[part 2 of 2: packages /Cluster to /PDU]
AUTOSAR XML (schema 00048)
package /Cluster  (continued)
  can cluster KAMA_FP_EPT_0303: baudrate=500000, protocol-name=CAN  # KAMA_FP_EPT_0409
    can physical channel CHNL: comm-connectors=CN_KAMA_FP_EPT_0303
      frame AllFunctionRequest_oKAMA_FP_EPT_0303: id 0x7FF, to VCU, frame-length=8, can-addressing-mode=STANDARD
        n pdu AllFunctionRequest_Tp_oKAMA_FP_EPT_0303: length=8
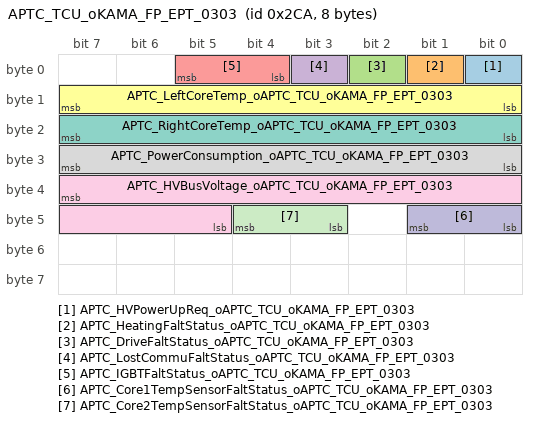
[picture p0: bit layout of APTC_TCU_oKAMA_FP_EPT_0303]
      frame APTC_TCU_oKAMA_FP_EPT_0303: id 0x2CA, to VCU, frame-length=8, can-addressing-mode=STANDARD
        pdu APTC_TCU_oKAMA_FP_EPT_0303: length=8, minimum-delay=0, transmission-mode-false-timing=cyclic-timing={time-offset=0, time-period=0.1}, transmission-mode-true-timing=cyclic-timing={time-offset=0, time-period=0.1}, unused-bit-pattern=0
          signal APTC_HVPowerUpReq_oAPTC_TCU_oKAMA_FP_EPT_0303: start 0, 1 bit, big-endian, i-signal-type=PRIMITIVE, init-value=0, base-type=boolean, compu-method=CM_APTC_HVPowerUpReq, data-constr=DC_APTC_HVPowerUpReq, transfer-property=PENDING, to VCU  # APTC high voltage power supply off line request APTC ¸ßÑ¹ÏÂÏßÇëÇó
          signal APTC_HeatingFaltStatus_oAPTC_TCU_oKAMA_FP_EPT_0303: start 1, 1 bit, big-endian, i-signal-type=PRIMITIVE, init-value=0, base-type=boolean, compu-method=CM_APTC_HeatingFaltStatus, data-constr=DC_APTC_HeatingFaltStatus, transfer-property=PENDING, to VCU  # ptc heater core status
          signal APTC_DriveFaltStatus_oAPTC_TCU_oKAMA_FP_EPT_0303: start 2, 1 bit, big-endian, i-signal-type=PRIMITIVE, init-value=0, base-type=boolean, compu-method=CM_APTC_DriveFaltStatus, data-constr=DC_APTC_DriveFaltStatus, transfer-property=PENDING, to VCU  # ptc driver status
          signal APTC_LostCommuFaltStatus_oAPTC_TCU_oKAMA_FP_EPT_0303: start 3, 1 bit, big-endian, i-signal-type=PRIMITIVE, init-value=0, base-type=boolean, compu-method=CM_APTC_LostCommuFaltStatus, data-constr=DC_APTC_LostCommuFaltStatus, transfer-property=PENDING, to VCU  # TCU signal lost
          signal APTC_IGBTFaltStatus_oAPTC_TCU_oKAMA_FP_EPT_0303: start 5, 2 bit, big-endian, i-signal-type=PRIMITIVE, init-value=0, base-type=uint8, compu-method=CM_APTC_IGBTFaltStatus, data-constr=DC_APTC_IGBTFaltStatus, transfer-property=PENDING, to VCU  # IGBT failure
          signal APTC_LeftCoreTemp_oAPTC_TCU_oKAMA_FP_EPT_0303: start 15, 8 bit, big-endian, i-signal-type=PRIMITIVE, init-value=40, base-type=uint8, compu-method=CM_APTC_LeftCoreTemp, data-constr=DC_APTC_LeftCoreTemp, unit=U_deg, transfer-property=PENDING, to VCU  # Left core sensor temperature ×ó²àÐ¾ÌåÎÂ¶È´«¸ÐÆ÷ÎÂ¶È
          signal APTC_RightCoreTemp_oAPTC_TCU_oKAMA_FP_EPT_0303: start 23, 8 bit, big-endian, i-signal-type=PRIMITIVE, init-value=40, base-type=uint8, compu-method=CM_APTC_RightCoreTemp, data-constr=DC_APTC_RightCoreTemp, unit=U_deg, transfer-property=PENDING, to VCU  # Right core sensor temperature ÓÒ²àÐ¾ÌåÎÂ¶È´«¸ÐÆ÷ÎÂ¶È
          signal APTC_PowerConsumption_oAPTC_TCU_oKAMA_FP_EPT_0303: start 31, 8 bit, big-endian, i-signal-type=PRIMITIVE, init-value=0, base-type=uint8, compu-method=CM_APTC_PowerConsumption, data-constr=DC_APTC_PowerConsumption, unit=U_KW, transfer-property=PENDING, to VCU  # APTC OutPut Power APTC Êä³ö¹¦ÂÊ
          signal APTC_HVBusVoltage_oAPTC_TCU_oKAMA_FP_EPT_0303: start 39, 11 bit, big-endian, i-signal-type=PRIMITIVE, init-value=0, base-type=uint16, compu-method=CM_APTC_HVBusVoltage, data-constr=DC_APTC_HVBusVoltage, unit=U_V, transfer-property=PENDING, to VCU  # HV voltage ¸ßÑ¹µçÑ¹Öµ
          signal APTC_Core1TempSensorFaltStatus_oAPTC_TCU_oKAMA_FP_EPT_0303: start 41, 2 bit, big-endian, i-signal-type=PRIMITIVE, init-value=0, base-type=uint8, compu-method=CM_APTC_Core1TempSensorFaltStatus, data-constr=DC_APTC_Core1TempSensorFaltStatus, transfer-property=PENDING, to VCU  # Left core sensor temperature error
          signal APTC_Core2TempSensorFaltStatus_oAPTC_TCU_oKAMA_FP_EPT_0303: start 44, 2 bit, big-endian, i-signal-type=PRIMITIVE, init-value=0, base-type=uint8, compu-method=CM_APTC_Core2TempSensorFaltStatus, data-constr=DC_APTC_Core2TempSensorFaltStatus, transfer-property=PENDING, to VCU  # Right core sensor temperature error
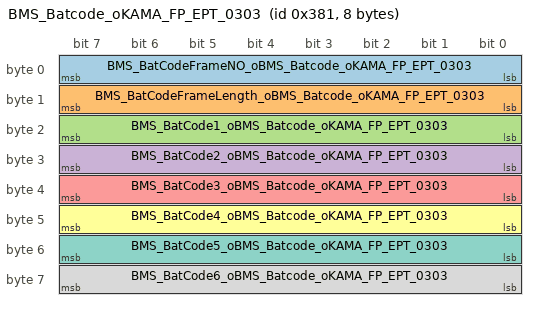
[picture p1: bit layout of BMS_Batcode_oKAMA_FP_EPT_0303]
      frame BMS_Batcode_oKAMA_FP_EPT_0303: id 0x381, to VCU, frame-length=8, can-addressing-mode=STANDARD
        pdu BMS_Batcode_oKAMA_FP_EPT_0303: length=8, minimum-delay=0, transmission-mode-false-timing=cyclic-timing={time-offset=0, time-period=1}, transmission-mode-true-timing=cyclic-timing={time-offset=0, time-period=1}, unused-bit-pattern=0
          signal BMS_BatCodeFrameNO_oBMS_Batcode_oKAMA_FP_EPT_0303: start 7, 8 bit, big-endian, i-signal-type=PRIMITIVE, init-value=0, base-type=uint8, compu-method=CM_BMS_BatCodeFrameNO, data-constr=DC_BMS_BatCodeFrameNO, transfer-property=PENDING, to VCU  # BatteryCodeNumber
          signal BMS_BatCodeFrameLength_oBMS_Batcode_oKAMA_FP_EPT_0303: start 15, 8 bit, big-endian, i-signal-type=PRIMITIVE, init-value=0, base-type=uint8, compu-method=CM_BMS_BatCodeFrameLength, data-constr=DC_BMS_BatCodeFrameLength, transfer-property=PENDING, to VCU  # Length of battery code
          signal BMS_BatCode1_oBMS_Batcode_oKAMA_FP_EPT_0303: start 23, 8 bit, big-endian, i-signal-type=PRIMITIVE, init-value=0, base-type=uint8, compu-method=CM_BMS_BatCode1, data-constr=DC_BMS_BatCode1, transfer-property=PENDING, to VCU
          signal BMS_BatCode2_oBMS_Batcode_oKAMA_FP_EPT_0303: start 31, 8 bit, big-endian, i-signal-type=PRIMITIVE, init-value=0, base-type=uint8, compu-method=CM_BMS_BatCode2, data-constr=DC_BMS_BatCode2, transfer-property=PENDING, to VCU
          signal BMS_BatCode3_oBMS_Batcode_oKAMA_FP_EPT_0303: start 39, 8 bit, big-endian, i-signal-type=PRIMITIVE, init-value=0, base-type=uint8, compu-method=CM_BMS_BatCode3, data-constr=DC_BMS_BatCode3, transfer-property=PENDING, to VCU
          signal BMS_BatCode4_oBMS_Batcode_oKAMA_FP_EPT_0303: start 47, 8 bit, big-endian, i-signal-type=PRIMITIVE, init-value=0, base-type=uint8, compu-method=CM_BMS_BatCode4, data-constr=DC_BMS_BatCode4, transfer-property=PENDING, to VCU
          signal BMS_BatCode5_oBMS_Batcode_oKAMA_FP_EPT_0303: start 55, 8 bit, big-endian, i-signal-type=PRIMITIVE, init-value=0, base-type=uint8, compu-method=CM_BMS_BatCode5, data-constr=DC_BMS_BatCode5, transfer-property=PENDING, to VCU
          signal BMS_BatCode6_oBMS_Batcode_oKAMA_FP_EPT_0303: start 63, 8 bit, big-endian, i-signal-type=PRIMITIVE, init-value=0, base-type=uint8, compu-method=CM_BMS_BatCode6, data-constr=DC_BMS_BatCode6, transfer-property=PENDING, to VCU
      frame BMS_BatInfor1_oKAMA_FP_EPT_0303: id 0xAF, to VCU, frame-length=8, can-addressing-mode=STANDARD
        pdu BMS_BatInfor1_oKAMA_FP_EPT_0303: length=8, minimum-delay=0, transmission-mode-false-timing=cyclic-timing={time-offset=0, time-period=0.02}, transmission-mode-true-timing=cyclic-timing={time-offset=0, time-period=0.02}, unused-bit-pattern=0
          signal BMS_BattVolt_oBMS_BatInfor1_oKAMA_FP_EPT_0303: start 7, 14 bit, big-endian, i-signal-type=PRIMITIVE, init-value=0, base-type=uint16, compu-method=CM_BMS_BattVolt, data-constr=DC_BMS_BattVolt, transfer-property=PENDING, to VCU  # the voltage of dclink from BMS sideµç³ØÄ¸ÏßµçÑ¹
          signal BMS_BattCurr_oBMS_BatInfor1_oKAMA_FP_EPT_0303: start 23, 15 bit, big-endian, i-signal-type=PRIMITIVE, init-value=10240, base-type=uint16, compu-method=CM_BMS_BattCurr, data-constr=DC_BMS_BattCurr, transfer-property=PENDING, to VCU  # the current of dclink from BMS sideµç³ØÄ¸ÏßµçÁ÷
          signal MessageCounter_AF_oBMS_BatInfor1_oKAMA_FP_EPT_0303: start 51, 4 bit, big-endian, i-signal-type=PRIMITIVE, init-value=0, base-type=uint8, compu-method=CM_MessageCounter_AF, data-constr=DC_MessageCounter_AF, transfer-property=PENDING, to VCU  # Message counter signal for frame
          signal Checksum_AF_oBMS_BatInfor1_oKAMA_FP_EPT_0303: start 63, 8 bit, big-endian, i-signal-type=PRIMITIVE, init-value=0, base-type=uint8, compu-method=CM_Checksum_AF, data-constr=DC_Checksum_AF, transfer-property=PENDING, to VCU  # Checksum signal for frame
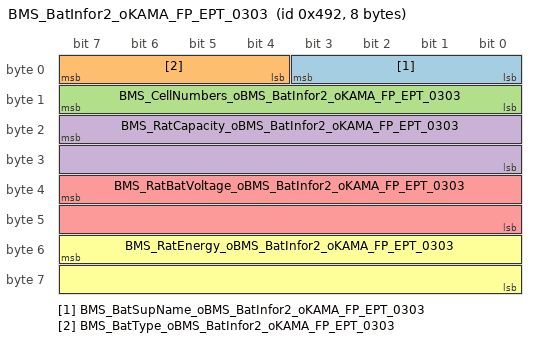
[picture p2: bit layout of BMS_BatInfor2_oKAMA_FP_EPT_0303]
      frame BMS_BatInfor2_oKAMA_FP_EPT_0303: id 0x492, to VCU, frame-length=8, can-addressing-mode=STANDARD
        pdu BMS_BatInfor2_oKAMA_FP_EPT_0303: length=8, minimum-delay=0, transmission-mode-false-timing=cyclic-timing={time-offset=0, time-period=1}, transmission-mode-true-timing=cyclic-timing={time-offset=0, time-period=1}, unused-bit-pattern=0
          signal BMS_BatSupName_oBMS_BatInfor2_oKAMA_FP_EPT_0303: start 3, 4 bit, big-endian, i-signal-type=PRIMITIVE, init-value=0, base-type=uint8, compu-method=CM_BMS_BatSupName, data-constr=DC_BMS_BatSupName, transfer-property=PENDING, to VCU  # Battery supplier name
          signal BMS_BatType_oBMS_BatInfor2_oKAMA_FP_EPT_0303: start 7, 4 bit, big-endian, i-signal-type=PRIMITIVE, init-value=0, base-type=uint8, compu-method=CM_BMS_BatType, data-constr=DC_BMS_BatType, transfer-property=PENDING, to VCU  # Battery type
          signal BMS_CellNumbers_oBMS_BatInfor2_oKAMA_FP_EPT_0303: start 15, 8 bit, big-endian, i-signal-type=PRIMITIVE, init-value=0, base-type=uint8, compu-method=CM_BMS_CellNumbers, data-constr=DC_BMS_CellNumbers, transfer-property=PENDING, to VCU  # Sum of cell in pack
          signal BMS_RatCapacity_oBMS_BatInfor2_oKAMA_FP_EPT_0303: start 23, 16 bit, big-endian, i-signal-type=PRIMITIVE, init-value=0, base-type=uint16, compu-method=CM_BMS_RatCapacity, data-constr=DC_BMS_RatCapacity, unit=U_Ah, transfer-property=PENDING, to VCU  # Rated capacity of power battery system
          signal BMS_RatBatVoltage_oBMS_BatInfor2_oKAMA_FP_EPT_0303: start 39, 16 bit, big-endian, i-signal-type=PRIMITIVE, init-value=0, base-type=uint16, compu-method=CM_BMS_RatBatVoltage, data-constr=DC_BMS_RatBatVoltage, unit=U_V, transfer-property=PENDING, to VCU  # Rated Voltage of power battery system
          signal BMS_RatEnergy_oBMS_BatInfor2_oKAMA_FP_EPT_0303: start 55, 16 bit, big-endian, i-signal-type=PRIMITIVE, init-value=0, base-type=uint16, compu-method=CM_BMS_RatEnergy, data-constr=DC_BMS_RatEnergy, unit=U_KWH, transfer-property=PENDING, to VCU  # Nominal total energy of power battery
      frame BMS_CellVoltage1_oKAMA_FP_EPT_0303: id 0x29A, to VCU, frame-length=8, can-addressing-mode=STANDARD
        pdu BMS_CellVoltage1_oKAMA_FP_EPT_0303: length=8, minimum-delay=0, transmission-mode-false-timing=cyclic-timing={time-offset=0, time-period=0.1}, transmission-mode-true-timing=cyclic-timing={time-offset=0, time-period=0.1}, unused-bit-pattern=0
          signal BMS_MaxCellVoltage_oBMS_CellVoltage1_oKAMA_FP_EPT_0303: start 7, 16 bit, big-endian, i-signal-type=PRIMITIVE, init-value=0, base-type=uint16, compu-method=CM_BMS_MaxCellVoltage, data-constr=DC_BMS_MaxCellVoltage, unit=U_V, transfer-property=PENDING, to VCU  # The Maximal Cell Voltage
          signal BMS_MinCellVoltage_oBMS_CellVoltage1_oKAMA_FP_EPT_0303: start 23, 16 bit, big-endian, i-signal-type=PRIMITIVE, init-value=0, base-type=uint16, compu-method=CM_BMS_MinCellVoltage, data-constr=DC_BMS_MinCellVoltage, unit=U_V, transfer-property=PENDING, to VCU  # The Minimal Cell Voltage
          signal BMS_MinCellVoltageModlueNO_oBMS_CellVoltage1_oKAMA_FP_EPT_0303: start 35, 4 bit, big-endian, i-signal-type=PRIMITIVE, init-value=0, base-type=uint8, compu-method=CM_BMS_MinCellVoltageModlueNO, data-constr=DC_BMS_MinCellVoltageModlueNO, transfer-property=PENDING, to VCU  # Minimal Cell Voltage module NO
          signal BMS_MaxCellVoltageModuleNO_oBMS_CellVoltage1_oKAMA_FP_EPT_0303: start 39, 4 bit, big-endian, i-signal-type=PRIMITIVE, init-value=0, base-type=uint8, compu-method=CM_BMS_MaxCellVoltageModuleNO, data-constr=DC_BMS_MaxCellVoltageModuleNO, transfer-property=PENDING, to VCU  # Maximal Cell Voltage module NO
          signal BMS_MaxCellVoltageNO_oBMS_CellVoltage1_oKAMA_FP_EPT_0303: start 47, 8 bit, big-endian, i-signal-type=PRIMITIVE, init-value=0, base-type=uint8, compu-method=CM_BMS_MaxCellVoltageNO, data-constr=DC_BMS_MaxCellVoltageNO, transfer-property=PENDING, to VCU  # The Maximal Cell Voltage NO
          signal BMS_MinCellVoltageNO_oBMS_CellVoltage1_oKAMA_FP_EPT_0303: start 55, 8 bit, big-endian, i-signal-type=PRIMITIVE, init-value=0, base-type=uint8, compu-method=CM_BMS_MinCellVoltageNO, data-constr=DC_BMS_MinCellVoltageNO, transfer-property=PENDING, to VCU  # The Minimal Cell Voltage NO
      frame BMS_Charge1_oKAMA_FP_EPT_0303: id 0x295, to VCU, frame-length=8, can-addressing-mode=STANDARD
        pdu BMS_Charge1_oKAMA_FP_EPT_0303: length=8, minimum-delay=0, transmission-mode-false-timing=cyclic-timing={time-offset=0, time-period=0.1}, transmission-mode-true-timing=cyclic-timing={time-offset=0, time-period=0.1}, unused-bit-pattern=0
          signal BMS_RemChagTime_oBMS_Charge1_oKAMA_FP_EPT_0303: start 7, 16 bit, big-endian, i-signal-type=PRIMITIVE, init-value=0, base-type=uint16, compu-method=CM_BMS_RemChagTime, data-constr=DC_BMS_RemChagTime, unit=U_Min, transfer-property=PENDING, to VCU  # Remaining charging time prediction in minute
          signal BMS_MaxChagVoltage_oBMS_Charge1_oKAMA_FP_EPT_0303: start 23, 16 bit, big-endian, i-signal-type=PRIMITIVE, init-value=0, base-type=uint16, compu-method=CM_BMS_MaxChagVoltage, data-constr=DC_BMS_MaxChagVoltage, unit=U_V, transfer-property=PENDING, to VCU  # Maximum allowable charging voltage
          signal BMS_AllowChagCurrent_oBMS_Charge1_oKAMA_FP_EPT_0303: start 55, 16 bit, big-endian, i-signal-type=PRIMITIVE, init-value=10000, base-type=uint16, compu-method=CM_BMS_AllowChagCurrent, data-constr=DC_BMS_AllowChagCurrent, unit=U_A, transfer-property=PENDING, to VCU  # Maximum allowable charging current
      frame BMS_ChargeEnergy_oKAMA_FP_EPT_0303: id 0x493, to VCU, frame-length=8, can-addressing-mode=STANDARD
        pdu BMS_ChargeEnergy_oKAMA_FP_EPT_0303: length=8, minimum-delay=0, transmission-mode-false-timing=cyclic-timing={time-offset=0, time-period=1}, transmission-mode-true-timing=cyclic-timing={time-offset=0, time-period=1}, unused-bit-pattern=0
          signal BMS_SingChgkwh_oBMS_ChargeEnergy_oKAMA_FP_EPT_0303: start 7, 8 bit, big-endian, i-signal-type=PRIMITIVE, init-value=0, base-type=uint8, compu-method=CM_BMS_SingChgkwh, data-constr=DC_BMS_SingChgkwh, unit=U_KWH, transfer-property=PENDING, to VCU  # Single charged electric quantity (charger online)
          signal BMS_SumChgkwh_oBMS_ChargeEnergy_oKAMA_FP_EPT_0303: start 15, 24 bit, big-endian, i-signal-type=PRIMITIVE, init-value=0, base-type=uint32, compu-method=CM_BMS_SumChgkwh, data-constr=DC_BMS_SumChgkwh, unit=U_KWH, transfer-property=PENDING, to VCU  # Accumulated charged electric quantity
          signal BMS_BatChagSum_oBMS_ChargeEnergy_oKAMA_FP_EPT_0303: start 39, 16 bit, big-endian, i-signal-type=PRIMITIVE, init-value=0, base-type=uint16, compu-method=CM_BMS_BatChagSum, data-constr=DC_BMS_BatChagSum, transfer-property=PENDING, to VCU  # Sum of how many cycle for battery charged
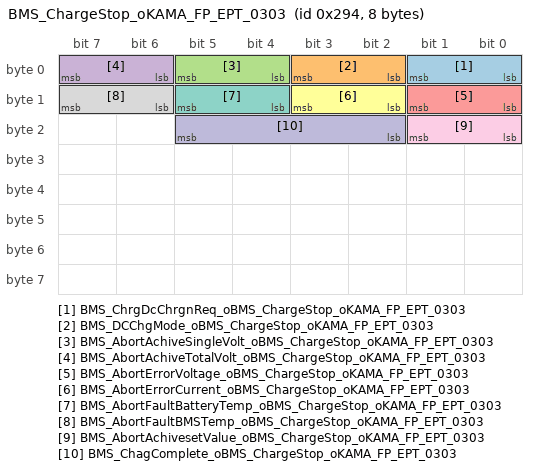
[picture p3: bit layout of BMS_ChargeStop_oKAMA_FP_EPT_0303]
      frame BMS_ChargeStop_oKAMA_FP_EPT_0303: id 0x294, to VCU, frame-length=8, can-addressing-mode=STANDARD
        pdu BMS_ChargeStop_oKAMA_FP_EPT_0303: length=8, minimum-delay=0, transmission-mode-false-timing=cyclic-timing={time-offset=0, time-period=0.1}, transmission-mode-true-timing=cyclic-timing={time-offset=0, time-period=0.1}, unused-bit-pattern=0
          signal BMS_ChrgDcChrgnReq_oBMS_ChargeStop_oKAMA_FP_EPT_0303: start 1, 2 bit, big-endian, i-signal-type=PRIMITIVE, init-value=0, base-type=uint8, compu-method=CM_BMS_ChrgDcChrgnReq, data-constr=DC_BMS_ChrgDcChrgnReq, transfer-property=PENDING, to VCU
          signal BMS_DCChgMode_oBMS_ChargeStop_oKAMA_FP_EPT_0303: start 3, 2 bit, big-endian, i-signal-type=PRIMITIVE, init-value=0, base-type=uint8, compu-method=CM_BMS_DCChgMode, data-constr=DC_BMS_DCChgMode, transfer-property=PENDING, to VCU
          signal BMS_AbortAchiveSingleVolt_oBMS_ChargeStop_oKAMA_FP_EPT_0303: start 5, 2 bit, big-endian, i-signal-type=PRIMITIVE, init-value=0, base-type=uint8, compu-method=CM_BMS_AbortAchiveSingleVolt, data-constr=DC_BMS_AbortAchiveSingleVolt, transfer-property=PENDING, to VCU
          signal BMS_AbortAchiveTotalVolt_oBMS_ChargeStop_oKAMA_FP_EPT_0303: start 7, 2 bit, big-endian, i-signal-type=PRIMITIVE, init-value=0, base-type=uint8, compu-method=CM_BMS_AbortAchiveTotalVolt, data-constr=DC_BMS_AbortAchiveTotalVolt, transfer-property=PENDING, to VCU
          signal BMS_AbortErrorVoltage_oBMS_ChargeStop_oKAMA_FP_EPT_0303: start 9, 2 bit, big-endian, i-signal-type=PRIMITIVE, init-value=0, base-type=uint8, compu-method=CM_BMS_AbortErrorVoltage, data-constr=DC_BMS_AbortErrorVoltage, transfer-property=PENDING, to VCU
          signal BMS_AbortErrorCurrent_oBMS_ChargeStop_oKAMA_FP_EPT_0303: start 11, 2 bit, big-endian, i-signal-type=PRIMITIVE, init-value=0, base-type=uint8, compu-method=CM_BMS_AbortErrorCurrent, data-constr=DC_BMS_AbortErrorCurrent, transfer-property=PENDING, to VCU
          signal BMS_AbortFaultBatteryTemp_oBMS_ChargeStop_oKAMA_FP_EPT_0303: start 13, 2 bit, big-endian, i-signal-type=PRIMITIVE, init-value=0, base-type=uint8, compu-method=CM_BMS_AbortFaultBatteryTemp, data-constr=DC_BMS_AbortFaultBatteryTemp, transfer-property=PENDING, to VCU
          signal BMS_AbortFaultBMSTemp_oBMS_ChargeStop_oKAMA_FP_EPT_0303: start 15, 2 bit, big-endian, i-signal-type=PRIMITIVE, init-value=0, base-type=uint8, compu-method=CM_BMS_AbortFaultBMSTemp, data-constr=DC_BMS_AbortFaultBMSTemp, transfer-property=PENDING, to VCU
          signal BMS_AbortAchivesetValue_oBMS_ChargeStop_oKAMA_FP_EPT_0303: start 17, 2 bit, big-endian, i-signal-type=PRIMITIVE, init-value=0, base-type=uint8, compu-method=CM_BMS_AbortAchivesetValue, data-constr=DC_BMS_AbortAchivesetValue, transfer-property=PENDING, to VCU
          signal BMS_ChagComplete_oBMS_ChargeStop_oKAMA_FP_EPT_0303: start 21, 4 bit, big-endian, i-signal-type=PRIMITIVE, init-value=0, base-type=uint8, compu-method=CM_BMS_ChagComplete, data-constr=DC_BMS_ChagComplete, transfer-property=PENDING, to VCU
      frame BMS_CurrentLimit_oKAMA_FP_EPT_0303: id 0x296, to VCU, frame-length=8, can-addressing-mode=STANDARD
        pdu BMS_CurrentLimit_oKAMA_FP_EPT_0303: length=8, minimum-delay=0, transmission-mode-false-timing=cyclic-timing={time-offset=0, time-period=0.1}, transmission-mode-true-timing=cyclic-timing={time-offset=0, time-period=0.1}, unused-bit-pattern=0
          signal BMS_FeedbackCurr_oBMS_CurrentLimit_oKAMA_FP_EPT_0303: start 7, 16 bit, big-endian, i-signal-type=PRIMITIVE, init-value=10000, base-type=uint16, compu-method=CM_BMS_FeedbackCurr, data-constr=DC_BMS_FeedbackCurr, unit=U_A, transfer-property=PENDING, to VCU  # Maximum feed back charging current(30S)
          signal BMS_DisChgCurr_oBMS_CurrentLimit_oKAMA_FP_EPT_0303: start 39, 16 bit, big-endian, i-signal-type=PRIMITIVE, init-value=10000, base-type=uint16, compu-method=CM_BMS_DisChgCurr, data-constr=DC_BMS_DisChgCurr, unit=U_A, transfer-property=PENDING, to VCU  # Constant discharging current
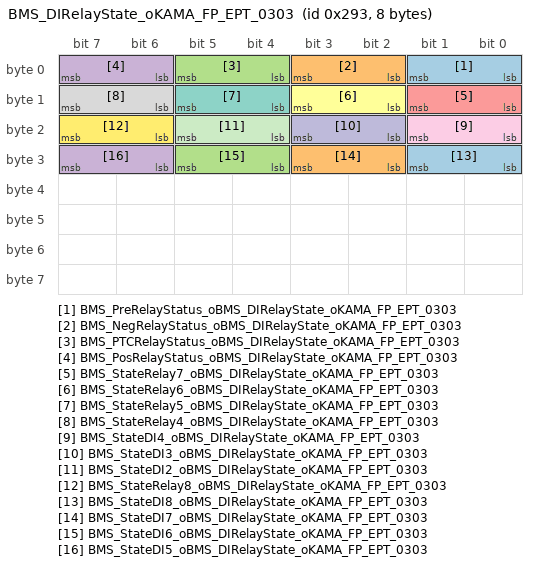
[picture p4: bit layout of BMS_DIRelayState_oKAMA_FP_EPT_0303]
      frame BMS_DIRelayState_oKAMA_FP_EPT_0303: id 0x293, to VCU, frame-length=8, can-addressing-mode=STANDARD
        pdu BMS_DIRelayState_oKAMA_FP_EPT_0303: length=8, minimum-delay=0, transmission-mode-false-timing=cyclic-timing={time-offset=0, time-period=0.1}, transmission-mode-true-timing=cyclic-timing={time-offset=0, time-period=0.1}, unused-bit-pattern=0
          signal BMS_PreRelayStatus_oBMS_DIRelayState_oKAMA_FP_EPT_0303: start 1, 2 bit, big-endian, i-signal-type=PRIMITIVE, init-value=0, base-type=uint8, compu-method=CM_BMS_PreRelayStatus, data-constr=DC_BMS_PreRelayStatus, transfer-property=PENDING, to VCU  # State of precharge relay status
          signal BMS_NegRelayStatus_oBMS_DIRelayState_oKAMA_FP_EPT_0303: start 3, 2 bit, big-endian, i-signal-type=PRIMITIVE, init-value=0, base-type=uint8, compu-method=CM_BMS_NegRelayStatus, data-constr=DC_BMS_NegRelayStatus, transfer-property=PENDING, to VCU  # State of negtive relay status
          signal BMS_PTCRelayStatus_oBMS_DIRelayState_oKAMA_FP_EPT_0303: start 5, 2 bit, big-endian, i-signal-type=PRIMITIVE, init-value=0, base-type=uint8, compu-method=CM_BMS_PTCRelayStatus, data-constr=DC_BMS_PTCRelayStatus, transfer-property=PENDING, to VCU  # the status of PTC relay from BMS sideµç³ØPTC¼ÌµçÆ÷×´Ì¬
          signal BMS_PosRelayStatus_oBMS_DIRelayState_oKAMA_FP_EPT_0303: start 7, 2 bit, big-endian, i-signal-type=PRIMITIVE, init-value=0, base-type=uint8, compu-method=CM_BMS_PosRelayStatus, data-constr=DC_BMS_PosRelayStatus, transfer-property=PENDING, to VCU  # State of positive relay status
          signal BMS_StateRelay7_oBMS_DIRelayState_oKAMA_FP_EPT_0303: start 9, 2 bit, big-endian, i-signal-type=PRIMITIVE, init-value=0, base-type=uint8, compu-method=CM_BMS_StateRelay7, data-constr=DC_BMS_StateRelay7, transfer-property=PENDING, to VCU  # State of relay 7
          signal BMS_StateRelay6_oBMS_DIRelayState_oKAMA_FP_EPT_0303: start 11, 2 bit, big-endian, i-signal-type=PRIMITIVE, init-value=0, base-type=uint8, compu-method=CM_BMS_StateRelay6, data-constr=DC_BMS_StateRelay6, transfer-property=PENDING, to VCU  # State of relay 6
          signal BMS_StateRelay5_oBMS_DIRelayState_oKAMA_FP_EPT_0303: start 13, 2 bit, big-endian, i-signal-type=PRIMITIVE, init-value=0, base-type=uint8, compu-method=CM_BMS_StateRelay5, data-constr=DC_BMS_StateRelay5, transfer-property=PENDING, to VCU  # State of relay 5
          signal BMS_StateRelay4_oBMS_DIRelayState_oKAMA_FP_EPT_0303: start 15, 2 bit, big-endian, i-signal-type=PRIMITIVE, init-value=0, base-type=uint8, compu-method=CM_BMS_StateRelay4, data-constr=DC_BMS_StateRelay4, transfer-property=PENDING, to VCU  # State of relay 4
          signal BMS_StateDI4_oBMS_DIRelayState_oKAMA_FP_EPT_0303: start 17, 2 bit, big-endian, i-signal-type=PRIMITIVE, init-value=0, base-type=uint8, compu-method=CM_BMS_StateDI4, data-constr=DC_BMS_StateDI4, transfer-property=PENDING, to VCU  # State of DI 4
          signal BMS_StateDI3_oBMS_DIRelayState_oKAMA_FP_EPT_0303: start 19, 2 bit, big-endian, i-signal-type=PRIMITIVE, init-value=0, base-type=uint8, compu-method=CM_BMS_StateDI3, data-constr=DC_BMS_StateDI3, transfer-property=PENDING, to VCU  # State of DI 3
          signal BMS_StateDI2_oBMS_DIRelayState_oKAMA_FP_EPT_0303: start 21, 2 bit, big-endian, i-signal-type=PRIMITIVE, init-value=0, base-type=uint8, compu-method=CM_BMS_StateDI2, data-constr=DC_BMS_StateDI2, transfer-property=PENDING, to VCU  # State of DI 2
          signal BMS_StateRelay8_oBMS_DIRelayState_oKAMA_FP_EPT_0303: start 23, 2 bit, big-endian, i-signal-type=PRIMITIVE, init-value=0, base-type=uint8, compu-method=CM_BMS_StateRelay8, data-constr=DC_BMS_StateRelay8, transfer-property=PENDING, to VCU  # State of relay 8
          signal BMS_StateDI8_oBMS_DIRelayState_oKAMA_FP_EPT_0303: start 25, 2 bit, big-endian, i-signal-type=PRIMITIVE, init-value=0, base-type=uint8, compu-method=CM_BMS_StateDI8, data-constr=DC_BMS_StateDI8, transfer-property=PENDING, to VCU  # State of DI 8
          signal BMS_StateDI7_oBMS_DIRelayState_oKAMA_FP_EPT_0303: start 27, 2 bit, big-endian, i-signal-type=PRIMITIVE, init-value=0, base-type=uint8, compu-method=CM_BMS_StateDI7, data-constr=DC_BMS_StateDI7, transfer-property=PENDING, to VCU  # State of DI 7
          signal BMS_StateDI6_oBMS_DIRelayState_oKAMA_FP_EPT_0303: start 29, 2 bit, big-endian, i-signal-type=PRIMITIVE, init-value=0, base-type=uint8, compu-method=CM_BMS_StateDI6, data-constr=DC_BMS_StateDI6, transfer-property=PENDING, to VCU  # State of DI 6
          signal BMS_StateDI5_oBMS_DIRelayState_oKAMA_FP_EPT_0303: start 31, 2 bit, big-endian, i-signal-type=PRIMITIVE, init-value=0, base-type=uint8, compu-method=CM_BMS_StateDI5, data-constr=DC_BMS_StateDI5, transfer-property=PENDING, to VCU  # State of DI 5
      frame BMS_DisChargeEnergy_oKAMA_FP_EPT_0303: id 0x494, to VCU, frame-length=8, can-addressing-mode=STANDARD
        pdu BMS_DisChargeEnergy_oKAMA_FP_EPT_0303: length=8, minimum-delay=0, transmission-mode-false-timing=cyclic-timing={time-offset=0, time-period=0.1}, transmission-mode-true-timing=cyclic-timing={time-offset=0, time-period=0.1}, unused-bit-pattern=0
          signal BMS_SumDisChgkwh_oBMS_DisChargeEnergy_oKAMA_FP_EPT_0303: start 7, 24 bit, big-endian, i-signal-type=PRIMITIVE, init-value=0, base-type=uint32, compu-method=CM_BMS_SumDisChgkwh, data-constr=DC_BMS_SumDisChgkwh, unit=U_KWH, transfer-property=PENDING, to VCU  # Accumulated discharged electric quantity
          signal BMS_RemainCapacity_oBMS_DisChargeEnergy_oKAMA_FP_EPT_0303: start 31, 8 bit, big-endian, i-signal-type=PRIMITIVE, init-value=0, base-type=uint8, compu-method=CM_BMS_RemainCapacity, data-constr=DC_BMS_RemainCapacity, unit=U_Ah, transfer-property=PENDING, to VCU  # Real-time remaining battery capacity
      frame BMS_ErrorInfo1_oKAMA_FP_EPT_0303: id 0x382, to VCU, frame-length=8, can-addressing-mode=STANDARD
        pdu BMS_ErrorInfo1_oKAMA_FP_EPT_0303: length=8, minimum-delay=0, transmission-mode-false-timing=cyclic-timing={time-offset=0, time-period=0.2}, transmission-mode-true-timing=cyclic-timing={time-offset=0, time-period=0.2}, unused-bit-pattern=0
          signal BMS_ErrorCellLowTemp_oBMS_ErrorInfo1_oKAMA_FP_EPT_0303: start 1, 2 bit, big-endian, i-signal-type=PRIMITIVE, init-value=0, base-type=uint8, compu-method=CM_BMS_ErrorCellLowTemp, data-constr=DC_BMS_ErrorCellLowTemp, transfer-property=PENDING, to VCU  # Cell temperature under limit
          signal BMS_ErrorCellHighTemp_oBMS_ErrorInfo1_oKAMA_FP_EPT_0303: start 3, 2 bit, big-endian, i-signal-type=PRIMITIVE, init-value=0, base-type=uint8, compu-method=CM_BMS_ErrorCellHighTemp, data-constr=DC_BMS_ErrorCellHighTemp, transfer-property=PENDING, to VCU  # Cell temperature over limit
          signal BMS_ErrorCellUnderVolt_oBMS_ErrorInfo1_oKAMA_FP_EPT_0303: start 5, 2 bit, big-endian, i-signal-type=PRIMITIVE, init-value=0, base-type=uint8, compu-method=CM_BMS_ErrorCellUnderVolt, data-constr=DC_BMS_ErrorCellUnderVolt, transfer-property=PENDING, to VCU  # Cell voltage under limit
          signal BMS_ErrorCellOverVolt_oBMS_ErrorInfo1_oKAMA_FP_EPT_0303: start 7, 2 bit, big-endian, i-signal-type=PRIMITIVE, init-value=0, base-type=uint8, compu-method=CM_BMS_ErrorCellOverVolt, data-constr=DC_BMS_ErrorCellOverVolt, transfer-property=PENDING, to VCU  # Cell voltage over limit
          signal BMS_ErrorDisChaCurrentOver_oBMS_ErrorInfo1_oKAMA_FP_EPT_0303: start 9, 2 bit, big-endian, i-signal-type=PRIMITIVE, init-value=0, base-type=uint8, compu-method=CM_BMS_ErrorDisChaCurrentOver, data-constr=DC_BMS_ErrorDisChaCurrentOver, transfer-property=PENDING, to VCU  # Battery discharge current over limit
          signal BMS_ErrorChaCurrentOver_oBMS_ErrorInfo1_oKAMA_FP_EPT_0303: start 11, 2 bit, big-endian, i-signal-type=PRIMITIVE, init-value=0, base-type=uint8, compu-method=CM_BMS_ErrorChaCurrentOver, data-constr=DC_BMS_ErrorChaCurrentOver, transfer-property=PENDING, to VCU  # Battery charge current over limit
          signal BMS_ErrorBattUnderVolt_oBMS_ErrorInfo1_oKAMA_FP_EPT_0303: start 13, 2 bit, big-endian, i-signal-type=PRIMITIVE, init-value=0, base-type=uint8, compu-method=CM_BMS_ErrorBattUnderVolt, data-constr=DC_BMS_ErrorBattUnderVolt, transfer-property=PENDING, to VCU  # Battery voltage under limit
          signal BMS_ErrorBattOverVolt_oBMS_ErrorInfo1_oKAMA_FP_EPT_0303: start 15, 2 bit, big-endian, i-signal-type=PRIMITIVE, init-value=0, base-type=uint8, compu-method=CM_BMS_ErrorBattOverVolt, data-constr=DC_BMS_ErrorBattOverVolt, transfer-property=PENDING, to VCU  # Battery voltage over limit
          signal BMS_ErrorCellTempDiff_oBMS_ErrorInfo1_oKAMA_FP_EPT_0303: start 17, 2 bit, big-endian, i-signal-type=PRIMITIVE, init-value=0, base-type=uint8, compu-method=CM_BMS_ErrorCellTempDiff, data-constr=DC_BMS_ErrorCellTempDiff, transfer-property=PENDING, to VCU  # Cell's temperature diffrence between maximal and minimal one is over limit
          signal BMS_ErrorCellVoltDiff_oBMS_ErrorInfo1_oKAMA_FP_EPT_0303: start 19, 2 bit, big-endian, i-signal-type=PRIMITIVE, init-value=0, base-type=uint8, compu-method=CM_BMS_ErrorCellVoltDiff, data-constr=DC_BMS_ErrorCellVoltDiff, transfer-property=PENDING, to VCU  # Cell¡®s voltage diffrence between maximal and minimal one is over limit
          signal BMS_ErrorLeakCurrent_oBMS_ErrorInfo1_oKAMA_FP_EPT_0303: start 21, 2 bit, big-endian, i-signal-type=PRIMITIVE, init-value=0, base-type=uint8, compu-method=CM_BMS_ErrorLeakCurrent, data-constr=DC_BMS_ErrorLeakCurrent, transfer-property=PENDING, to VCU  # Leakage current exceeds the limit
          signal BMS_ErrorBSUOffline_oBMS_ErrorInfo1_oKAMA_FP_EPT_0303: start 23, 1 bit, big-endian, i-signal-type=PRIMITIVE, init-value=0, base-type=boolean, compu-method=CM_BMS_ErrorBSUOffline, data-constr=DC_BMS_ErrorBSUOffline, transfer-property=PENDING, to VCU  # BSU offline
          signal BMS_ErrorBSUBalance_oBMS_ErrorInfo1_oKAMA_FP_EPT_0303: start 24, 1 bit, big-endian, i-signal-type=PRIMITIVE, init-value=0, base-type=boolean, compu-method=CM_BMS_ErrorBSUBalance, data-constr=DC_BMS_ErrorBSUBalance, transfer-property=PENDING, to VCU  # BSU balance fuction error
          signal BMS_ErrorRelay_oBMS_ErrorInfo1_oKAMA_FP_EPT_0303: start 25, 1 bit, big-endian, i-signal-type=PRIMITIVE, init-value=0, base-type=boolean, compu-method=CM_BMS_ErrorRelay, data-constr=DC_BMS_ErrorRelay, transfer-property=PENDING, to VCU  # Relay error
          signal BMS_ErrorPreChaFailed_oBMS_ErrorInfo1_oKAMA_FP_EPT_0303: start 26, 1 bit, big-endian, i-signal-type=PRIMITIVE, init-value=0, base-type=boolean, compu-method=CM_BMS_ErrorPreChaFailed, data-constr=DC_BMS_ErrorPreChaFailed, transfer-property=PENDING, to VCU  # HV precharg failed
          signal BMS_ErrorCellTempOffline_oBMS_ErrorInfo1_oKAMA_FP_EPT_0303: start 27, 1 bit, big-endian, i-signal-type=PRIMITIVE, init-value=0, base-type=boolean, compu-method=CM_BMS_ErrorCellTempOffline, data-constr=DC_BMS_ErrorCellTempOffline, transfer-property=PENDING, to VCU  # Cell temperature detector offline
          signal BMS_ErrorCellVoltOffline_oBMS_ErrorInfo1_oKAMA_FP_EPT_0303: start 28, 1 bit, big-endian, i-signal-type=PRIMITIVE, init-value=0, base-type=boolean, compu-method=CM_BMS_ErrorCellVoltOffline, data-constr=DC_BMS_ErrorCellVoltOffline, transfer-property=PENDING, to VCU  # Cell voltage detector offline
          signal BMS_ErrorHallOffline_oBMS_ErrorInfo1_oKAMA_FP_EPT_0303: start 29, 1 bit, big-endian, i-signal-type=PRIMITIVE, init-value=0, base-type=boolean, compu-method=CM_BMS_ErrorHallOffline, data-constr=DC_BMS_ErrorHallOffline, transfer-property=PENDING, to VCU  # Hall offline
          signal BMS_ErrorBatVolt_oBMS_ErrorInfo1_oKAMA_FP_EPT_0303: start 31, 2 bit, big-endian, i-signal-type=PRIMITIVE, init-value=0, base-type=uint8, compu-method=CM_BMS_ErrorBatVolt, data-constr=DC_BMS_ErrorBatVolt, transfer-property=PENDING, to VCU  # Battery error
          signal BMS_ErrorEmergencyOffCrash_oBMS_ErrorInfo1_oKAMA_FP_EPT_0303: start 32, 1 bit, big-endian, i-signal-type=PRIMITIVE, init-value=0, base-type=boolean, compu-method=CM_BMS_ErrorEmergencyOffCrash, data-constr=DC_BMS_ErrorEmergencyOffCrash, transfer-property=PENDING, to VCU  # Crash signal
          signal BMS_ErrorHVIL_oBMS_ErrorInfo1_oKAMA_FP_EPT_0303: start 33, 1 bit, big-endian, i-signal-type=PRIMITIVE, init-value=0, base-type=boolean, compu-method=CM_BMS_ErrorHVIL, data-constr=DC_BMS_ErrorHVIL, transfer-property=PENDING, to VCU  # HVIL offline
          signal BMS_ErrorSoCJump_RM_oBMS_ErrorInfo1_oKAMA_FP_EPT_0303: start 34, 1 bit, big-endian, i-signal-type=PRIMITIVE, init-value=0, base-type=boolean, compu-method=CM_BMS_ErrorSoCJump_RM, data-constr=DC_BMS_ErrorSoCJump_RM, transfer-property=PENDING, to VCU  # SOC jump
          signal BMS_ErrorHighSoc_oBMS_ErrorInfo1_oKAMA_FP_EPT_0303: start 35, 1 bit, big-endian, i-signal-type=PRIMITIVE, init-value=0, base-type=boolean, compu-method=CM_BMS_ErrorHighSoc, data-constr=DC_BMS_ErrorHighSoc, transfer-property=PENDING, to VCU  # SOC over limit
          signal BMS_ErrorLowSOC_oBMS_ErrorInfo1_oKAMA_FP_EPT_0303: start 37, 2 bit, big-endian, i-signal-type=PRIMITIVE, init-value=0, base-type=uint8, compu-method=CM_BMS_ErrorLowSOC, data-constr=DC_BMS_ErrorLowSOC, transfer-property=PENDING, to VCU  # SOC under limit
          signal BMS_ErrorIsolationSingleLow_oBMS_ErrorInfo1_oKAMA_FP_EPT_0303: start 39, 2 bit, big-endian, i-signal-type=PRIMITIVE, init-value=0, base-type=uint8, compu-method=CM_BMS_ErrorIsolationSingleLow, data-constr=DC_BMS_ErrorIsolationSingleLow, transfer-property=PENDING, to VCU  # The insulation resistance is too low.
          signal BMS_ErrorLeakDet_oBMS_ErrorInfo1_oKAMA_FP_EPT_0303: start 45, 1 bit, big-endian, i-signal-type=PRIMITIVE, init-value=0, base-type=boolean, compu-method=CM_BMS_ErrorLeakDet, data-constr=DC_BMS_ErrorLeakDet, transfer-property=PENDING, to VCU  # Leakage detection
          signal BMS_ErrorSmoke_oBMS_ErrorInfo1_oKAMA_FP_EPT_0303: start 46, 1 bit, big-endian, i-signal-type=PRIMITIVE, init-value=0, base-type=boolean, compu-method=CM_BMS_ErrorSmoke, data-constr=DC_BMS_ErrorSmoke, transfer-property=PENDING, to VCU  # Smoke alarm
          signal BMS_ErrorSystemsMatch_oBMS_ErrorInfo1_oKAMA_FP_EPT_0303: start 47, 1 bit, big-endian, i-signal-type=PRIMITIVE, init-value=0, base-type=boolean, compu-method=CM_BMS_ErrorSystemsMatch, data-constr=DC_BMS_ErrorSystemsMatch, transfer-property=PENDING, to VCU  # BMS not matched alarm
          signal BMS_DTC_oBMS_ErrorInfo1_oKAMA_FP_EPT_0303: start 55, 8 bit, big-endian, i-signal-type=PRIMITIVE, init-value=0, base-type=uint8, compu-method=CM_BMS_DTC, data-constr=DC_BMS_DTC, transfer-property=PENDING, to VCU  # Fault code
          signal BMS_ThermalRunawayFault_oBMS_ErrorInfo1_oKAMA_FP_EPT_0303: start 56, 1 bit, big-endian, i-signal-type=PRIMITIVE, init-value=0, base-type=boolean, compu-method=CM_BMS_ThermalRunawayFault, data-constr=DC_BMS_ThermalRunawayFault, transfer-property=PENDING, to VCU
      frame BMS_Insulation_oKAMA_FP_EPT_0303: id 0x390, to VCU, frame-length=8, can-addressing-mode=STANDARD
        pdu BMS_Insulation_oKAMA_FP_EPT_0303: length=8, minimum-delay=0, transmission-mode-false-timing=cyclic-timing={time-offset=0, time-period=1}, transmission-mode-true-timing=cyclic-timing={time-offset=0, time-period=1}, unused-bit-pattern=0
          signal BMS_SysRegInsulationValue_oBMS_Insulation_oKAMA_FP_EPT_0303: start 39, 16 bit, big-endian, i-signal-type=PRIMITIVE, init-value=0, base-type=uint16, compu-method=CM_BMS_SysRegInsulationValue, data-constr=DC_BMS_SysRegInsulationValue, unit=U_k_, transfer-property=PENDING, to VCU  # BMS system insulation value
          signal BMS_InsulationDetectionStatus_oBMS_Insulation_oKAMA_FP_EPT_0303: start 55, 1 bit, big-endian, i-signal-type=PRIMITIVE, init-value=0, base-type=boolean, compu-method=CM_BMS_InsulationDetectionStatus, data-constr=DC_BMS_InsulationDetectionStatus, transfer-property=PENDING, to VCU  # BMS insulation detection status
      frame BMS_PackVoltage_oKAMA_FP_EPT_0303: id 0x299, to VCU, frame-length=8, can-addressing-mode=STANDARD
        pdu BMS_PackVoltage_oKAMA_FP_EPT_0303: length=8, minimum-delay=0, transmission-mode-false-timing=cyclic-timing={time-offset=0, time-period=0.1}, transmission-mode-true-timing=cyclic-timing={time-offset=0, time-period=0.1}, unused-bit-pattern=0
          signal BMS_PackVoltage_oBMS_PackVoltage_oKAMA_FP_EPT_0303: start 7, 16 bit, big-endian, i-signal-type=PRIMITIVE, init-value=0, base-type=uint16, compu-method=CM_BMS_PackVoltage, data-constr=DC_BMS_PackVoltage, unit=U_V, transfer-property=PENDING, to VCU  # Pack Inside Volt
          signal BMS_LinkVoltage_oBMS_PackVoltage_oKAMA_FP_EPT_0303: start 23, 16 bit, big-endian, i-signal-type=PRIMITIVE, init-value=0, base-type=uint16, compu-method=CM_BMS_LinkVoltage, data-constr=DC_BMS_LinkVoltage, unit=U_V, transfer-property=PENDING, to VCU  # Pack Outside Volt
          signal BMS_SOC_oBMS_PackVoltage_oKAMA_FP_EPT_0303: start 39, 16 bit, big-endian, i-signal-type=PRIMITIVE, init-value=55000, base-type=uint16, compu-method=CM_BMS_SOC, data-constr=DC_BMS_SOC, unit=U_p, transfer-property=PENDING, to VCU  # BMS Real SOC
          signal BMS_DisplaySOC_oBMS_PackVoltage_oKAMA_FP_EPT_0303: start 55, 16 bit, big-endian, i-signal-type=PRIMITIVE, init-value=55000, base-type=uint16, compu-method=CM_BMS_DisplaySOC, data-constr=DC_BMS_DisplaySOC, unit=U_p, transfer-property=PENDING, to VCU  # BMS Display SOC
      frame BMS_PRO_oKAMA_FP_EPT_0303: id 0x3B2, to VCU, frame-length=8, can-addressing-mode=STANDARD
        pdu BMS_PRO_oKAMA_FP_EPT_0303: length=8, minimum-delay=0, transmission-mode-false-timing=cyclic-timing={time-offset=0, time-period=1}, transmission-mode-true-timing=cyclic-timing={time-offset=0, time-period=1}, unused-bit-pattern=0
          signal BMS_BatProDatYear_oBMS_PRO_oKAMA_FP_EPT_0303: start 7, 8 bit, big-endian, i-signal-type=PRIMITIVE, base-type=uint8, compu-method=CM_BMS_BatProDatYear, data-constr=DC_BMS_BatProDatYear, transfer-property=PENDING, to VCU  # Battery pack production date year
          signal BMS_BatProDatMonth_oBMS_PRO_oKAMA_FP_EPT_0303: start 15, 8 bit, big-endian, i-signal-type=PRIMITIVE, init-value=0, base-type=uint8, compu-method=CM_BMS_BatProDatMonth, data-constr=DC_BMS_BatProDatMonth, transfer-property=PENDING, to VCU  # Battery pack production date month
          signal BMS_BatProDatDay_oBMS_PRO_oKAMA_FP_EPT_0303: start 23, 8 bit, big-endian, i-signal-type=PRIMITIVE, init-value=0, base-type=uint8, compu-method=CM_BMS_BatProDatDay, data-constr=DC_BMS_BatProDatDay, transfer-property=PENDING, to VCU  # Battery pack production date day
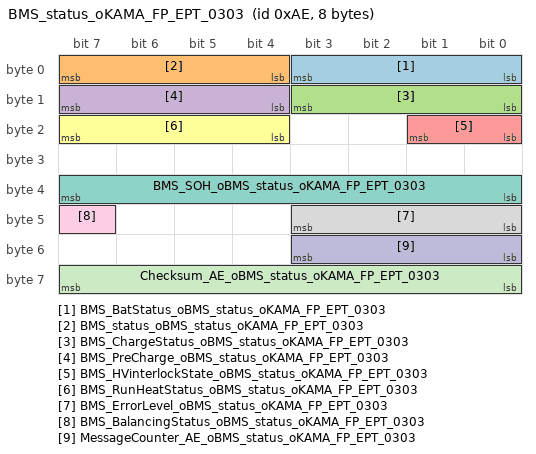
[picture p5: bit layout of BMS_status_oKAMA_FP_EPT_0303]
      frame BMS_status_oKAMA_FP_EPT_0303: id 0xAE, to VCU, frame-length=8, can-addressing-mode=STANDARD
        pdu BMS_status_oKAMA_FP_EPT_0303: length=8, minimum-delay=0, transmission-mode-false-timing=cyclic-timing={time-offset=0, time-period=0.02}, transmission-mode-true-timing=cyclic-timing={time-offset=0, time-period=0.02}, unused-bit-pattern=0
          signal BMS_BatStatus_oBMS_status_oKAMA_FP_EPT_0303: start 3, 4 bit, big-endian, i-signal-type=PRIMITIVE, init-value=0, base-type=uint8, compu-method=CM_BMS_BatStatus, data-constr=DC_BMS_BatStatus, transfer-property=PENDING, to VCU  # State of battery
          signal BMS_status_oBMS_status_oKAMA_FP_EPT_0303: start 7, 4 bit, big-endian, i-signal-type=PRIMITIVE, init-value=0, base-type=uint8, compu-method=CM_BMS_status, data-constr=DC_BMS_status, transfer-property=PENDING, to VCU  # State of BMS
          signal BMS_ChargeStatus_oBMS_status_oKAMA_FP_EPT_0303: start 11, 4 bit, big-endian, i-signal-type=PRIMITIVE, init-value=0, base-type=uint8, compu-method=CM_BMS_ChargeStatus, data-constr=DC_BMS_ChargeStatus, transfer-property=PENDING, to VCU  # State of BMS Charge Mode
          signal BMS_PreCharge_oBMS_status_oKAMA_FP_EPT_0303: start 15, 4 bit, big-endian, i-signal-type=PRIMITIVE, init-value=0, base-type=uint8, compu-method=CM_BMS_PreCharge, data-constr=DC_BMS_PreCharge, transfer-property=PENDING, to VCU  # State of BMS Precharge
          signal BMS_HVinterlockState_oBMS_status_oKAMA_FP_EPT_0303: start 17, 2 bit, big-endian, i-signal-type=PRIMITIVE, init-value=0, base-type=uint8, compu-method=CM_BMS_HVinterlockState, data-constr=DC_BMS_HVinterlockState, transfer-property=PENDING, to VCU  # HV interlock state
          signal BMS_RunHeatStatus_oBMS_status_oKAMA_FP_EPT_0303: start 23, 4 bit, big-endian, i-signal-type=PRIMITIVE, init-value=0, base-type=uint8, compu-method=CM_BMS_RunHeatStatus, data-constr=DC_BMS_RunHeatStatus, transfer-property=PENDING, to VCU  # State of Heat state when car running
          signal BMS_SOH_oBMS_status_oKAMA_FP_EPT_0303: start 39, 8 bit, big-endian, i-signal-type=PRIMITIVE, init-value=0, base-type=uint8, compu-method=CM_BMS_SOH, data-constr=DC_BMS_SOH, unit=U_p, transfer-property=PENDING, to VCU  # BMS SOH
          signal BMS_ErrorLevel_oBMS_status_oKAMA_FP_EPT_0303: start 43, 4 bit, big-endian, i-signal-type=PRIMITIVE, init-value=0, base-type=uint8, compu-method=CM_BMS_ErrorLevel, data-constr=DC_BMS_ErrorLevel, transfer-property=PENDING, to VCU  # BMS Error Level
          signal BMS_BalancingStatus_oBMS_status_oKAMA_FP_EPT_0303: start 47, 1 bit, big-endian, i-signal-type=PRIMITIVE, init-value=0, base-type=boolean, compu-method=CM_BMS_BalancingStatus, data-constr=DC_BMS_BalancingStatus, transfer-property=PENDING, to VCU  # Cell balancing status
          signal MessageCounter_AE_oBMS_status_oKAMA_FP_EPT_0303: start 51, 4 bit, big-endian, i-signal-type=PRIMITIVE, init-value=0, base-type=uint8, compu-method=CM_MessageCounter_AE, data-constr=DC_MessageCounter_AE, transfer-property=PENDING, to VCU  # Message counter signal for frame
          signal Checksum_AE_oBMS_status_oKAMA_FP_EPT_0303: start 63, 8 bit, big-endian, i-signal-type=PRIMITIVE, init-value=0, base-type=uint8, compu-method=CM_Checksum_AE, data-constr=DC_Checksum_AE, transfer-property=PENDING, to VCU  # Checksum signal for frame
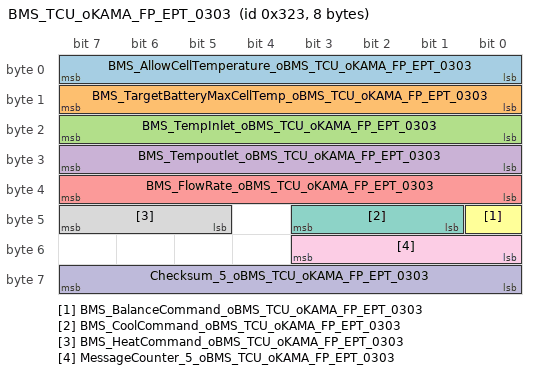
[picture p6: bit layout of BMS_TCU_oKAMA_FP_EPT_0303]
      frame BMS_TCU_oKAMA_FP_EPT_0303: id 0x323, to VCU, frame-length=8, can-addressing-mode=STANDARD
        pdu BMS_TCU_oKAMA_FP_EPT_0303: length=8, minimum-delay=0, transmission-mode-false-timing=cyclic-timing={time-offset=0, time-period=0.2}, transmission-mode-true-timing=cyclic-timing={time-offset=0, time-period=0.2}, unused-bit-pattern=0
          signal BMS_AllowCellTemperature_oBMS_TCU_oKAMA_FP_EPT_0303: start 7, 8 bit, big-endian, i-signal-type=PRIMITIVE, init-value=255, base-type=uint8, compu-method=CM_BMS_AllowCellTemperature, data-constr=DC_BMS_AllowCellTemperature, transfer-property=PENDING, to VCU  # Maximum allowable charging temperature
          signal BMS_TargetBatteryMaxCellTemp_oBMS_TCU_oKAMA_FP_EPT_0303: start 15, 8 bit, big-endian, i-signal-type=PRIMITIVE, init-value=255, base-type=uint8, compu-method=CM_BMS_TargetBatteryMaxCellTemp, data-constr=DC_BMS_TargetBatteryMaxCellTemp, transfer-property=PENDING, to VCU  # Target battery cell temperature
          signal BMS_TempInlet_oBMS_TCU_oKAMA_FP_EPT_0303: start 23, 8 bit, big-endian, i-signal-type=PRIMITIVE, init-value=255, base-type=uint8, compu-method=CM_BMS_TempInlet, data-constr=DC_BMS_TempInlet, transfer-property=PENDING, to VCU  # Water inlet temperature
          signal BMS_Tempoutlet_oBMS_TCU_oKAMA_FP_EPT_0303: start 31, 8 bit, big-endian, i-signal-type=PRIMITIVE, init-value=255, base-type=uint8, compu-method=CM_BMS_Tempoutlet, data-constr=DC_BMS_Tempoutlet, transfer-property=PENDING, to VCU  # Outlet water temperature
          signal BMS_FlowRate_oBMS_TCU_oKAMA_FP_EPT_0303: start 39, 8 bit, big-endian, i-signal-type=PRIMITIVE, init-value=255, base-type=uint8, compu-method=CM_BMS_FlowRate, data-constr=DC_BMS_FlowRate, unit=U_LYmin, transfer-property=PENDING, to VCU  # Coolant flow rate
          signal BMS_BalanceCommand_oBMS_TCU_oKAMA_FP_EPT_0303: start 40, 1 bit, big-endian, i-signal-type=PRIMITIVE, init-value=0, base-type=boolean, compu-method=CM_BMS_BalanceCommand, data-constr=DC_BMS_BalanceCommand, transfer-property=PENDING, to VCU  # Balance command from BMS
          signal BMS_CoolCommand_oBMS_TCU_oKAMA_FP_EPT_0303: start 43, 3 bit, big-endian, i-signal-type=PRIMITIVE, init-value=0, base-type=uint8, compu-method=CM_BMS_CoolCommand, data-constr=DC_BMS_CoolCommand, transfer-property=PENDING, to VCU  # Cool command from BMS
          signal BMS_HeatCommand_oBMS_TCU_oKAMA_FP_EPT_0303: start 47, 3 bit, big-endian, i-signal-type=PRIMITIVE, init-value=0, base-type=uint8, compu-method=CM_BMS_HeatCommand, data-constr=DC_BMS_HeatCommand, transfer-property=PENDING, to VCU  # Heat command from BMS
          signal MessageCounter_5_oBMS_TCU_oKAMA_FP_EPT_0303: start 51, 4 bit, big-endian, i-signal-type=PRIMITIVE, init-value=0, base-type=uint8, compu-method=CM_MessageCounter_5, data-constr=DC_MessageCounter_5, transfer-property=PENDING, to VCU  # Message counter signal for frame
          signal Checksum_5_oBMS_TCU_oKAMA_FP_EPT_0303: start 63, 8 bit, big-endian, i-signal-type=PRIMITIVE, init-value=0, base-type=uint8, compu-method=CM_Checksum_5, data-constr=DC_Checksum_5, transfer-property=PENDING, to VCU  # Checksum signal for frame
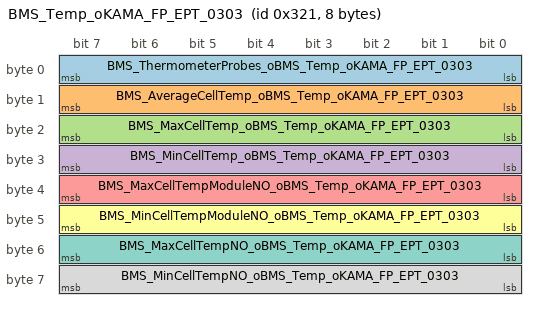
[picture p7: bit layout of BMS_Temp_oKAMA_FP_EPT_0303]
      frame BMS_Temp_oKAMA_FP_EPT_0303: id 0x321, to VCU, frame-length=8, can-addressing-mode=STANDARD
        pdu BMS_Temp_oKAMA_FP_EPT_0303: length=8, minimum-delay=0, transmission-mode-false-timing=cyclic-timing={time-offset=0, time-period=0.1}, transmission-mode-true-timing=cyclic-timing={time-offset=0, time-period=0.1}, unused-bit-pattern=0
          signal BMS_ThermometerProbes_oBMS_Temp_oKAMA_FP_EPT_0303: start 7, 8 bit, big-endian, i-signal-type=PRIMITIVE, init-value=0, base-type=uint8, compu-method=CM_BMS_ThermometerProbes, data-constr=DC_BMS_ThermometerProbes, transfer-property=PENDING, to VCU  # Sum of Temperature Probe in PACK
          signal BMS_AverageCellTemp_oBMS_Temp_oKAMA_FP_EPT_0303: start 15, 8 bit, big-endian, i-signal-type=PRIMITIVE, init-value=255, base-type=uint8, compu-method=CM_BMS_AverageCellTemp, data-constr=DC_BMS_AverageCellTemp, transfer-property=PENDING, to VCU  # Average battery cell temperature
          signal BMS_MaxCellTemp_oBMS_Temp_oKAMA_FP_EPT_0303: start 23, 8 bit, big-endian, i-signal-type=PRIMITIVE, init-value=255, base-type=uint8, compu-method=CM_BMS_MaxCellTemp, data-constr=DC_BMS_MaxCellTemp, transfer-property=PENDING, to VCU  # Maximal Cell TemperatureInlet value
          signal BMS_MinCellTemp_oBMS_Temp_oKAMA_FP_EPT_0303: start 31, 8 bit, big-endian, i-signal-type=PRIMITIVE, init-value=255, base-type=uint8, compu-method=CM_BMS_MinCellTemp, data-constr=DC_BMS_MinCellTemp, transfer-property=PENDING, to VCU  # Minimal Cell TemperatureInlet value
          signal BMS_MaxCellTempModuleNO_oBMS_Temp_oKAMA_FP_EPT_0303: start 39, 8 bit, big-endian, i-signal-type=PRIMITIVE, init-value=0, base-type=uint8, compu-method=CM_BMS_MaxCellTempModuleNO, data-constr=DC_BMS_MaxCellTempModuleNO, transfer-property=PENDING, to VCU  # Maximal Cell TemperatureInlet module NO
          signal BMS_MinCellTempModuleNO_oBMS_Temp_oKAMA_FP_EPT_0303: start 47, 8 bit, big-endian, i-signal-type=PRIMITIVE, init-value=0, base-type=uint8, compu-method=CM_BMS_MinCellTempModuleNO, data-constr=DC_BMS_MinCellTempModuleNO, transfer-property=PENDING, to VCU  # Minimal Cell TemperatureInlet module NO
          signal BMS_MaxCellTempNO_oBMS_Temp_oKAMA_FP_EPT_0303: start 55, 8 bit, big-endian, i-signal-type=PRIMITIVE, init-value=0, base-type=uint8, compu-method=CM_BMS_MaxCellTempNO, data-constr=DC_BMS_MaxCellTempNO, transfer-property=PENDING, to VCU  # Maximal Cell TemperatureInlet NO
          signal BMS_MinCellTempNO_oBMS_Temp_oKAMA_FP_EPT_0303: start 63, 8 bit, big-endian, i-signal-type=PRIMITIVE, init-value=0, base-type=uint8, compu-method=CM_BMS_MinCellTempNO, data-constr=DC_BMS_MinCellTempNO, transfer-property=PENDING, to VCU  # Minimal Cell TemperatureInlet NO
      frame BMS_VersionInfor_oKAMA_FP_EPT_0303: id 0x3B1, to VCU, frame-length=8, can-addressing-mode=STANDARD
        pdu BMS_VersionInfor_oKAMA_FP_EPT_0303: length=8, minimum-delay=0, transmission-mode-false-timing=cyclic-timing={time-offset=0, time-period=1}, transmission-mode-true-timing=cyclic-timing={time-offset=0, time-period=1}, unused-bit-pattern=0
          signal BMS_SoftVsesion_oBMS_VersionInfor_oKAMA_FP_EPT_0303: start 7, 8 bit, big-endian, i-signal-type=PRIMITIVE, init-value=0, base-type=uint8, compu-method=CM_BMS_SoftVsesion, data-constr=DC_BMS_SoftVsesion, transfer-property=PENDING, to VCU  # BMS software version
          signal BMS_HardVsesion_oBMS_VersionInfor_oKAMA_FP_EPT_0303: start 15, 8 bit, big-endian, i-signal-type=PRIMITIVE, init-value=0, base-type=uint8, compu-method=CM_BMS_HardVsesion, data-constr=DC_BMS_HardVsesion, transfer-property=PENDING, to VCU  # BMS hardware version
          signal BMS_BRMVersions_oBMS_VersionInfor_oKAMA_FP_EPT_0303: start 23, 16 bit, big-endian, i-signal-type=PRIMITIVE, init-value=0, base-type=uint16, compu-method=CM_BMS_BRMVersions, data-constr=DC_BMS_BRMVersions, transfer-property=PENDING, to VCU  # BMS versions for BRM
          signal BMS_ComVersion_oBMS_VersionInfor_oKAMA_FP_EPT_0303: start 39, 16 bit, big-endian, i-signal-type=PRIMITIVE, init-value=0, base-type=uint16, compu-method=CM_BMS_ComVersion, data-constr=DC_BMS_ComVersion, transfer-property=PENDING, to VCU  # BMS Communication Protocol Version
          signal BMS_BatProRights_oBMS_VersionInfor_oKAMA_FP_EPT_0303: start 51, 1 bit, big-endian, i-signal-type=PRIMITIVE, init-value=0, base-type=boolean, compu-method=CM_BMS_BatProRights, data-constr=DC_BMS_BatProRights, transfer-property=PENDING, to VCU  # Battery property rights
          signal BMS_Life_oBMS_VersionInfor_oKAMA_FP_EPT_0303: start 63, 8 bit, big-endian, i-signal-type=PRIMITIVE, init-value=0, base-type=uint8, compu-method=CM_BMS_Life, data-constr=DC_BMS_Life, transfer-property=PENDING, to VCU  # BMS life signal
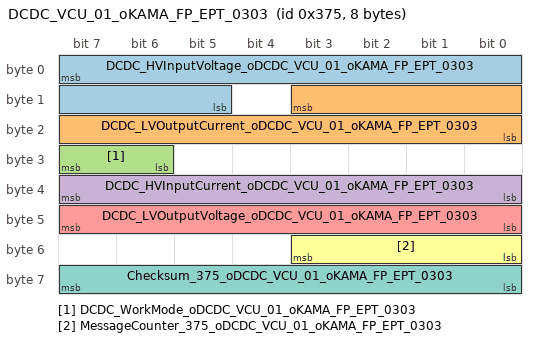
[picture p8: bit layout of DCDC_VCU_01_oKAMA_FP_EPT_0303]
      frame DCDC_VCU_01_oKAMA_FP_EPT_0303: id 0x375, to VCU, frame-length=8, can-addressing-mode=STANDARD
        pdu DCDC_VCU_01_oKAMA_FP_EPT_0303: length=8, minimum-delay=0, transmission-mode-false-timing=cyclic-timing={time-offset=0, time-period=0.1}, transmission-mode-true-timing=cyclic-timing={time-offset=0, time-period=0.1}, unused-bit-pattern=0
          signal DCDC_HVInputVoltage_oDCDC_VCU_01_oKAMA_FP_EPT_0303: start 7, 11 bit, big-endian, i-signal-type=PRIMITIVE, init-value=0, base-type=uint16, compu-method=CM_DCDC_HVInputVoltage, data-constr=DC_DCDC_HVInputVoltage, unit=U_V, transfer-property=PENDING, to VCU  # Voltage at high voltage side
          signal DCDC_LVOutputCurrent_oDCDC_VCU_01_oKAMA_FP_EPT_0303: start 11, 12 bit, big-endian, i-signal-type=PRIMITIVE, init-value=0, base-type=uint16, compu-method=CM_DCDC_LVOutputCurrent, data-constr=DC_DCDC_LVOutputCurrent, unit=U_A, transfer-property=PENDING, to VCU  # Current on low voltage side
          signal DCDC_WorkMode_oDCDC_VCU_01_oKAMA_FP_EPT_0303: start 31, 2 bit, big-endian, i-signal-type=PRIMITIVE, init-value=0, base-type=uint8, compu-method=CM_DCDC_WorkMode, data-constr=DC_DCDC_WorkMode, transfer-property=PENDING, to VCU  # State DCDC converter
          signal DCDC_HVInputCurrent_oDCDC_VCU_01_oKAMA_FP_EPT_0303: start 39, 8 bit, big-endian, i-signal-type=PRIMITIVE, init-value=0, base-type=uint8, compu-method=CM_DCDC_HVInputCurrent, data-constr=DC_DCDC_HVInputCurrent, unit=U_A, transfer-property=PENDING, to VCU  # Current at high voltage side
          signal DCDC_LVOutputVoltage_oDCDC_VCU_01_oKAMA_FP_EPT_0303: start 47, 8 bit, big-endian, i-signal-type=PRIMITIVE, init-value=0, base-type=uint8, compu-method=CM_DCDC_LVOutputVoltage, data-constr=DC_DCDC_LVOutputVoltage, unit=U_V, transfer-property=PENDING, to VCU  # Voltage on low voltage side
          signal MessageCounter_375_oDCDC_VCU_01_oKAMA_FP_EPT_0303: start 51, 4 bit, big-endian, i-signal-type=PRIMITIVE, init-value=0, base-type=uint8, compu-method=CM_MessageCounter_375, data-constr=DC_MessageCounter_375, transfer-property=PENDING, to VCU  # Message counter signal for frame
          signal Checksum_375_oDCDC_VCU_01_oKAMA_FP_EPT_0303: start 63, 8 bit, big-endian, i-signal-type=PRIMITIVE, init-value=0, base-type=uint8, compu-method=CM_Checksum_375, data-constr=DC_Checksum_375, transfer-property=PENDING, to VCU  # Checksum signal for frame
      frame DCDC_VCU_02_oKAMA_FP_EPT_0303: id 0x376, to VCU, frame-length=8, can-addressing-mode=STANDARD
        pdu DCDC_VCU_02_oKAMA_FP_EPT_0303: length=8, minimum-delay=0, transmission-mode-false-timing=cyclic-timing={time-offset=0, time-period=0.2}, transmission-mode-true-timing=cyclic-timing={time-offset=0, time-period=0.2}, unused-bit-pattern=0
          signal DCDC_OutputSOGFault_oDCDC_VCU_02_oKAMA_FP_EPT_0303: start 0, 1 bit, big-endian, i-signal-type=PRIMITIVE, init-value=0, base-type=boolean, compu-method=CM_DCDC_OutputSOGFault, data-constr=DC_DCDC_OutputSOGFault, transfer-property=PENDING, to VCU  # DCDC output is short-to-ground fault
          signal DCDC_OutputVoltLowFault_oDCDC_VCU_02_oKAMA_FP_EPT_0303: start 1, 1 bit, big-endian, i-signal-type=PRIMITIVE, init-value=0, base-type=boolean, compu-method=CM_DCDC_OutputVoltLowFault, data-constr=DC_DCDC_OutputVoltLowFault, transfer-property=PENDING, to VCU  # DCDC output undervoltage fault
          signal DCDC_OutputVoltHighFault_oDCDC_VCU_02_oKAMA_FP_EPT_0303: start 2, 1 bit, big-endian, i-signal-type=PRIMITIVE, init-value=0, base-type=boolean, compu-method=CM_DCDC_OutputVoltHighFault, data-constr=DC_DCDC_OutputVoltHighFault, transfer-property=PENDING, to VCU  # DCDC output overvoltage fault
          signal DCDC_InputVoltLowFault_oDCDC_VCU_02_oKAMA_FP_EPT_0303: start 3, 1 bit, big-endian, i-signal-type=PRIMITIVE, init-value=0, base-type=boolean, compu-method=CM_DCDC_InputVoltLowFault, data-constr=DC_DCDC_InputVoltLowFault, transfer-property=PENDING, to VCU  # DCDC input undervoltage fault
          signal DCDC_InputVoltHighFault_oDCDC_VCU_02_oKAMA_FP_EPT_0303: start 4, 1 bit, big-endian, i-signal-type=PRIMITIVE, init-value=0, base-type=boolean, compu-method=CM_DCDC_InputVoltHighFault, data-constr=DC_DCDC_InputVoltHighFault, transfer-property=PENDING, to VCU  # DCDC input overvoltage fault
          signal DCDC_OutputCurrentHighFault_oDCDC_VCU_02_oKAMA_FP_EPT_0303: start 5, 1 bit, big-endian, i-signal-type=PRIMITIVE, init-value=0, base-type=boolean, compu-method=CM_DCDC_OutputCurrentHighFault, data-constr=DC_DCDC_OutputCurrentHighFault, transfer-property=PENDING, to VCU  # DCDC output overcurrent fault
          signal DCDC_FaultStatus_oDCDC_VCU_02_oKAMA_FP_EPT_0303: start 7, 2 bit, big-endian, i-signal-type=PRIMITIVE, init-value=0, base-type=uint8, compu-method=CM_DCDC_FaultStatus, data-constr=DC_DCDC_FaultStatus, transfer-property=PENDING, to VCU  # No fault?this value means the DCDC is normal. Recoverable fault? DCDC will down power and wait for the fault clear, and retry. Unrecoverable fault?when DCDC detect this fault, DCDC should stop output and power down,when the power is reduced, also need to send this signal. 0x1=Level1--Upload error code(Derating); 0x2=Level2--Upload error code,Recoverable 5 times,if unrecoverable, will upload level 3; 0x3=Level3--stop output(Unrecoverable);
          signal DCDC_PrimarySideOvertempStatus_oDCDC_VCU_02_oKAMA_FP_EPT_0303: start 9, 1 bit, big-endian, i-signal-type=PRIMITIVE, init-value=0, base-type=boolean, compu-method=CM_DCDC_PrimarySideOvertempStatus, data-constr=DC_DCDC_PrimarySideOvertempStatus, transfer-property=PENDING, to VCU  # DCDC Primary side overtemperature fault
          signal DCDC_InternalFault_oDCDC_VCU_02_oKAMA_FP_EPT_0303: start 10, 1 bit, big-endian, i-signal-type=PRIMITIVE, init-value=0, base-type=boolean, compu-method=CM_DCDC_InternalFault, data-constr=DC_DCDC_InternalFault, transfer-property=PENDING, to VCU  # DCDC internal error
          signal DCDC_StopFault_oDCDC_VCU_02_oKAMA_FP_EPT_0303: start 11, 1 bit, big-endian, i-signal-type=PRIMITIVE, init-value=0, base-type=boolean, compu-method=CM_DCDC_StopFault, data-constr=DC_DCDC_StopFault, transfer-property=PENDING, to VCU  # DCDC shutdown failure failure
          signal DCDC_ComFault_oDCDC_VCU_02_oKAMA_FP_EPT_0303: start 12, 1 bit, big-endian, i-signal-type=PRIMITIVE, init-value=0, base-type=boolean, compu-method=CM_DCDC_ComFault, data-constr=DC_DCDC_ComFault, transfer-property=PENDING, to VCU  # DCDC communication fault
          signal DCDC_OutputTempSensorFault_oDCDC_VCU_02_oKAMA_FP_EPT_0303: start 13, 1 bit, big-endian, i-signal-type=PRIMITIVE, init-value=0, base-type=boolean, compu-method=CM_DCDC_OutputTempSensorFault, data-constr=DC_DCDC_OutputTempSensorFault, transfer-property=PENDING, to VCU  # DCDC the low-voltage side temperature sensor is faulty
          signal DCDC_OutputCurrentSensorFault_oDCDC_VCU_02_oKAMA_FP_EPT_0303: start 14, 1 bit, big-endian, i-signal-type=PRIMITIVE, init-value=0, base-type=boolean, compu-method=CM_DCDC_OutputCurrentSensorFault, data-constr=DC_DCDC_OutputCurrentSensorFault, transfer-property=PENDING, to VCU  # DCDC the low-side current sensor is faulty
          signal DCDC_SecordarySideOvertempStatus_oDCDC_VCU_02_oKAMA_FP_EPT_0303: start 15, 1 bit, big-endian, i-signal-type=PRIMITIVE, init-value=0, base-type=boolean, compu-method=CM_DCDC_SecordarySideOvertempStatus, data-constr=DC_DCDC_SecordarySideOvertempStatus, transfer-property=PENDING, to VCU  # DCDC Secordary side overtemperature fault
          signal DCDC_OBCTempHighFault_oDCDC_VCU_02_oKAMA_FP_EPT_0303: start 16, 1 bit, big-endian, i-signal-type=PRIMITIVE, init-value=0, base-type=boolean, compu-method=CM_DCDC_OBCTempHighFault, data-constr=DC_DCDC_OBCTempHighFault, transfer-property=PENDING, to VCU  # PCB overtemperature fault£¨environmental overtemprerature)
          signal OBC_DCDC_KL30Error_oDCDC_VCU_02_oKAMA_FP_EPT_0303: start 22, 1 bit, big-endian, i-signal-type=PRIMITIVE, init-value=0, base-type=boolean, compu-method=CM_OBC_DCDC_KL30Error, data-constr=DC_OBC_DCDC_KL30Error, transfer-property=PENDING, to VCU  # KL30 error
          signal DCDC_OBC_CANBusoff_oDCDC_VCU_02_oKAMA_FP_EPT_0303: start 23, 1 bit, big-endian, i-signal-type=PRIMITIVE, init-value=0, base-type=boolean, compu-method=CM_DCDC_OBC_CANBusoff, data-constr=DC_DCDC_OBC_CANBusoff, transfer-property=PENDING, to VCU  # CAN Busoff error
          signal DCDC_SecondarySideTemp_oDCDC_VCU_02_oKAMA_FP_EPT_0303: start 31, 8 bit, big-endian, i-signal-type=PRIMITIVE, init-value=255, base-type=uint8, compu-method=CM_DCDC_SecondarySideTemp, data-constr=DC_DCDC_SecondarySideTemp, transfer-property=PENDING, to VCU  # This signal is sent to TMS,according to this signal, TCU control the temporature of water
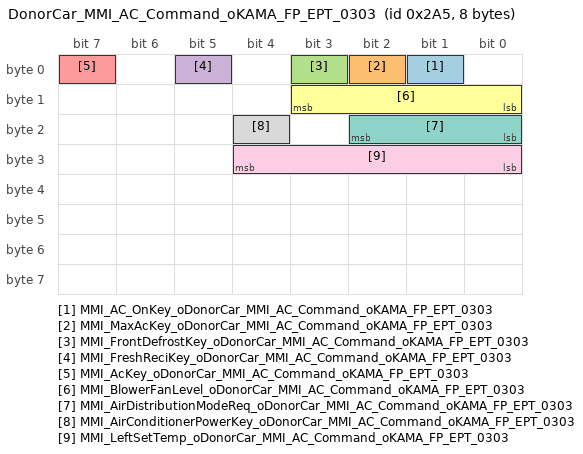
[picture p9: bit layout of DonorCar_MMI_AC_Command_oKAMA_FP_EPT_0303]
      frame DonorCar_MMI_AC_Command_oKAMA_FP_EPT_0303: id 0x2A5, to VCU, frame-length=8, can-addressing-mode=STANDARD
        pdu DonorCar_MMI_AC_Command_oKAMA_FP_EPT_0303: length=8, minimum-delay=0, transmission-mode-false-timing=cyclic-timing={time-offset=0, time-period=0.1}, transmission-mode-true-timing=cyclic-timing={time-offset=0, time-period=0.1}, unused-bit-pattern=0
          signal MMI_AC_OnKey_oDonorCar_MMI_AC_Command_oKAMA_FP_EPT_0303: start 1, 1 bit, big-endian, i-signal-type=PRIMITIVE, init-value=0, base-type=boolean, compu-method=CM_MMI_AC_OnKey, data-constr=DC_MMI_AC_OnKey, transfer-property=PENDING, to VCU  # ON state key
          signal MMI_MaxAcKey_oDonorCar_MMI_AC_Command_oKAMA_FP_EPT_0303: start 2, 1 bit, big-endian, i-signal-type=PRIMITIVE, init-value=0, base-type=boolean, compu-method=CM_MMI_MaxAcKey, data-constr=DC_MMI_MaxAcKey, transfer-property=PENDING, to VCU  # Max AC key
          signal MMI_FrontDefrostKey_oDonorCar_MMI_AC_Command_oKAMA_FP_EPT_0303: start 3, 1 bit, big-endian, i-signal-type=PRIMITIVE, init-value=0, base-type=boolean, compu-method=CM_MMI_FrontDefrostKey, data-constr=DC_MMI_FrontDefrostKey, transfer-property=PENDING, to VCU  # Defrost key
          signal MMI_FreshReciKey_oDonorCar_MMI_AC_Command_oKAMA_FP_EPT_0303: start 5, 1 bit, big-endian, i-signal-type=PRIMITIVE, init-value=0, base-type=boolean, compu-method=CM_MMI_FreshReciKey, data-constr=DC_MMI_FreshReciKey, transfer-property=PENDING, to VCU  # R/F key
          signal MMI_AcKey_oDonorCar_MMI_AC_Command_oKAMA_FP_EPT_0303: start 7, 1 bit, big-endian, i-signal-type=PRIMITIVE, init-value=0, base-type=boolean, compu-method=CM_MMI_AcKey, data-constr=DC_MMI_AcKey, transfer-property=PENDING, to VCU  # AC key
          signal MMI_BlowerFanLevel_oDonorCar_MMI_AC_Command_oKAMA_FP_EPT_0303: start 11, 4 bit, big-endian, i-signal-type=PRIMITIVE, init-value=15, base-type=uint8, compu-method=CM_MMI_BlowerFanLevel, data-constr=DC_MMI_BlowerFanLevel, transfer-property=PENDING, to VCU  # Blower fan Level
          signal MMI_AirDistributionModeReq_oDonorCar_MMI_AC_Command_oKAMA_FP_EPT_0303: start 18, 3 bit, big-endian, i-signal-type=PRIMITIVE, init-value=7, base-type=uint8, compu-method=CM_MMI_AirDistributionModeReq, data-constr=DC_MMI_AirDistributionModeReq, transfer-property=PENDING, to VCU  # Air distribution mode request
          signal MMI_AirConditionerPowerKey_oDonorCar_MMI_AC_Command_oKAMA_FP_EPT_0303: start 20, 1 bit, big-endian, i-signal-type=PRIMITIVE, init-value=0, base-type=boolean, compu-method=CM_MMI_AirConditionerPowerKey, data-constr=DC_MMI_AirConditionerPowerKey, transfer-property=PENDING, to VCU  # Air Conditioner Power Key
          signal MMI_LeftSetTemp_oDonorCar_MMI_AC_Command_oKAMA_FP_EPT_0303: start 28, 5 bit, big-endian, i-signal-type=PRIMITIVE, init-value=0, base-type=uint8, compu-method=CM_MMI_LeftSetTemp, data-constr=DC_MMI_LeftSetTemp, transfer-property=PENDING, to VCU  # Left set temperature
      frame EVCOM_State_oKAMA_FP_EPT_0303: id 0x2CB, to VCU, frame-length=8, can-addressing-mode=STANDARD
        pdu EVCOM_State_oKAMA_FP_EPT_0303: length=8, minimum-delay=0, transmission-mode-false-timing=cyclic-timing={time-offset=0, time-period=0.1}, transmission-mode-true-timing=cyclic-timing={time-offset=0, time-period=0.1}, unused-bit-pattern=0
          signal EVCOM_OverPwrDropFreqError_oEVCOM_State_oKAMA_FP_EPT_0303: start 0, 1 bit, big-endian, i-signal-type=PRIMITIVE, init-value=0, base-type=boolean, compu-method=CM_EVCOM_OverPwrDropFreqError, data-constr=DC_EVCOM_OverPwrDropFreqError, transfer-property=PENDING, to VCU  # EVCOM Over Power Drop Frequency Error
          signal EVCOM_OverCurDropFreqError_oEVCOM_State_oKAMA_FP_EPT_0303: start 1, 1 bit, big-endian, i-signal-type=PRIMITIVE, init-value=0, base-type=boolean, compu-method=CM_EVCOM_OverCurDropFreqError, data-constr=DC_EVCOM_OverCurDropFreqError, transfer-property=PENDING, to VCU  # EVCOM Over Current Drop Frequency Error
          signal EVCOM_CommunicationError_oEVCOM_State_oKAMA_FP_EPT_0303: start 2, 1 bit, big-endian, i-signal-type=PRIMITIVE, init-value=0, base-type=boolean, compu-method=CM_EVCOM_CommunicationError, data-constr=DC_EVCOM_CommunicationError, transfer-property=PENDING, to VCU  # EVCOM Communication Error
          signal EVCOM_StandByUnderVolError_oEVCOM_State_oKAMA_FP_EPT_0303: start 3, 1 bit, big-endian, i-signal-type=PRIMITIVE, init-value=0, base-type=boolean, compu-method=CM_EVCOM_StandByUnderVolError, data-constr=DC_EVCOM_StandByUnderVolError, transfer-property=PENDING, to VCU  # EVCOM Stand By Under Voltage Error
          signal EVCOM_StandByOverVolError_oEVCOM_State_oKAMA_FP_EPT_0303: start 4, 1 bit, big-endian, i-signal-type=PRIMITIVE, init-value=0, base-type=boolean, compu-method=CM_EVCOM_StandByOverVolError, data-constr=DC_EVCOM_StandByOverVolError, transfer-property=PENDING, to VCU  # EVCOM Stand By Over Voltage Error
          signal EVCOM_UnderVoltageError_oEVCOM_State_oKAMA_FP_EPT_0303: start 5, 1 bit, big-endian, i-signal-type=PRIMITIVE, init-value=0, base-type=boolean, compu-method=CM_EVCOM_UnderVoltageError, data-constr=DC_EVCOM_UnderVoltageError, transfer-property=PENDING, to VCU  # EVCOM Under Voltage Error
          signal EVCOM_OverVoltageError_oEVCOM_State_oKAMA_FP_EPT_0303: start 6, 1 bit, big-endian, i-signal-type=PRIMITIVE, init-value=0, base-type=boolean, compu-method=CM_EVCOM_OverVoltageError, data-constr=DC_EVCOM_OverVoltageError, transfer-property=PENDING, to VCU  # EVCOM Over Voltage Error
          signal EVCOM_OverCurrentError_oEVCOM_State_oKAMA_FP_EPT_0303: start 7, 1 bit, big-endian, i-signal-type=PRIMITIVE, init-value=0, base-type=boolean, compu-method=CM_EVCOM_OverCurrentError, data-constr=DC_EVCOM_OverCurrentError, transfer-property=PENDING, to VCU  # EVCOM Over Current Error
          signal EVCOM_CompDeviceInternTempError_oEVCOM_State_oKAMA_FP_EPT_0303: start 15, 8 bit, big-endian, i-signal-type=PRIMITIVE, init-value=40, base-type=uint8, compu-method=CM_EVCOM_CompDeviceInternTempError, data-constr=DC_EVCOM_CompDeviceInternTempError, transfer-property=PENDING, to VCU  # Device Internal Temperature Éè±¸ÄÚ²¿ÎÂ¶È
          signal EVCOM_CompActlSpdValid_oEVCOM_State_oKAMA_FP_EPT_0303: start 21, 1 bit, big-endian, i-signal-type=PRIMITIVE, init-value=0, base-type=boolean, compu-method=CM_EVCOM_CompActlSpdValid, data-constr=DC_EVCOM_CompActlSpdValid, transfer-property=PENDING, to VCU  # Compressor Actual Speed Validity Ñ¹Ëõ»úÊµ¼ÊÔË×ªËÙ¶ÈÓÐÐ§ÐÔ
          signal EVCOM_CompActlCnsmpCurValid_oEVCOM_State_oKAMA_FP_EPT_0303: start 22, 1 bit, big-endian, i-signal-type=PRIMITIVE, init-value=0, base-type=boolean, compu-method=CM_EVCOM_CompActlCnsmpCurValid, data-constr=DC_EVCOM_CompActlCnsmpCurValid, transfer-property=PENDING, to VCU  # Compressor Actual Consuption Current Validity Ñ¹Ëõ»úÔËÐÐµçÁ÷ÓÐÐ§ÐÔ
          signal EVCOM_CompActlPwrCnsmpValid_oEVCOM_State_oKAMA_FP_EPT_0303: start 23, 1 bit, big-endian, i-signal-type=PRIMITIVE, init-value=0, base-type=boolean, compu-method=CM_EVCOM_CompActlPwrCnsmpValid, data-constr=DC_EVCOM_CompActlPwrCnsmpValid, transfer-property=PENDING, to VCU  # Compressor Actual Power Consumption Validity Ñ¹Ëõ»úÊµ¼ÊÏûºÄ¹¦ÂÊÓÐÐ§ÐÔ
          signal EVCOM_CompActlSpd_oEVCOM_State_oKAMA_FP_EPT_0303: start 31, 13 bit, big-endian, i-signal-type=PRIMITIVE, init-value=0, base-type=uint16, compu-method=CM_EVCOM_CompActlSpd, data-constr=DC_EVCOM_CompActlSpd, unit=U_rpm, transfer-property=PENDING, to VCU  # Compressor Actual Speed Ñ¹Ëõ»úÊµ¼ÊÔË×ªËÙ¶È
          signal EVCOM_CompActlPwrCnsmp_oEVCOM_State_oKAMA_FP_EPT_0303: start 47, 8 bit, big-endian, i-signal-type=PRIMITIVE, init-value=0, base-type=uint8, compu-method=CM_EVCOM_CompActlPwrCnsmp, data-constr=DC_EVCOM_CompActlPwrCnsmp, unit=U_KW, transfer-property=PENDING, to VCU  # Compressor Actual Power Consumption Ñ¹Ëõ»úÊµ¼ÊÏûºÄ¹¦ÂÊ
          signal EVCOM_ActlOprtMode_oEVCOM_State_oKAMA_FP_EPT_0303: start 52, 2 bit, big-endian, i-signal-type=PRIMITIVE, init-value=0, base-type=uint8, compu-method=CM_EVCOM_ActlOprtMode, data-constr=DC_EVCOM_ActlOprtMode, transfer-property=PENDING, to VCU  # Air Conditioning Compressor Actual Operation Mode ¿Õµ÷Ñ¹Ëõ»úÊµ¼ÊÔËÐÐÄ£Ê½
          signal EVCOM_FailStatus_oEVCOM_State_oKAMA_FP_EPT_0303: start 54, 1 bit, big-endian, i-signal-type=PRIMITIVE, init-value=0, base-type=boolean, compu-method=CM_EVCOM_FailStatus, data-constr=DC_EVCOM_FailStatus, transfer-property=PENDING, to VCU  # Air Conditioning Compressor Failure Status ¿Õµ÷Ñ¹Ëõ»úÊ§Ð§×´Ì¬
          signal EVCOM_CompDeratingOprtStatus_oEVCOM_State_oKAMA_FP_EPT_0303: start 55, 1 bit, big-endian, i-signal-type=PRIMITIVE, init-value=0, base-type=boolean, compu-method=CM_EVCOM_CompDeratingOprtStatus, data-constr=DC_EVCOM_CompDeratingOprtStatus, transfer-property=PENDING, to VCU  # Air Conditioning Compressor Derating Operation Status ¿Õµ÷Ñ¹Ëõ»ú½µ¼¶ÔËÐÐ×´Ì¬
          signal EVCOM_CompActlCnsmpCur_oEVCOM_State_oKAMA_FP_EPT_0303: start 63, 8 bit, big-endian, i-signal-type=PRIMITIVE, init-value=0, base-type=uint8, compu-method=CM_EVCOM_CompActlCnsmpCur, data-constr=DC_EVCOM_CompActlCnsmpCur, unit=U_A, transfer-property=PENDING, to VCU  # Compressor Run Current Ñ¹Ëõ»úÔËÐÐµçÁ÷
      frame GW_BCM_oKAMA_FP_EPT_0303: id 0x38F, to VCU, frame-length=8, can-addressing-mode=STANDARD
        pdu GW_BCM_oKAMA_FP_EPT_0303: length=8, minimum-delay=0, transmission-mode-false-timing=cyclic-timing={time-offset=0, time-period=0.1}, transmission-mode-true-timing=cyclic-timing={time-offset=0, time-period=0.1}, unused-bit-pattern=0
          signal BCM_RLHSSolarDrvr_oGW_BCM_oKAMA_FP_EPT_0303: start 7, 8 bit, big-endian, i-signal-type=PRIMITIVE, init-value=0, base-type=uint8, compu-method=CM_BCM_RLHSSolarDrvr, data-constr=DC_BCM_RLHSSolarDrvr, unit=U_WYm2, transfer-property=PENDING, to VCU  # The left solar sensor measured ×ó±ßÈÕÕÕ·øÉäÇ¿¶È
          signal BCM_RLHSSolarPass_oGW_BCM_oKAMA_FP_EPT_0303: start 15, 8 bit, big-endian, i-signal-type=PRIMITIVE, init-value=0, base-type=uint8, compu-method=CM_BCM_RLHSSolarPass, data-constr=DC_BCM_RLHSSolarPass, unit=U_WYm2, transfer-property=PENDING, to VCU  # The right solar sensor measured ÓÒ±ßÈÕÕÕ·øÉäÇ¿¶È
          signal BCM_RLHSHumidSensorValue_oGW_BCM_oKAMA_FP_EPT_0303: start 23, 8 bit, big-endian, i-signal-type=PRIMITIVE, init-value=0, base-type=uint8, compu-method=CM_BCM_RLHSHumidSensorValue, data-constr=DC_BCM_RLHSHumidSensorValue, unit=U_p, transfer-property=PENDING, to VCU  # This signal delivers information about air humid : from 0% to 100% ¿ÕÆøÊª¶È ÓÐÐ§Öµ0x1¿ªÊ¼ Start up(³õÊ¼Öµ) 0x00 Invalid(ÎÞÐ§Öµ)0xFF
          signal BCM_RLHSTempSensorValue_oGW_BCM_oKAMA_FP_EPT_0303: start 31, 8 bit, big-endian, i-signal-type=PRIMITIVE, init-value=80, base-type=uint8, compu-method=CM_BCM_RLHSTempSensorValue, data-constr=DC_BCM_RLHSTempSensorValue, transfer-property=PENDING, to VCU  # This signal delivers information about temperature in car ²£Á§ÎÂ¶È ÓÐÐ§Öµ0x1¿ªÊ¼ Start up(³õÊ¼Öµ) 0x00 Invalid(ÎÞÐ§Öµ)0xFF
          signal BCM_RLHSTempDewPoint_oGW_BCM_oKAMA_FP_EPT_0303: start 39, 11 bit, big-endian, i-signal-type=PRIMITIVE, init-value=400, base-type=uint16, compu-method=CM_BCM_RLHSTempDewPoint, data-constr=DC_BCM_RLHSTempDewPoint, transfer-property=PENDING, to VCU  # Â¶µã ÓÐÐ§Öµ0x1¿ªÊ¼ Start up(³õÊ¼Öµ) 0x00 Invalid(ÎÞÐ§Öµ)0x7FF
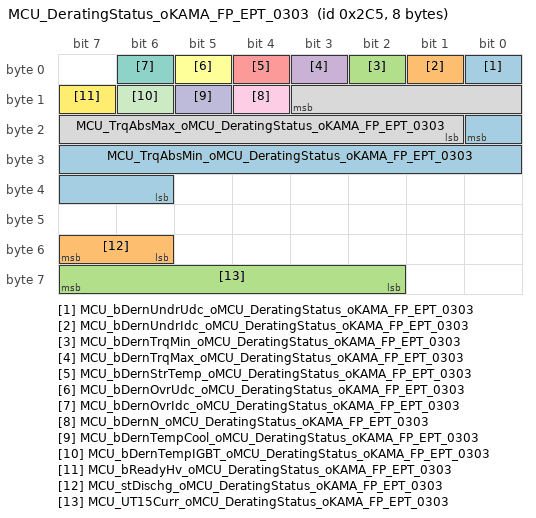
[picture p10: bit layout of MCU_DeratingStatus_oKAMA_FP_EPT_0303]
      frame MCU_DeratingStatus_oKAMA_FP_EPT_0303: id 0x2C5, to VCU, frame-length=8, can-addressing-mode=STANDARD
        pdu MCU_DeratingStatus_oKAMA_FP_EPT_0303: length=8, minimum-delay=0, transmission-mode-false-timing=cyclic-timing={time-offset=0, time-period=0.1}, transmission-mode-true-timing=cyclic-timing={time-offset=0, time-period=0.1}, unused-bit-pattern=0
          signal MCU_bDernUndrUdc_oMCU_DeratingStatus_oKAMA_FP_EPT_0303: start 0, 1 bit, big-endian, i-signal-type=PRIMITIVE, init-value=0, base-type=boolean, compu-method=CM_MCU_bDernUndrUdc, data-constr=DC_MCU_bDernUndrUdc, transfer-property=PENDING, to VCU  # derating from dclink voltage underÄ¸ÏßÇ·Ñ¹ÏÞ¹¦
          signal MCU_bDernUndrIdc_oMCU_DeratingStatus_oKAMA_FP_EPT_0303: start 1, 1 bit, big-endian, i-signal-type=PRIMITIVE, init-value=0, base-type=boolean, compu-method=CM_MCU_bDernUndrIdc, data-constr=DC_MCU_bDernUndrIdc, transfer-property=PENDING, to VCU  # derating from dclink current underÄ¸ÏßÇ·Á÷ÏÞ¹¦
          signal MCU_bDernTrqMin_oMCU_DeratingStatus_oKAMA_FP_EPT_0303: start 2, 1 bit, big-endian, i-signal-type=PRIMITIVE, init-value=0, base-type=boolean, compu-method=CM_MCU_bDernTrqMin, data-constr=DC_MCU_bDernTrqMin, transfer-property=PENDING, to VCU  # derating from torque min limitation³¬¹ýµç»ú×îÐ¡ÍâÌØÐÔÏÞ¹¦
          signal MCU_bDernTrqMax_oMCU_DeratingStatus_oKAMA_FP_EPT_0303: start 3, 1 bit, big-endian, i-signal-type=PRIMITIVE, init-value=0, base-type=boolean, compu-method=CM_MCU_bDernTrqMax, data-constr=DC_MCU_bDernTrqMax, transfer-property=PENDING, to VCU  # derating from troque max limitation³¬¹ýµç»ú×î´óÍâÌØÐÔÏÞ¹¦
          signal MCU_bDernStrTemp_oMCU_DeratingStatus_oKAMA_FP_EPT_0303: start 4, 1 bit, big-endian, i-signal-type=PRIMITIVE, init-value=0, base-type=boolean, compu-method=CM_MCU_bDernStrTemp, data-constr=DC_MCU_bDernStrTemp, transfer-property=PENDING, to VCU  # derating from stator temperature overµç»ú¹ýÎÂÏÞ¹¦
          signal MCU_bDernOvrUdc_oMCU_DeratingStatus_oKAMA_FP_EPT_0303: start 5, 1 bit, big-endian, i-signal-type=PRIMITIVE, init-value=0, base-type=boolean, compu-method=CM_MCU_bDernOvrUdc, data-constr=DC_MCU_bDernOvrUdc, transfer-property=PENDING, to VCU  # derating from dclink voltage overÖ±Á÷Ä¸Ïß¹ýÑ¹ÏÞ¹¦
          signal MCU_bDernOvrIdc_oMCU_DeratingStatus_oKAMA_FP_EPT_0303: start 6, 1 bit, big-endian, i-signal-type=PRIMITIVE, init-value=0, base-type=boolean, compu-method=CM_MCU_bDernOvrIdc, data-constr=DC_MCU_bDernOvrIdc, transfer-property=PENDING, to VCU  # derating from dclink current overÖ±Á÷Ä¸Ïß¹ýÁ÷ÏÞ¹¦
          signal MCU_TrqAbsMax_oMCU_DeratingStatus_oKAMA_FP_EPT_0303: start 11, 11 bit, big-endian, i-signal-type=PRIMITIVE, init-value=1024, base-type=uint16, compu-method=CM_MCU_TrqAbsMax, data-constr=DC_MCU_TrqAbsMax, transfer-property=PENDING, to VCU  # the maximum allowed torque of E-motorµç»ú×î´óÔÊÐíÁ¦¾Ø
          signal MCU_bDernN_oMCU_DeratingStatus_oKAMA_FP_EPT_0303: start 12, 1 bit, big-endian, i-signal-type=PRIMITIVE, init-value=0, base-type=boolean, compu-method=CM_MCU_bDernN, data-constr=DC_MCU_bDernN, transfer-property=PENDING, to VCU  # derating from speed over³¬ËÙÏÞ¹¦
          signal MCU_bDernTempCool_oMCU_DeratingStatus_oKAMA_FP_EPT_0303: start 13, 1 bit, big-endian, i-signal-type=PRIMITIVE, init-value=0, base-type=boolean, compu-method=CM_MCU_bDernTempCool, data-constr=DC_MCU_bDernTempCool, transfer-property=PENDING, to VCU  # derating from coolant temperature overÀäÈ´Ë®¹ýÎÂÏÞ¹¦
          signal MCU_bDernTempIGBT_oMCU_DeratingStatus_oKAMA_FP_EPT_0303: start 14, 1 bit, big-endian, i-signal-type=PRIMITIVE, init-value=0, base-type=boolean, compu-method=CM_MCU_bDernTempIGBT, data-constr=DC_MCU_bDernTempIGBT, transfer-property=PENDING, to VCU  # derating from igbt temperature over/ IGBT¹ýÎÂÏÞ¹¦
          signal MCU_bReadyHv_oMCU_DeratingStatus_oKAMA_FP_EPT_0303: start 15, 1 bit, big-endian, i-signal-type=PRIMITIVE, init-value=0, base-type=boolean, compu-method=CM_MCU_bReadyHv, data-constr=DC_MCU_bReadyHv, transfer-property=PENDING, to VCU  # high voltage ready flag¸ßÑ¹Ô¤³ä×´Ì¬
          signal MCU_TrqAbsMin_oMCU_DeratingStatus_oKAMA_FP_EPT_0303: start 16, 11 bit, big-endian, i-signal-type=PRIMITIVE, init-value=1024, base-type=uint16, compu-method=CM_MCU_TrqAbsMin, data-constr=DC_MCU_TrqAbsMin, transfer-property=PENDING, to VCU  # the minimum allowed torque of E-motorµç»ú×îÐ¡ÔÊÐíÁ¦¾Ø
          signal MCU_stDischg_oMCU_DeratingStatus_oKAMA_FP_EPT_0303: start 55, 2 bit, big-endian, i-signal-type=PRIMITIVE, init-value=0, base-type=uint8, compu-method=CM_MCU_stDischg, data-constr=DC_MCU_stDischg, transfer-property=PENDING, to VCU  # the discharge statusÖ÷¶¯·Åµç×´Ì¬
          signal MCU_UT15Curr_oMCU_DeratingStatus_oKAMA_FP_EPT_0303: start 63, 6 bit, big-endian, i-signal-type=PRIMITIVE, init-value=0, base-type=uint8, compu-method=CM_MCU_UT15Curr, data-constr=DC_MCU_UT15Curr, transfer-property=PENDING, to VCU  # the actual voltage of Tl15µÍÑ¹µçÔ´ÊµÊ±µçÑ¹
      frame MCU_FailureCode_oKAMA_FP_EPT_0303: id 0x2C6, to VCU, frame-length=8, can-addressing-mode=STANDARD
        pdu MCU_FailureCode_oKAMA_FP_EPT_0303: length=8, minimum-delay=0, transmission-mode-false-timing=cyclic-timing={time-offset=0, time-period=0.1}, transmission-mode-true-timing=cyclic-timing={time-offset=0, time-period=0.1}, unused-bit-pattern=0
          signal MCU_FailCode1_oMCU_FailureCode_oKAMA_FP_EPT_0303: start 7, 3 bit, big-endian, i-signal-type=PRIMITIVE, init-value=0, base-type=uint8, compu-method=CM_MCU_FailCode1, data-constr=DC_MCU_FailCode1, transfer-property=PENDING, to VCU
          signal MCU_Softwae_FaultBit_oMCU_FailureCode_oKAMA_FP_EPT_0303: start 15, 19 bit, big-endian, i-signal-type=PRIMITIVE, init-value=0, base-type=uint32, compu-method=CM_MCU_Softwae_FaultBit, data-constr=DC_MCU_Softwae_FaultBit, transfer-property=PENDING, to VCU  # bit0£ºÄ¸ÏßµçÁ÷¹ýÁ÷¾¯¸æ bit:1£ºÄ¸ÏßµçÁ÷¹ýÁ÷¹ÊÕÏ bit2£ºÖ±Á÷Ä¸Ïß¹ýÑ¹¹ÊÕÏ bit3£ºÖ±Á÷Ä¸ÏßÇ·Ñ¹¹ÊÕÏ bit4£ºÖ±Á÷Ä¸Ïß¹ýÑ¹±¨¾¯ bit5£ºÖ±Á÷Ä¸ÏßÇ·Ñ¹±¨¾¯ bit6£ºµç»ú¹ýÎÂ¾¯¸æ bit7£ºµç»ú¹ýÎÂ¹ÊÕÏ bit8£ºÄæ±äÆ÷¹ýÎÂ¾¯¸æ bit9£ºÄæ±äÆ÷¹ýÎÂ¹ÊÕÏ bit10£ºµç»ú³¬ËÙ¾¯¸æ bit11£ºµç»ú³¬ËÙ¹ÊÕÏ bit12£ºMCIÍ¨Ñ¶µôÏß¹ÊÕÏ bit13£ºMCU´®¿ÚÐ£Ñé¹ÊÕÏ bit14£ºreverse bit15£ºreverse bit16£ºreverse bit18£ºreverse bit19£ºreverse
          signal MCU_Hardware_Fault_oMCU_FailureCode_oKAMA_FP_EPT_0303: start 39, 16 bit, big-endian, i-signal-type=PRIMITIVE, init-value=0, base-type=uint16, compu-method=CM_MCU_Hardware_Fault, data-constr=DC_MCU_Hardware_Fault, transfer-property=PENDING, to VCU  # bit0£ºÏàµçÁ÷Ó²¼þ¹ýÁ÷¹ÊÕÏ bit:1£ºCPLDÓ²¼þ¹ýÑ¹¹ÊÕÏ bit2£ºÃÅ¼«Çý¶¯µçÔ´Ó²¼þ¹ÊÕÏ bit3£ºCPLDÑÏÖØ¹ÊÕÏ bit4£ºÍâ²¿µÍÑ¹µçÑ¹Òì³£ bit5£ºÄÚ²¿Ð¾Æ¬µçÔ´¹ÊÕÏ bit6£º»·Â·»¥Ëø¹ÊÕÏ bit7£ºÖ÷Ð¾Æ¬¼ì²éCPLD¹ÊÕÏ bit8£º¸ßÑ¹MCU½ô¼±µçÔ´µçÑ¹¹ÊÕÏ bit9£ºreverse bit10£ºreverse bit11£ºreverse bit12£ºreverse bit13£ºreverse bit14£ºreverse bit15£ºreverse
          signal MCU_Sensor_Fault_oMCU_FailureCode_oKAMA_FP_EPT_0303: start 55, 8 bit, big-endian, i-signal-type=PRIMITIVE, init-value=0, base-type=uint8, compu-method=CM_MCU_Sensor_Fault, data-constr=DC_MCU_Sensor_Fault, transfer-property=PENDING, to VCU  # bit0£ºµç»úÎÂ¶È´«¸ÐÆ÷²ÉÑù¹ÊÕÏ bit:1£ºÏàµçÁ÷´«¸ÐÆ÷¹ÊÕÏ bit2£ºMCU×Ô¼ì¹ÊÕÏ bit3£ºreverse bit4£ºreverse bit5£ºreverse bit6£ºreverse bit7£ºreverse
          signal MCU_CAN_Fault_oMCU_FailureCode_oKAMA_FP_EPT_0303: start 63, 8 bit, big-endian, i-signal-type=PRIMITIVE, init-value=0, base-type=uint8, compu-method=CM_MCU_CAN_Fault, data-constr=DC_MCU_CAN_Fault, transfer-property=PENDING, to VCU  # bit0£ºCAN Bus off bit:1£ºreverse bit2£ºreverse bit3£ºreverse bit4£ºreverse bit5£ºreverse bit6£ºreverse bit7£ºreverse
      frame MCU_HardwareNumber_oKAMA_FP_EPT_0303: id 0x49B, to VCU, frame-length=8, can-addressing-mode=STANDARD
        pdu MCU_HardwareNumber_oKAMA_FP_EPT_0303: length=8, minimum-delay=0, transmission-mode-false-timing=cyclic-timing={time-offset=0, time-period=1}, transmission-mode-true-timing=cyclic-timing={time-offset=0, time-period=1}, unused-bit-pattern=0
          signal MCU_HwVer_oMCU_HardwareNumber_oKAMA_FP_EPT_0303: start 7, 16 bit, big-endian, i-signal-type=PRIMITIVE, init-value=0, base-type=uint16, compu-method=CM_MCU_HwVer, data-constr=DC_MCU_HwVer, transfer-property=PENDING, to VCU  # the version of hardwareÓ²¼þ°æ±¾
      frame MCU_SoftwareNumber_oKAMA_FP_EPT_0303: id 0x49A, to VCU, frame-length=8, can-addressing-mode=STANDARD
        pdu MCU_SoftwareNumber_oKAMA_FP_EPT_0303: length=8, minimum-delay=0, transmission-mode-false-timing=cyclic-timing={time-offset=0, time-period=1}, transmission-mode-true-timing=cyclic-timing={time-offset=0, time-period=1}, unused-bit-pattern=0
          signal MCU_CodeVer_oMCU_SoftwareNumber_oKAMA_FP_EPT_0303: start 7, 16 bit, big-endian, i-signal-type=PRIMITIVE, init-value=0, base-type=uint16, compu-method=CM_MCU_CodeVer, data-constr=DC_MCU_CodeVer, transfer-property=PENDING, to VCU  # the version of TC275 software codeÈí¼þ°æ±¾´úÂë
          signal MCU_DataVer_oMCU_SoftwareNumber_oKAMA_FP_EPT_0303: start 23, 16 bit, big-endian, i-signal-type=PRIMITIVE, init-value=0, base-type=uint16, compu-method=CM_MCU_DataVer, data-constr=DC_MCU_DataVer, transfer-property=PENDING, to VCU  # the version of TC275 software calibration data±ê¶¨Èí¼þ°æ±¾´úÂë
          signal MCU_CpldVer_oMCU_SoftwareNumber_oKAMA_FP_EPT_0303: start 39, 16 bit, big-endian, i-signal-type=PRIMITIVE, init-value=0, base-type=uint16, compu-method=CM_MCU_CpldVer, data-constr=DC_MCU_CpldVer, transfer-property=PENDING, to VCU  # the version of CPLD softwareÈí¼þ°æ±¾
          signal MCU_HvMcuVer_oMCU_SoftwareNumber_oKAMA_FP_EPT_0303: start 55, 16 bit, big-endian, i-signal-type=PRIMITIVE, init-value=0, base-type=uint16, compu-method=CM_MCU_HvMcuVer, data-constr=DC_MCU_HvMcuVer, transfer-property=PENDING, to VCU  # the version of Hv Mcu software¸ßÑ¹MCUÈí¼þ°æ±¾
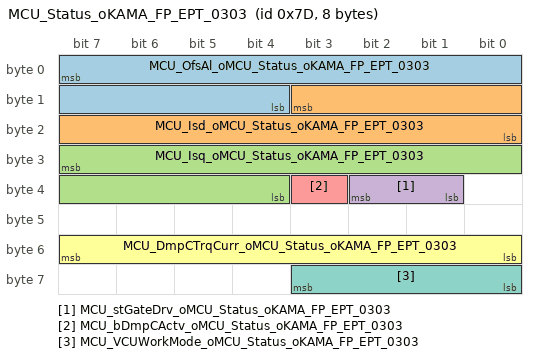
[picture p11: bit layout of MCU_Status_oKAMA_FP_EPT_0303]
      frame MCU_Status_oKAMA_FP_EPT_0303: id 0x7D, to VCU, frame-length=8, can-addressing-mode=STANDARD
        pdu MCU_Status_oKAMA_FP_EPT_0303: length=8, minimum-delay=0, transmission-mode-false-timing=cyclic-timing={time-offset=0, time-period=0.02}, transmission-mode-true-timing=cyclic-timing={time-offset=0, time-period=0.02}, unused-bit-pattern=0
          signal MCU_OfsAl_oMCU_Status_oKAMA_FP_EPT_0303: start 7, 12 bit, big-endian, i-signal-type=PRIMITIVE, init-value=0, base-type=uint16, compu-method=CM_MCU_OfsAl, data-constr=DC_MCU_OfsAl, transfer-property=PENDING, to VCU  # the offset angle of motorµç»úÆ«ÒÆ½Ç
          signal MCU_Isd_oMCU_Status_oKAMA_FP_EPT_0303: start 11, 12 bit, big-endian, i-signal-type=PRIMITIVE, init-value=2047, base-type=uint16, compu-method=CM_MCU_Isd, data-constr=DC_MCU_Isd, transfer-property=PENDING, to VCU  # the actual d axle current of MCU/µç»úDÏòµçÁ÷
          signal MCU_Isq_oMCU_Status_oKAMA_FP_EPT_0303: start 31, 12 bit, big-endian, i-signal-type=PRIMITIVE, init-value=2047, base-type=uint16, compu-method=CM_MCU_Isq, data-constr=DC_MCU_Isq, transfer-property=PENDING, to VCU  # the actual q axle current of MCU
          signal MCU_stGateDrv_oMCU_Status_oKAMA_FP_EPT_0303: start 34, 2 bit, big-endian, i-signal-type=PRIMITIVE, init-value=0, base-type=uint8, compu-method=CM_MCU_stGateDrv, data-constr=DC_MCU_stGateDrv, transfer-property=PENDING, to VCU  # the gate drive status of MCU¿ª¹Ü×´Ì¬
          signal MCU_bDmpCActv_oMCU_Status_oKAMA_FP_EPT_0303: start 35, 1 bit, big-endian, i-signal-type=PRIMITIVE, init-value=0, base-type=boolean, compu-method=CM_MCU_bDmpCActv, data-constr=DC_MCU_bDmpCActv, transfer-property=PENDING, to VCU  # the damping control enable flag of motor·À¶¶¹¦ÄÜ×´Ì¬
          signal MCU_DmpCTrqCurr_oMCU_Status_oKAMA_FP_EPT_0303: start 55, 8 bit, big-endian, i-signal-type=PRIMITIVE, init-value=0, base-type=uint8, compu-method=CM_MCU_DmpCTrqCurr, data-constr=DC_MCU_DmpCTrqCurr, unit=U_Nm, transfer-property=PENDING, to VCU  # the actual torque of motor without damping control compensationÃ»ÓÐ×èÄá²¹³¥µÄµç»úÊµÊ±Á¦¾Ø
          signal MCU_VCUWorkMode_oMCU_Status_oKAMA_FP_EPT_0303: start 59, 4 bit, big-endian, i-signal-type=PRIMITIVE, init-value=0, base-type=uint8, compu-method=CM_MCU_VCUWorkMode, data-constr=DC_MCU_VCUWorkMode, transfer-property=PENDING, to VCU  # the actual running mode of motor¹¤×÷Ä£Ê½
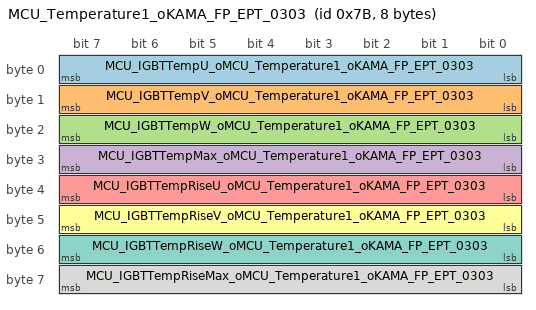
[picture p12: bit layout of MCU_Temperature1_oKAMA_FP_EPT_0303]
      frame MCU_Temperature1_oKAMA_FP_EPT_0303: id 0x7B, to VCU, frame-length=8, can-addressing-mode=STANDARD
        pdu MCU_Temperature1_oKAMA_FP_EPT_0303: length=8, minimum-delay=0, transmission-mode-false-timing=cyclic-timing={time-offset=0, time-period=0.5}, transmission-mode-true-timing=cyclic-timing={time-offset=0, time-period=0.5}, unused-bit-pattern=0
          signal MCU_IGBTTempU_oMCU_Temperature1_oKAMA_FP_EPT_0303: start 7, 8 bit, big-endian, i-signal-type=PRIMITIVE, init-value=255, base-type=uint8, compu-method=CM_MCU_IGBTTempU, data-constr=DC_MCU_IGBTTempU, transfer-property=PENDING, to VCU  # the temperature of U phase IGBT/ UÏîIGBTÎÂ¶È
          signal MCU_IGBTTempV_oMCU_Temperature1_oKAMA_FP_EPT_0303: start 15, 8 bit, big-endian, i-signal-type=PRIMITIVE, init-value=255, base-type=uint8, compu-method=CM_MCU_IGBTTempV, data-constr=DC_MCU_IGBTTempV, transfer-property=PENDING, to VCU  # the temperature of V phase IGBT
          signal MCU_IGBTTempW_oMCU_Temperature1_oKAMA_FP_EPT_0303: start 23, 8 bit, big-endian, i-signal-type=PRIMITIVE, init-value=255, base-type=uint8, compu-method=CM_MCU_IGBTTempW, data-constr=DC_MCU_IGBTTempW, transfer-property=PENDING, to VCU  # the temperature of W phase IGBT
          signal MCU_IGBTTempMax_oMCU_Temperature1_oKAMA_FP_EPT_0303: start 31, 8 bit, big-endian, i-signal-type=PRIMITIVE, init-value=255, base-type=uint8, compu-method=CM_MCU_IGBTTempMax, data-constr=DC_MCU_IGBTTempMax, transfer-property=PENDING, to VCU  # the temperature of Max phase IGBT
          signal MCU_IGBTTempRiseU_oMCU_Temperature1_oKAMA_FP_EPT_0303: start 39, 8 bit, big-endian, i-signal-type=PRIMITIVE, init-value=255, base-type=uint8, compu-method=CM_MCU_IGBTTempRiseU, data-constr=DC_MCU_IGBTTempRiseU, transfer-property=PENDING, to VCU  # the temperature rise of U phase IGBT/ UÏîIGBTÎÂÉý
          signal MCU_IGBTTempRiseV_oMCU_Temperature1_oKAMA_FP_EPT_0303: start 47, 8 bit, big-endian, i-signal-type=PRIMITIVE, init-value=255, base-type=uint8, compu-method=CM_MCU_IGBTTempRiseV, data-constr=DC_MCU_IGBTTempRiseV, transfer-property=PENDING, to VCU  # the temperature rise of V phase IGBT
          signal MCU_IGBTTempRiseW_oMCU_Temperature1_oKAMA_FP_EPT_0303: start 55, 8 bit, big-endian, i-signal-type=PRIMITIVE, init-value=255, base-type=uint8, compu-method=CM_MCU_IGBTTempRiseW, data-constr=DC_MCU_IGBTTempRiseW, transfer-property=PENDING, to VCU  # the temperature rise of W phase IGBT
          signal MCU_IGBTTempRiseMax_oMCU_Temperature1_oKAMA_FP_EPT_0303: start 63, 8 bit, big-endian, i-signal-type=PRIMITIVE, init-value=255, base-type=uint8, compu-method=CM_MCU_IGBTTempRiseMax, data-constr=DC_MCU_IGBTTempRiseMax, transfer-property=PENDING, to VCU  # the temperature rise of Max phase IGBT
      frame MCU_Temperature2_oKAMA_FP_EPT_0303: id 0x7C, to VCU, frame-length=8, can-addressing-mode=STANDARD
        pdu MCU_Temperature2_oKAMA_FP_EPT_0303: length=8, minimum-delay=0, transmission-mode-false-timing=cyclic-timing={time-offset=0, time-period=0.5}, transmission-mode-true-timing=cyclic-timing={time-offset=0, time-period=0.5}, unused-bit-pattern=0
          signal MCU_TempCurrCool_oMCU_Temperature2_oKAMA_FP_EPT_0303: start 7, 8 bit, big-endian, i-signal-type=PRIMITIVE, init-value=255, base-type=uint8, compu-method=CM_MCU_TempCurrCool, data-constr=DC_MCU_TempCurrCool, transfer-property=PENDING, to VCU  # the temperature of coolantÀäÈ´ÒºÎÂ¶È
          signal MCU_TempCurrStr1_oMCU_Temperature2_oKAMA_FP_EPT_0303: start 15, 8 bit, big-endian, i-signal-type=PRIMITIVE, init-value=255, base-type=uint8, compu-method=CM_MCU_TempCurrStr1, data-constr=DC_MCU_TempCurrStr1, transfer-property=PENDING, to VCU  # the temperature of stator NTC1 µç»úÎÂ¶È
          signal MCU_TempCurrStr2_oMCU_Temperature2_oKAMA_FP_EPT_0303: start 23, 8 bit, big-endian, i-signal-type=PRIMITIVE, init-value=255, base-type=uint8, compu-method=CM_MCU_TempCurrStr2, data-constr=DC_MCU_TempCurrStr2, transfer-property=PENDING, to VCU  # the temperature of stator NTC2
          signal MCU_TempCurrStr_oMCU_Temperature2_oKAMA_FP_EPT_0303: start 31, 8 bit, big-endian, i-signal-type=PRIMITIVE, init-value=255, base-type=uint8, compu-method=CM_MCU_TempCurrStr, data-constr=DC_MCU_TempCurrStr, transfer-property=PENDING, to VCU  # the temperature of Max stator NTCµç»ú×î¸ßÎÂ¶È
          signal MCU_TempRiseCurrStr_oMCU_Temperature2_oKAMA_FP_EPT_0303: start 39, 8 bit, big-endian, i-signal-type=PRIMITIVE, init-value=0, base-type=uint8, compu-method=CM_MCU_TempRiseCurrStr, data-constr=DC_MCU_TempRiseCurrStr, transfer-property=PENDING, to VCU  # the temperature of stator NTC1 µç»úÎÂÉý
          signal MCU_TempStatus_oMCU_Temperature2_oKAMA_FP_EPT_0303: start 47, 2 bit, big-endian, i-signal-type=PRIMITIVE, init-value=0, base-type=uint8, compu-method=CM_MCU_TempStatus, data-constr=DC_MCU_TempStatus, transfer-property=PENDING, to VCU  # The E-motor temperature stateÎÂ¶È×´Ì¬
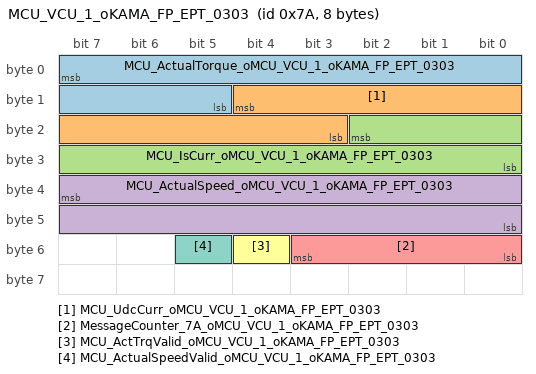
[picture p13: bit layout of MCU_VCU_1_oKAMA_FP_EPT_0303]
      frame MCU_VCU_1_oKAMA_FP_EPT_0303: id 0x7A, to VCU, frame-length=8, can-addressing-mode=STANDARD
        pdu MCU_VCU_1_oKAMA_FP_EPT_0303: length=8, minimum-delay=0, transmission-mode-false-timing=cyclic-timing={time-offset=0, time-period=0.01}, transmission-mode-true-timing=cyclic-timing={time-offset=0, time-period=0.01}, unused-bit-pattern=0
          signal MCU_ActualTorque_oMCU_VCU_1_oKAMA_FP_EPT_0303: start 7, 11 bit, big-endian, i-signal-type=PRIMITIVE, init-value=1024, base-type=uint16, compu-method=CM_MCU_ActualTorque, data-constr=DC_MCU_ActualTorque, transfer-property=PENDING, to VCU  # the actual torque of motorµç»úÊµÊ±Á¦¾Ø
          signal MCU_UdcCurr_oMCU_VCU_1_oKAMA_FP_EPT_0303: start 12, 10 bit, big-endian, i-signal-type=PRIMITIVE, init-value=0, base-type=uint16, compu-method=CM_MCU_UdcCurr, data-constr=DC_MCU_UdcCurr, transfer-property=PENDING, to VCU  # the actual voltage of udclinkÊµÊ±Ö±Á÷µçÑ¹
          signal MCU_IsCurr_oMCU_VCU_1_oKAMA_FP_EPT_0303: start 18, 11 bit, big-endian, i-signal-type=PRIMITIVE, init-value=0, base-type=uint16, compu-method=CM_MCU_IsCurr, data-constr=DC_MCU_IsCurr, transfer-property=PENDING, to VCU  # the actual current ÊµÊ±Ö±Á÷µçÁ÷£¨¹ÀËãµçÁ÷£©
          signal MCU_ActualSpeed_oMCU_VCU_1_oKAMA_FP_EPT_0303: start 39, 16 bit, big-endian, i-signal-type=PRIMITIVE, init-value=32768, base-type=uint16, compu-method=CM_MCU_ActualSpeed, data-constr=DC_MCU_ActualSpeed, transfer-property=PENDING, to VCU  # the actual motor speedµç»úÊµÊ±×ªËÙ
          signal MessageCounter_7A_oMCU_VCU_1_oKAMA_FP_EPT_0303: start 51, 4 bit, big-endian, i-signal-type=PRIMITIVE, init-value=0, base-type=uint8, compu-method=CM_MessageCounter_7A, data-constr=DC_MessageCounter_7A, transfer-property=PENDING, to VCU  # rolling counter
          signal MCU_ActTrqValid_oMCU_VCU_1_oKAMA_FP_EPT_0303: start 52, 1 bit, big-endian, i-signal-type=PRIMITIVE, init-value=0, base-type=boolean, compu-method=CM_MCU_ActTrqValid, data-constr=DC_MCU_ActTrqValid, transfer-property=PENDING, to VCU  # µç»úÊµ¼ÊÅ¤¾ØÖµÓÐÐ§ÐÔ
          signal MCU_ActualSpeedValid_oMCU_VCU_1_oKAMA_FP_EPT_0303: start 53, 1 bit, big-endian, i-signal-type=PRIMITIVE, init-value=0, base-type=boolean, compu-method=CM_MCU_ActualSpeedValid, data-constr=DC_MCU_ActualSpeedValid, transfer-property=PENDING, to VCU  # µç»úÊµÊ±×ªËÙÓÐÐ§ÐÔ
      frame OBC_Error_STATUS_oKAMA_FP_EPT_0303: id 0x37A, to VCU, frame-length=8, can-addressing-mode=STANDARD
        pdu OBC_Error_STATUS_oKAMA_FP_EPT_0303: length=8, minimum-delay=0, transmission-mode-false-timing=cyclic-timing={time-offset=0, time-period=0.2}, transmission-mode-true-timing=cyclic-timing={time-offset=0, time-period=0.2}, unused-bit-pattern=0
          signal OBC_DCVoltHighFault_oOBC_Error_STATUS_oKAMA_FP_EPT_0303: start 0, 1 bit, big-endian, i-signal-type=PRIMITIVE, init-value=0, base-type=boolean, compu-method=CM_OBC_DCVoltHighFault, data-constr=DC_OBC_DCVoltHighFault, transfer-property=PENDING, to VCU  # Charger DC side overvoltage fault
          signal OBC_FaultLevel_oOBC_Error_STATUS_oKAMA_FP_EPT_0303: start 2, 2 bit, big-endian, i-signal-type=PRIMITIVE, init-value=0, base-type=uint8, compu-method=CM_OBC_FaultLevel, data-constr=DC_OBC_FaultLevel, transfer-property=PENDING, to VCU  # no fault?this value means the OBC is normal. Recoverable fault?OBC will down power and wait for the fault clear, and retry. Unrecoverable fault?when OBC detect this fault, OBC should stop output and power down,when the power is reduced, also need to send this signal
          signal OBC_DCVoltLowFault_oOBC_Error_STATUS_oKAMA_FP_EPT_0303: start 3, 1 bit, big-endian, i-signal-type=PRIMITIVE, init-value=0, base-type=boolean, compu-method=CM_OBC_DCVoltLowFault, data-constr=DC_OBC_DCVoltLowFault, transfer-property=PENDING, to VCU  # Charger DC side undervoltage fault
          signal OBC_ACPortTempBSensValid_oOBC_Error_STATUS_oKAMA_FP_EPT_0303: start 5, 2 bit, big-endian, i-signal-type=PRIMITIVE, init-value=0, base-type=uint8, compu-method=CM_OBC_ACPortTempBSensValid, data-constr=DC_OBC_ACPortTempBSensValid, transfer-property=PENDING, to VCU  # Error state for the temperature sensor. E.g. damaged or short circuit at the temperature sensor in the inlet.
          signal OBC_ACPortTempASensValid_oOBC_Error_STATUS_oKAMA_FP_EPT_0303: start 7, 2 bit, big-endian, i-signal-type=PRIMITIVE, init-value=0, base-type=uint8, compu-method=CM_OBC_ACPortTempASensValid, data-constr=DC_OBC_ACPortTempASensValid, transfer-property=PENDING, to VCU  # Error state for the temperature sensor. E.g. damaged or short circuit at the temperature sensor in the inlet.
          signal OBC_NlineStatus_oOBC_Error_STATUS_oKAMA_FP_EPT_0303: start 8, 1 bit, big-endian, i-signal-type=PRIMITIVE, init-value=0, base-type=boolean, compu-method=CM_OBC_NlineStatus, data-constr=DC_OBC_NlineStatus, transfer-property=PENDING, to VCU  # Whether AC side N line disconnect
          signal OBC_ACPortTempAerror_oOBC_Error_STATUS_oKAMA_FP_EPT_0303: start 9, 1 bit, big-endian, i-signal-type=PRIMITIVE, init-value=0, base-type=boolean, compu-method=CM_OBC_ACPortTempAerror, data-constr=DC_OBC_ACPortTempAerror, transfer-property=PENDING, to VCU  # sensor A temporature error
          signal OBC_ACVoltLowFault_oOBC_Error_STATUS_oKAMA_FP_EPT_0303: start 10, 1 bit, big-endian, i-signal-type=PRIMITIVE, init-value=0, base-type=boolean, compu-method=CM_OBC_ACVoltLowFault, data-constr=DC_OBC_ACVoltLowFault, transfer-property=PENDING, to VCU  # Charger AC side undervoltage fault
          signal OBC_ACVoltHighFault_oOBC_Error_STATUS_oKAMA_FP_EPT_0303: start 11, 1 bit, big-endian, i-signal-type=PRIMITIVE, init-value=0, base-type=boolean, compu-method=CM_OBC_ACVoltHighFault, data-constr=DC_OBC_ACVoltHighFault, transfer-property=PENDING, to VCU  # Charger AC side overvoltage fault
          signal OBC_DCCurHighFault_oOBC_Error_STATUS_oKAMA_FP_EPT_0303: start 13, 1 bit, big-endian, i-signal-type=PRIMITIVE, init-value=0, base-type=boolean, compu-method=CM_OBC_DCCurHighFault, data-constr=DC_OBC_DCCurHighFault, transfer-property=PENDING, to VCU  # Charger DC side over current fault
          signal OBC_CommunFault_oOBC_Error_STATUS_oKAMA_FP_EPT_0303: start 14, 1 bit, big-endian, i-signal-type=PRIMITIVE, init-value=0, base-type=boolean, compu-method=CM_OBC_CommunFault, data-constr=DC_OBC_CommunFault, transfer-property=PENDING, to VCU  # OBC communication fault
          signal OBC_StartUpAllowed_oOBC_Error_STATUS_oKAMA_FP_EPT_0303: start 15, 1 bit, big-endian, i-signal-type=PRIMITIVE, init-value=0, base-type=boolean, compu-method=CM_OBC_StartUpAllowed, data-constr=DC_OBC_StartUpAllowed, transfer-property=PENDING, to VCU  # OBC startup status
          signal OBC_OutputShortError_oOBC_Error_STATUS_oKAMA_FP_EPT_0303: start 16, 1 bit, big-endian, i-signal-type=PRIMITIVE, init-value=0, base-type=boolean, compu-method=CM_OBC_OutputShortError, data-constr=DC_OBC_OutputShortError, transfer-property=PENDING, to VCU  # Output short
          signal OBC_PFCOverVoltageError_oOBC_Error_STATUS_oKAMA_FP_EPT_0303: start 17, 1 bit, big-endian, i-signal-type=PRIMITIVE, init-value=0, base-type=boolean, compu-method=CM_OBC_PFCOverVoltageError, data-constr=DC_OBC_PFCOverVoltageError, transfer-property=PENDING, to VCU  # VBUS over voltage
          signal OBC_PFCUnderVoltageError_oOBC_Error_STATUS_oKAMA_FP_EPT_0303: start 18, 1 bit, big-endian, i-signal-type=PRIMITIVE, init-value=0, base-type=boolean, compu-method=CM_OBC_PFCUnderVoltageError, data-constr=DC_OBC_PFCUnderVoltageError, transfer-property=PENDING, to VCU  # VBUS undervoltage
          signal OBC_InputOverCurrentstatus_T_oOBC_Error_STATUS_oKAMA_FP_EPT_0303: start 19, 1 bit, big-endian, i-signal-type=PRIMITIVE, init-value=0, base-type=boolean, compu-method=CM_OBC_InputOverCurrentstatus_T, data-constr=DC_OBC_InputOverCurrentstatus_T, transfer-property=PENDING, to VCU  # PFC input over current between L3 and N
          signal OBC_InputOverCurrentstatus_S_oOBC_Error_STATUS_oKAMA_FP_EPT_0303: start 20, 1 bit, big-endian, i-signal-type=PRIMITIVE, init-value=0, base-type=boolean, compu-method=CM_OBC_InputOverCurrentstatus_S, data-constr=DC_OBC_InputOverCurrentstatus_S, transfer-property=PENDING, to VCU  # PFC input over current between L2 and N
          signal OBC_InputOverCurrentstatus_R_oOBC_Error_STATUS_oKAMA_FP_EPT_0303: start 21, 1 bit, big-endian, i-signal-type=PRIMITIVE, init-value=0, base-type=boolean, compu-method=CM_OBC_InputOverCurrentstatus_R, data-constr=DC_OBC_InputOverCurrentstatus_R, transfer-property=PENDING, to VCU  # PFC input over current between L1 and N
          signal OBC_InputPhaseStatus_oOBC_Error_STATUS_oKAMA_FP_EPT_0303: start 22, 1 bit, big-endian, i-signal-type=PRIMITIVE, init-value=0, base-type=boolean, compu-method=CM_OBC_InputPhaseStatus, data-constr=DC_OBC_InputPhaseStatus, transfer-property=PENDING, to VCU  # Whether AC side Lack of input phase
          signal OBC_InputFrequencyStatus_oOBC_Error_STATUS_oKAMA_FP_EPT_0303: start 23, 1 bit, big-endian, i-signal-type=PRIMITIVE, init-value=0, base-type=boolean, compu-method=CM_OBC_InputFrequencyStatus, data-constr=DC_OBC_InputFrequencyStatus, transfer-property=PENDING, to VCU  # Whether AC side frequency abnormal
          signal OBC_ACPortTempBerror_oOBC_Error_STATUS_oKAMA_FP_EPT_0303: start 24, 1 bit, big-endian, i-signal-type=PRIMITIVE, init-value=0, base-type=boolean, compu-method=CM_OBC_ACPortTempBerror, data-constr=DC_OBC_ACPortTempBerror, transfer-property=PENDING, to VCU  # sensor B temporature error
          signal OBC_internalFault_oOBC_Error_STATUS_oKAMA_FP_EPT_0303: start 25, 1 bit, big-endian, i-signal-type=PRIMITIVE, init-value=0, base-type=boolean, compu-method=CM_OBC_internalFault, data-constr=DC_OBC_internalFault, transfer-property=PENDING, to VCU  # OBC internal fault(internal error)
          signal OBC_ComFault2_oOBC_Error_STATUS_oKAMA_FP_EPT_0303: start 26, 1 bit, big-endian, i-signal-type=PRIMITIVE, init-value=0, base-type=boolean, compu-method=CM_OBC_ComFault2, data-constr=DC_OBC_ComFault2, transfer-property=PENDING, to VCU  # Microcontroller communication error with secordary side
          signal OBC_ComFault1_oOBC_Error_STATUS_oKAMA_FP_EPT_0303: start 27, 1 bit, big-endian, i-signal-type=PRIMITIVE, init-value=0, base-type=boolean, compu-method=CM_OBC_ComFault1, data-constr=DC_OBC_ComFault1, transfer-property=PENDING, to VCU  # Microcontroller communication error with primary side
          signal OBC_SecordarySideOvertempStatus_oOBC_Error_STATUS_oKAMA_FP_EPT_0303: start 28, 1 bit, big-endian, i-signal-type=PRIMITIVE, init-value=0, base-type=boolean, compu-method=CM_OBC_SecordarySideOvertempStatus, data-constr=DC_OBC_SecordarySideOvertempStatus, transfer-property=PENDING, to VCU  # Secordary side overtemp
          signal OBC_PrimarySideOvertempStatus_oOBC_Error_STATUS_oKAMA_FP_EPT_0303: start 29, 1 bit, big-endian, i-signal-type=PRIMITIVE, init-value=0, base-type=boolean, compu-method=CM_OBC_PrimarySideOvertempStatus, data-constr=DC_OBC_PrimarySideOvertempStatus, transfer-property=PENDING, to VCU  # Primary side overtemp,at primary side ,we have total three temporature check point, but we only need to check the maximum value error
          signal POD_faultTemp_oOBC_Error_STATUS_oKAMA_FP_EPT_0303: start 30, 1 bit, big-endian, i-signal-type=PRIMITIVE, init-value=0, base-type=boolean, compu-method=CM_POD_faultTemp, data-constr=DC_POD_faultTemp, transfer-property=PENDING, to VCU  # AC Charge port over temp
          signal OBC_PrimarySideTemp_oOBC_Error_STATUS_oKAMA_FP_EPT_0303: start 39, 8 bit, big-endian, i-signal-type=PRIMITIVE, init-value=40, base-type=uint8, compu-method=CM_OBC_PrimarySideTemp, data-constr=DC_OBC_PrimarySideTemp, transfer-property=PENDING, to VCU  # This signal is sent to TMS,according to this signal, TCU request reduce the temporature of water,and we have total three temporature check point, but we only need to check the maximum value
          signal OBC_SecondarySideTemp_oOBC_Error_STATUS_oKAMA_FP_EPT_0303: start 47, 8 bit, big-endian, i-signal-type=PRIMITIVE, init-value=40, base-type=uint8, compu-method=CM_OBC_SecondarySideTemp, data-constr=DC_OBC_SecondarySideTemp, transfer-property=PENDING, to VCU  # This signal is sent to TMS,according to this signal, TCU request reduce the temporature of water.
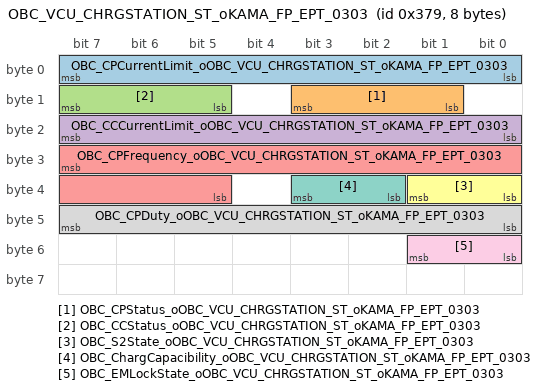
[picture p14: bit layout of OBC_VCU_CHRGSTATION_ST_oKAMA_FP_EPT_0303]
      frame OBC_VCU_CHRGSTATION_ST_oKAMA_FP_EPT_0303: id 0x379, to VCU, frame-length=8, can-addressing-mode=STANDARD
        pdu OBC_VCU_CHRGSTATION_ST_oKAMA_FP_EPT_0303: length=8, minimum-delay=0, transmission-mode-false-timing=cyclic-timing={time-offset=0, time-period=0.05}, transmission-mode-true-timing=cyclic-timing={time-offset=0, time-period=0.05}, unused-bit-pattern=0
          signal OBC_CPCurrentLimit_oOBC_VCU_CHRGSTATION_ST_oKAMA_FP_EPT_0303: start 7, 8 bit, big-endian, i-signal-type=PRIMITIVE, init-value=0, base-type=uint8, compu-method=CM_OBC_CPCurrentLimit, data-constr=DC_OBC_CPCurrentLimit, unit=U_A, transfer-property=PENDING, to VCU  # Maximum AC current of infrastructure signalled by charging station with Duty-Cycle on the CP-PWM-Signal.
          signal OBC_CPStatus_oOBC_VCU_CHRGSTATION_ST_oKAMA_FP_EPT_0303: start 11, 3 bit, big-endian, i-signal-type=PRIMITIVE, init-value=0, base-type=uint8, compu-method=CM_OBC_CPStatus, data-constr=DC_OBC_CPStatus, transfer-property=PENDING, to VCU  # Feedback the connected status of CP to VCU
          signal OBC_CCStatus_oOBC_VCU_CHRGSTATION_ST_oKAMA_FP_EPT_0303: start 15, 3 bit, big-endian, i-signal-type=PRIMITIVE, init-value=0, base-type=uint8, compu-method=CM_OBC_CCStatus, data-constr=DC_OBC_CCStatus, transfer-property=PENDING, to VCU  # 0£ºunconnected 1£ºHalf-connected 2£º1500Ohm 3£º680Ohm 4£º220Ohm 5: 100Ohm 6: 2000Ohm 7£º¹ÊÕÏ
          signal OBC_CCCurrentLimit_oOBC_VCU_CHRGSTATION_ST_oKAMA_FP_EPT_0303: start 23, 8 bit, big-endian, i-signal-type=PRIMITIVE, init-value=0, base-type=uint8, compu-method=CM_OBC_CCCurrentLimit, data-constr=DC_OBC_CCCurrentLimit, unit=U_A, transfer-property=PENDING, to VCU  # Maximum AC current of vehicle plug and cable detected by the EV. For different charging plugs and cables e.g. with lower current performance then the charging station there are seperate values of resistors (RC and R4) inside the charging plug
          signal OBC_CPFrequency_oOBC_VCU_CHRGSTATION_ST_oKAMA_FP_EPT_0303: start 31, 11 bit, big-endian, i-signal-type=PRIMITIVE, init-value=0, base-type=uint16, compu-method=CM_OBC_CPFrequency, data-constr=DC_OBC_CPFrequency, unit=U_Hz, transfer-property=PENDING, to VCU  # CP frequency
          signal OBC_S2State_oOBC_VCU_CHRGSTATION_ST_oKAMA_FP_EPT_0303: start 33, 2 bit, big-endian, i-signal-type=PRIMITIVE, init-value=0, base-type=uint8, compu-method=CM_OBC_S2State, data-constr=DC_OBC_S2State, transfer-property=PENDING, to VCU  # Give feedback of S2 status to VCU
          signal OBC_ChargCapacibility_oOBC_VCU_CHRGSTATION_ST_oKAMA_FP_EPT_0303: start 35, 2 bit, big-endian, i-signal-type=PRIMITIVE, init-value=0, base-type=uint8, compu-method=CM_OBC_ChargCapacibility, data-constr=DC_OBC_ChargCapacibility, transfer-property=PENDING, to VCU  # single-phase or three-phase
          signal OBC_CPDuty_oOBC_VCU_CHRGSTATION_ST_oKAMA_FP_EPT_0303: start 47, 8 bit, big-endian, i-signal-type=PRIMITIVE, init-value=0, base-type=uint8, compu-method=CM_OBC_CPDuty, data-constr=DC_OBC_CPDuty, unit=U_p, transfer-property=PENDING, to VCU  # CP Duty
          signal OBC_EMLockState_oOBC_VCU_CHRGSTATION_ST_oKAMA_FP_EPT_0303: start 49, 2 bit, big-endian, i-signal-type=PRIMITIVE, init-value=0, base-type=uint8, compu-method=CM_OBC_EMLockState, data-constr=DC_OBC_EMLockState, transfer-property=PENDING, to VCU  # Give feedback of EM lock status to VCU
      frame OBC_VCU_STATUS1_oKAMA_FP_EPT_0303: id 0x377, to VCU, frame-length=8, can-addressing-mode=STANDARD
        pdu OBC_VCU_STATUS1_oKAMA_FP_EPT_0303: length=8, minimum-delay=0, transmission-mode-false-timing=cyclic-timing={time-offset=0, time-period=0.1}, transmission-mode-true-timing=cyclic-timing={time-offset=0, time-period=0.1}, unused-bit-pattern=0
          signal OBC_InputACCurrent_oOBC_VCU_STATUS1_oKAMA_FP_EPT_0303: start 7, 13 bit, big-endian, i-signal-type=PRIMITIVE, init-value=0, base-type=uint16, compu-method=CM_OBC_InputACCurrent, data-constr=DC_OBC_InputACCurrent, unit=U_A, transfer-property=PENDING, to VCU  # Report OBC AC current(when singal charging,it is 32A£¬when three-phase charging ,report the maximum current of one phase)
          signal OBC_ChargeStatus_oOBC_VCU_STATUS1_oKAMA_FP_EPT_0303: start 10, 3 bit, big-endian, i-signal-type=PRIMITIVE, init-value=0, base-type=uint8, compu-method=CM_OBC_ChargeStatus, data-constr=DC_OBC_ChargeStatus, transfer-property=PENDING, to VCU  # Idle? when OBC shut up & be able to send message / Ready?when OBC finish init. & itself detec./Charging/ Fault?when OBC Fault Level=?Recoverable fault?,stop output but not power down /Level=?Unrecoverable fault?,stop output and pow.down /Stop?stop pow.down
          signal OBC_InputACVoltage_oOBC_VCU_STATUS1_oKAMA_FP_EPT_0303: start 23, 16 bit, big-endian, i-signal-type=PRIMITIVE, init-value=0, base-type=uint16, compu-method=CM_OBC_InputACVoltage, data-constr=DC_OBC_InputACVoltage, unit=U_V, transfer-property=PENDING, to VCU  # Input voltage to OBC This signal means the input phase voltage to OBC. When it is a three-phase charge, the minimum voltage of each phase is reported
          signal OBC_OutputDCChargeVoltage_oOBC_VCU_STATUS1_oKAMA_FP_EPT_0303: start 39, 13 bit, big-endian, i-signal-type=PRIMITIVE, init-value=0, base-type=uint16, compu-method=CM_OBC_OutputDCChargeVoltage, data-constr=DC_OBC_OutputDCChargeVoltage, unit=U_V, transfer-property=PENDING, to VCU  # OutputDCChargeVoltage
          signal OBC_OBCMaxPermOutpCrrt_oOBC_VCU_STATUS1_oKAMA_FP_EPT_0303: start 55, 9 bit, big-endian, i-signal-type=PRIMITIVE, init-value=0, base-type=uint16, compu-method=CM_OBC_OBCMaxPermOutpCrrt, data-constr=DC_OBC_OBCMaxPermOutpCrrt, unit=U_A, transfer-property=PENDING, to VCU  # Report OBC Max Permit Output Current
      frame OBC_VCU_STATUS2_oKAMA_FP_EPT_0303: id 0x378, to VCU, frame-length=8, can-addressing-mode=STANDARD
        pdu OBC_VCU_STATUS2_oKAMA_FP_EPT_0303: length=8, minimum-delay=0, transmission-mode-false-timing=cyclic-timing={time-offset=0, time-period=0.1}, transmission-mode-true-timing=cyclic-timing={time-offset=0, time-period=0.1}, unused-bit-pattern=0
          signal OBC_ChrgOutpPwrAvl_oOBC_VCU_STATUS2_oKAMA_FP_EPT_0303: start 7, 8 bit, big-endian, i-signal-type=PRIMITIVE, init-value=0, base-type=uint8, compu-method=CM_OBC_ChrgOutpPwrAvl, data-constr=DC_OBC_ChrgOutpPwrAvl, unit=U_KW, transfer-property=PENDING, to VCU  # Report the maximum output power at present.
          signal OBC_OutputDCChargeCurrent_oOBC_VCU_STATUS2_oKAMA_FP_EPT_0303: start 15, 13 bit, big-endian, i-signal-type=PRIMITIVE, init-value=0, base-type=uint16, compu-method=CM_OBC_OutputDCChargeCurrent, data-constr=DC_OBC_OutputDCChargeCurrent, unit=U_A, transfer-property=PENDING, to VCU  # OBC output current when charge
          signal OBC_ACPortTempA_oOBC_VCU_STATUS2_oKAMA_FP_EPT_0303: start 31, 8 bit, big-endian, i-signal-type=PRIMITIVE, init-value=255, base-type=uint8, compu-method=CM_OBC_ACPortTempA, data-constr=DC_OBC_ACPortTempA, transfer-property=PENDING, to VCU  # Actual temperatur connector A
          signal OBC_ACPortTempB_oOBC_VCU_STATUS2_oKAMA_FP_EPT_0303: start 39, 8 bit, big-endian, i-signal-type=PRIMITIVE, init-value=255, base-type=uint8, compu-method=CM_OBC_ACPortTempB, data-constr=DC_OBC_ACPortTempB, transfer-property=PENDING, to VCU  # Actual temperatur connector B
      frame OBDFunRequest_oKAMA_FP_EPT_0303: id 0x733, to VCU, frame-length=8, can-addressing-mode=STANDARD
        n pdu OBDFunRequest_Tp_oKAMA_FP_EPT_0303: length=8
      frame OBDRequest_oKAMA_FP_EPT_0303: id 0x7E0, to VCU, frame-length=8, can-addressing-mode=STANDARD
        n pdu OBDRequest_Tp_oKAMA_FP_EPT_0303: length=8
      frame OBDResponse_oKAMA_FP_EPT_0303: id 0x7E8, from VCU, frame-length=8, can-addressing-mode=STANDARD
        n pdu OBDResponse_Tp_oKAMA_FP_EPT_0303: length=8
      frame POD_VCU_Status_01_oKAMA_FP_EPT_0303: id 0x370, to VCU, frame-length=8, can-addressing-mode=STANDARD
        pdu POD_VCU_Status_01_oKAMA_FP_EPT_0303: length=8, minimum-delay=0, transmission-mode-false-timing=cyclic-timing={time-offset=0, time-period=0.1}, transmission-mode-true-timing=cyclic-timing={time-offset=0, time-period=0.1}, unused-bit-pattern=0
          signal POD_DCFCCurrent_oPOD_VCU_Status_01_oKAMA_FP_EPT_0303: start 7, 11 bit, big-endian, i-signal-type=PRIMITIVE, init-value=0, base-type=uint16, compu-method=CM_POD_DCFCCurrent, data-constr=DC_POD_DCFCCurrent, unit=U_A, transfer-property=PENDING, to VCU  # DC relay out side current
          signal POD_DCFCVoltage_oPOD_VCU_Status_01_oKAMA_FP_EPT_0303: start 12, 13 bit, big-endian, i-signal-type=PRIMITIVE, init-value=0, base-type=uint16, compu-method=CM_POD_DCFCVoltage, data-constr=DC_POD_DCFCVoltage, unit=U_V, transfer-property=PENDING, to VCU  # DC relay out side voltage
          signal POD_Temperature_oPOD_VCU_Status_01_oKAMA_FP_EPT_0303: start 31, 8 bit, big-endian, i-signal-type=PRIMITIVE, init-value=255, base-type=uint8, compu-method=CM_POD_Temperature, data-constr=DC_POD_Temperature, transfer-property=PENDING, to VCU  # This signal reflects the temperature of Coolant outlet and structure
          signal POD_DCInletTempA_oPOD_VCU_Status_01_oKAMA_FP_EPT_0303: start 39, 8 bit, big-endian, i-signal-type=PRIMITIVE, init-value=255, base-type=uint8, compu-method=CM_POD_DCInletTempA, data-constr=DC_POD_DCInletTempA, transfer-property=PENDING, to VCU  # Actual DC + temperatur connector
          signal POD_DCInletTempB_oPOD_VCU_Status_01_oKAMA_FP_EPT_0303: start 47, 8 bit, big-endian, i-signal-type=PRIMITIVE, init-value=255, base-type=uint8, compu-method=CM_POD_DCInletTempB, data-constr=DC_POD_DCInletTempB, transfer-property=PENDING, to VCU  # Actual DC - temperatur connector
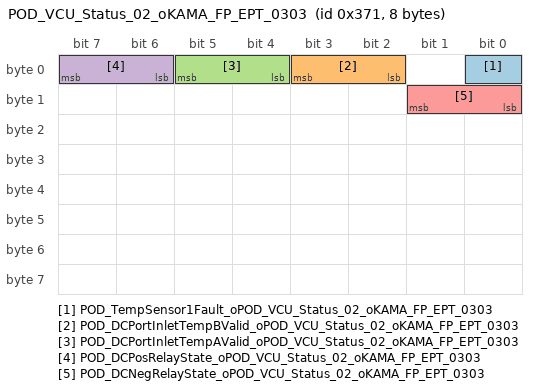
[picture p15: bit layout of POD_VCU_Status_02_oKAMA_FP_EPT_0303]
      frame POD_VCU_Status_02_oKAMA_FP_EPT_0303: id 0x371, to VCU, frame-length=8, can-addressing-mode=STANDARD
        pdu POD_VCU_Status_02_oKAMA_FP_EPT_0303: length=8, minimum-delay=0, transmission-mode-false-timing=cyclic-timing={time-offset=0, time-period=0.1}, transmission-mode-true-timing=cyclic-timing={time-offset=0, time-period=0.1}, unused-bit-pattern=0
          signal POD_TempSensor1Fault_oPOD_VCU_Status_02_oKAMA_FP_EPT_0303: start 0, 1 bit, big-endian, i-signal-type=PRIMITIVE, init-value=0, base-type=boolean, compu-method=CM_POD_TempSensor1Fault, data-constr=DC_POD_TempSensor1Fault, transfer-property=PENDING, to VCU  # POD temperature fault of the temporature Coolant outlet or structure
          signal POD_DCPortInletTempBValid_oPOD_VCU_Status_02_oKAMA_FP_EPT_0303: start 3, 2 bit, big-endian, i-signal-type=PRIMITIVE, init-value=0, base-type=uint8, compu-method=CM_POD_DCPortInletTempBValid, data-constr=DC_POD_DCPortInletTempBValid, transfer-property=PENDING, to VCU  # Error state for the temperature sensor. E.g. damaged or short circuit at the temperature sensor in the inlet.
          signal POD_DCPortInletTempAValid_oPOD_VCU_Status_02_oKAMA_FP_EPT_0303: start 5, 2 bit, big-endian, i-signal-type=PRIMITIVE, init-value=0, base-type=uint8, compu-method=CM_POD_DCPortInletTempAValid, data-constr=DC_POD_DCPortInletTempAValid, transfer-property=PENDING, to VCU  # Error state for the temperature sensor. E.g. damaged or short circuit at the temperature sensor in the inlet.
          signal POD_DCPosRelayState_oPOD_VCU_Status_02_oKAMA_FP_EPT_0303: start 7, 2 bit, big-endian, i-signal-type=PRIMITIVE, init-value=0, base-type=uint8, compu-method=CM_POD_DCPosRelayState, data-constr=DC_POD_DCPosRelayState, transfer-property=PENDING, to VCU  # Give feedback of DC charge positive relay state
          signal POD_DCNegRelayState_oPOD_VCU_Status_02_oKAMA_FP_EPT_0303: start 9, 2 bit, big-endian, i-signal-type=PRIMITIVE, init-value=0, base-type=uint8, compu-method=CM_POD_DCNegRelayState, data-constr=DC_POD_DCNegRelayState, transfer-property=PENDING, to VCU  # Give feedback of DC charge negative relay state
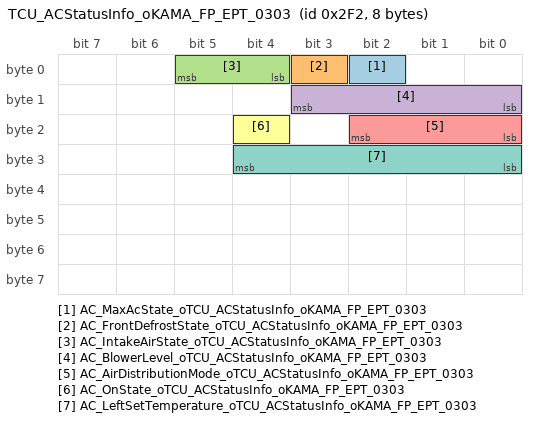
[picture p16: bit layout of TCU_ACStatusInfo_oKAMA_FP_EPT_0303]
      frame TCU_ACStatusInfo_oKAMA_FP_EPT_0303: id 0x2F2, to VCU, frame-length=8, can-addressing-mode=STANDARD
        pdu TCU_ACStatusInfo_oKAMA_FP_EPT_0303: length=8, minimum-delay=0, transmission-mode-false-timing=cyclic-timing={time-offset=0, time-period=0.1}, transmission-mode-true-timing=cyclic-timing={time-offset=0, time-period=0.1}, unused-bit-pattern=0
          signal AC_MaxAcState_oTCU_ACStatusInfo_oKAMA_FP_EPT_0303: start 2, 1 bit, big-endian, i-signal-type=PRIMITIVE, init-value=0, base-type=boolean, compu-method=CM_AC_MaxAcState, data-constr=DC_AC_MaxAcState, transfer-property=PENDING, to VCU  # ×î´óÖÆÀä×´Ì¬
          signal AC_FrontDefrostState_oTCU_ACStatusInfo_oKAMA_FP_EPT_0303: start 3, 1 bit, big-endian, i-signal-type=PRIMITIVE, init-value=0, base-type=boolean, compu-method=CM_AC_FrontDefrostState, data-constr=DC_AC_FrontDefrostState, transfer-property=PENDING, to VCU  # ³ýËª×´Ì¬
          signal AC_IntakeAirState_oTCU_ACStatusInfo_oKAMA_FP_EPT_0303: start 5, 2 bit, big-endian, i-signal-type=PRIMITIVE, init-value=0, base-type=uint8, compu-method=CM_AC_IntakeAirState, data-constr=DC_AC_IntakeAirState, transfer-property=PENDING, to VCU  # ÄÚÍâÑ­»·½øÆø
          signal AC_BlowerLevel_oTCU_ACStatusInfo_oKAMA_FP_EPT_0303: start 11, 4 bit, big-endian, i-signal-type=PRIMITIVE, init-value=0, base-type=uint8, compu-method=CM_AC_BlowerLevel, data-constr=DC_AC_BlowerLevel, transfer-property=PENDING, to VCU  # ´µ·çµµÎ»
          signal AC_AirDistributionMode_oTCU_ACStatusInfo_oKAMA_FP_EPT_0303: start 18, 3 bit, big-endian, i-signal-type=PRIMITIVE, init-value=0, base-type=uint8, compu-method=CM_AC_AirDistributionMode, data-constr=DC_AC_AirDistributionMode, transfer-property=PENDING, to VCU  # ´µ·çÄ£Ê½
          signal AC_OnState_oTCU_ACStatusInfo_oKAMA_FP_EPT_0303: start 20, 1 bit, big-endian, i-signal-type=PRIMITIVE, init-value=0, base-type=boolean, compu-method=CM_AC_OnState, data-constr=DC_AC_OnState, transfer-property=PENDING, to VCU  # ¿Õµ÷¿ªÆô×´Ì¬
          signal AC_LeftSetTemperature_oTCU_ACStatusInfo_oKAMA_FP_EPT_0303: start 28, 5 bit, big-endian, i-signal-type=PRIMITIVE, init-value=10, base-type=uint8, compu-method=CM_AC_LeftSetTemperature, data-constr=DC_AC_LeftSetTemperature, transfer-property=PENDING, to VCU  # Éè¶¨ÎÂ¶È
      frame TCU_AmbientTemp_oKAMA_FP_EPT_0303: id 0x2C2, to VCU, frame-length=8, can-addressing-mode=STANDARD
        pdu TCU_AmbientTemp_oKAMA_FP_EPT_0303: length=8, minimum-delay=0, transmission-mode-false-timing=cyclic-timing={time-offset=0, time-period=0.1}, transmission-mode-true-timing=cyclic-timing={time-offset=0, time-period=0.1}, unused-bit-pattern=0
          signal TCU_AmbientTemperature_oTCU_AmbientTemp_oKAMA_FP_EPT_0303: start 7, 8 bit, big-endian, i-signal-type=PRIMITIVE, init-value=255, base-type=uint8, compu-method=CM_TCU_AmbientTemperature, data-constr=DC_TCU_AmbientTemperature, transfer-property=PENDING, to VCU
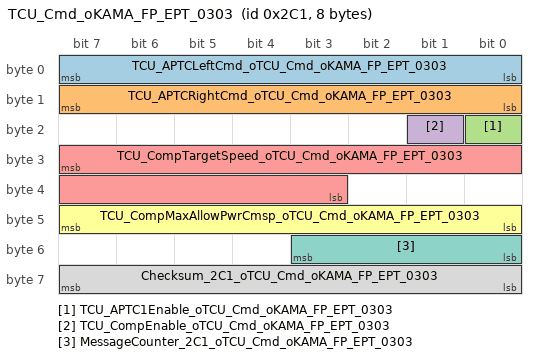
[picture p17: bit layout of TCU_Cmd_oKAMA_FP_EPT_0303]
      frame TCU_Cmd_oKAMA_FP_EPT_0303: id 0x2C1, to VCU, frame-length=8, can-addressing-mode=STANDARD
        pdu TCU_Cmd_oKAMA_FP_EPT_0303: length=8, minimum-delay=0, transmission-mode-false-timing=cyclic-timing={time-offset=0, time-period=0.1}, transmission-mode-true-timing=cyclic-timing={time-offset=0, time-period=0.1}, unused-bit-pattern=0
          signal TCU_APTCLeftCmd_oTCU_Cmd_oKAMA_FP_EPT_0303: start 7, 8 bit, big-endian, i-signal-type=PRIMITIVE, init-value=0, base-type=uint8, compu-method=CM_TCU_APTCLeftCmd, data-constr=DC_TCU_APTCLeftCmd, unit=U_p, transfer-property=PENDING, to VCU  # Actual power output percent of APTC Left zone ¿ÕÆøPTC×óÇøÊä³ö°Ù·Ö±È
          signal TCU_APTCRightCmd_oTCU_Cmd_oKAMA_FP_EPT_0303: start 15, 8 bit, big-endian, i-signal-type=PRIMITIVE, init-value=0, base-type=uint8, compu-method=CM_TCU_APTCRightCmd, data-constr=DC_TCU_APTCRightCmd, unit=U_p, transfer-property=PENDING, to VCU  # Actual power output percent of APTC Right zone ¿ÕÆøPTCÓÒÇøÊä³ö°Ù·Ö±È
          signal TCU_APTC1Enable_oTCU_Cmd_oKAMA_FP_EPT_0303: start 16, 1 bit, big-endian, i-signal-type=PRIMITIVE, init-value=0, base-type=boolean, compu-method=CM_TCU_APTC1Enable, data-constr=DC_TCU_APTC1Enable, transfer-property=PENDING, to VCU  # Vehicle Speed too Fast Warning ³µÁ¾ËÙ¶È¹ý¿ìÌáÐÑ
          signal TCU_CompEnable_oTCU_Cmd_oKAMA_FP_EPT_0303: start 17, 1 bit, big-endian, i-signal-type=PRIMITIVE, init-value=0, base-type=boolean, compu-method=CM_TCU_CompEnable, data-constr=DC_TCU_CompEnable, transfer-property=PENDING, to VCU  # Compressor Operate Enable Command Ñ¹Ëõ»úÔËÐÐÊ¹ÄÜÃüÁî
          signal TCU_CompTargetSpeed_oTCU_Cmd_oKAMA_FP_EPT_0303: start 31, 13 bit, big-endian, i-signal-type=PRIMITIVE, init-value=0, base-type=sint16, compu-method=CM_TCU_CompTargetSpeed, data-constr=DC_TCU_CompTargetSpeed, unit=U_rpm, transfer-property=PENDING, to VCU  # Compressor Target Speed Ñ¹Ëõ»úÄ¿±ê×ªËÙ
          signal TCU_CompMaxAllowPwrCmsp_oTCU_Cmd_oKAMA_FP_EPT_0303: start 47, 8 bit, big-endian, i-signal-type=PRIMITIVE, init-value=0, base-type=sint8, compu-method=CM_TCU_CompMaxAllowPwrCmsp, data-constr=DC_TCU_CompMaxAllowPwrCmsp, unit=U_KW, transfer-property=PENDING, to VCU  # Compressor Maximum Allowed Power Comsuption Ñ¹Ëõ»ú×î´óÔÊÐíÏûºÄ¹¦ÂÊ
          signal MessageCounter_2C1_oTCU_Cmd_oKAMA_FP_EPT_0303: start 51, 4 bit, big-endian, i-signal-type=PRIMITIVE, init-value=0, base-type=sint8, compu-method=CM_MessageCounter_2C1, data-constr=DC_MessageCounter_2C1, transfer-property=PENDING, to VCU  # Message Alive Counter
          signal Checksum_2C1_oTCU_Cmd_oKAMA_FP_EPT_0303: start 63, 8 bit, big-endian, i-signal-type=PRIMITIVE, init-value=0, base-type=sint8, compu-method=CM_Checksum_2C1, data-constr=DC_Checksum_2C1, transfer-property=PENDING, to VCU  # Message Checksum Protected data range starts from bit 0 to bit 55.
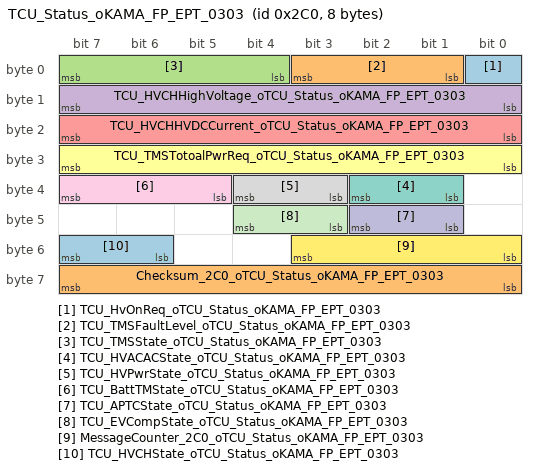
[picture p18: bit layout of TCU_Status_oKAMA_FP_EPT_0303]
      frame TCU_Status_oKAMA_FP_EPT_0303: id 0x2C0, to VCU, frame-length=8, can-addressing-mode=STANDARD
        pdu TCU_Status_oKAMA_FP_EPT_0303: length=8, minimum-delay=0, transmission-mode-false-timing=cyclic-timing={time-offset=0, time-period=0.1}, transmission-mode-true-timing=cyclic-timing={time-offset=0, time-period=0.1}, unused-bit-pattern=0
          signal TCU_HvOnReq_oTCU_Status_oKAMA_FP_EPT_0303: start 0, 1 bit, big-endian, i-signal-type=PRIMITIVE, init-value=0, base-type=boolean, compu-method=CM_TCU_HvOnReq, data-constr=DC_TCU_HvOnReq, transfer-property=PENDING, to VCU  # High voltage on request ¸ßÑ¹ÉÏµçÇëÇó
          signal TCU_TMSFaultLevel_oTCU_Status_oKAMA_FP_EPT_0303: start 3, 3 bit, big-endian, i-signal-type=PRIMITIVE, init-value=0, base-type=uint8, compu-method=CM_TCU_TMSFaultLevel, data-constr=DC_TCU_TMSFaultLevel, transfer-property=PENDING, to VCU  # TMS SYSTEM Error level
          signal TCU_TMSState_oTCU_Status_oKAMA_FP_EPT_0303: start 7, 4 bit, big-endian, i-signal-type=PRIMITIVE, init-value=0, base-type=uint8, compu-method=CM_TCU_TMSState, data-constr=DC_TCU_TMSState, transfer-property=PENDING, to VCU  # Thermal management control state
          signal TCU_HVCHHighVoltage_oTCU_Status_oKAMA_FP_EPT_0303: start 15, 8 bit, big-endian, i-signal-type=PRIMITIVE, init-value=0, base-type=uint8, compu-method=CM_TCU_HVCHHighVoltage, data-constr=DC_TCU_HVCHHighVoltage, unit=U_V, transfer-property=PENDING, to VCU  # HVCH High Voltage Measurement
          signal TCU_HVCHHVDCCurrent_oTCU_Status_oKAMA_FP_EPT_0303: start 23, 8 bit, big-endian, i-signal-type=PRIMITIVE, init-value=0, base-type=uint8, compu-method=CM_TCU_HVCHHVDCCurrent, data-constr=DC_TCU_HVCHHVDCCurrent, unit=U_A, transfer-property=PENDING, to VCU  # Current Draw of HV-PTC
          signal TCU_TMSTotoalPwrReq_oTCU_Status_oKAMA_FP_EPT_0303: start 31, 8 bit, big-endian, i-signal-type=PRIMITIVE, init-value=0, base-type=uint8, compu-method=CM_TCU_TMSTotoalPwrReq, data-constr=DC_TCU_TMSTotoalPwrReq, unit=U_w, transfer-property=PENDING, to VCU  # AC system total power request ¿Õµ÷ÏµÍ³×ÜÇëÇó¹¦ÂÊ
          signal TCU_HVACACState_oTCU_Status_oKAMA_FP_EPT_0303: start 34, 2 bit, big-endian, i-signal-type=PRIMITIVE, init-value=0, base-type=uint8, compu-method=CM_TCU_HVACACState, data-constr=DC_TCU_HVACACState, transfer-property=PENDING, to VCU  # Front HVAC Cool Or Heat Or Vent Auto State Ç°¿Õµ÷ÖÆÀäÖÆÈÈÍ¨·ç×Ô¶¯×´Ì¬
          signal TCU_HVPwrState_oTCU_Status_oKAMA_FP_EPT_0303: start 36, 2 bit, big-endian, i-signal-type=PRIMITIVE, init-value=0, base-type=uint8, compu-method=CM_TCU_HVPwrState, data-constr=DC_TCU_HVPwrState, transfer-property=PENDING, to VCU  # TCU High voltage supply Status TCUÏµÍ³¸ßÑ¹¹©µç×´Ì¬
          signal TCU_BattTMState_oTCU_Status_oKAMA_FP_EPT_0303: start 39, 3 bit, big-endian, i-signal-type=PRIMITIVE, init-value=0, base-type=uint8, compu-method=CM_TCU_BattTMState, data-constr=DC_TCU_BattTMState, transfer-property=PENDING, to VCU  # TCU battery Thermal management system status TCU µç³ØÈÈ¹ÜÀí×´Ì¬
          signal TCU_APTCState_oTCU_Status_oKAMA_FP_EPT_0303: start 42, 2 bit, big-endian, i-signal-type=PRIMITIVE, init-value=0, base-type=uint8, compu-method=CM_TCU_APTCState, data-constr=DC_TCU_APTCState, transfer-property=PENDING, to VCU  # Air heater work state ¿ÕÆø¼ÓÈÈÆ÷¹¤×÷×´Ì¬
          signal TCU_EVCompState_oTCU_Status_oKAMA_FP_EPT_0303: start 44, 2 bit, big-endian, i-signal-type=PRIMITIVE, init-value=0, base-type=uint8, compu-method=CM_TCU_EVCompState, data-constr=DC_TCU_EVCompState, transfer-property=PENDING, to VCU  # Compressor work state Ñ¹Ëõ»ú¹¤×÷×´Ì¬
          signal MessageCounter_2C0_oTCU_Status_oKAMA_FP_EPT_0303: start 51, 4 bit, big-endian, i-signal-type=PRIMITIVE, init-value=0, base-type=uint8, compu-method=CM_MessageCounter_2C0, data-constr=DC_MessageCounter_2C0, transfer-property=PENDING, to VCU  # Message counter signal for frame
          signal TCU_HVCHState_oTCU_Status_oKAMA_FP_EPT_0303: start 55, 2 bit, big-endian, i-signal-type=PRIMITIVE, init-value=0, base-type=uint8, compu-method=CM_TCU_HVCHState, data-constr=DC_TCU_HVCHState, transfer-property=PENDING, to VCU  # Water heater work state Ë®¼ÓÈÈÆ÷¹¤×÷×´Ì¬
          signal Checksum_2C0_oTCU_Status_oKAMA_FP_EPT_0303: start 63, 8 bit, big-endian, i-signal-type=PRIMITIVE, init-value=0, base-type=uint8, compu-method=CM_Checksum_2C0, data-constr=DC_Checksum_2C0, transfer-property=PENDING, to VCU  # Checksum signal for frame
      frame Uds_EPT_Boot_Request_oKAMA_FP_EPT_0303: id 0x711, to VCU, frame-length=8, can-addressing-mode=STANDARD
        pdu Uds_EPT_Boot_Request_oKAMA_FP_EPT_0303: length=8, minimum-delay=0, transmission-mode-false-timing=cyclic-timing={time-offset=0, time-period=0.01}, transmission-mode-true-timing=cyclic-timing={time-offset=0, time-period=0.01}, unused-bit-pattern=0
          signal UDS_EPT_BootCmd1_oUds_EPT_Boot_Request_oKAMA_FP_EPT_0303: start 0, 8 bit, little-endian, i-signal-type=PRIMITIVE, init-value=0, base-type=uint8, compu-method=CM_UDS_EPT_BootCmd1, data-constr=DC_UDS_EPT_BootCmd1, transfer-property=PENDING, to VCU
          signal UDS_EPT_BootCmd2_oUds_EPT_Boot_Request_oKAMA_FP_EPT_0303: start 8, 8 bit, little-endian, i-signal-type=PRIMITIVE, init-value=0, base-type=uint8, compu-method=CM_UDS_EPT_BootCmd2, data-constr=DC_UDS_EPT_BootCmd2, transfer-property=PENDING, to VCU
          signal UDS_EPT_BootCmd3_oUds_EPT_Boot_Request_oKAMA_FP_EPT_0303: start 16, 8 bit, little-endian, i-signal-type=PRIMITIVE, init-value=0, base-type=uint8, compu-method=CM_UDS_EPT_BootCmd3, data-constr=DC_UDS_EPT_BootCmd3, transfer-property=PENDING, to VCU
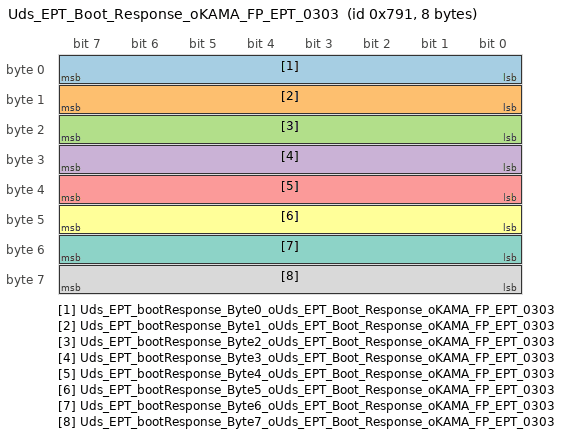
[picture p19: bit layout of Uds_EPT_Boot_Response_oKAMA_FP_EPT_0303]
      frame Uds_EPT_Boot_Response_oKAMA_FP_EPT_0303: id 0x791, from VCU, frame-length=8, can-addressing-mode=STANDARD
        pdu Uds_EPT_Boot_Response_oKAMA_FP_EPT_0303: length=8, minimum-delay=0, transmission-mode-false-timing=event-controlled-timing={number-of-repetitions=0, repetition-period=0}, transmission-mode-true-timing=event-controlled-timing={number-of-repetitions=0, repetition-period=0}, unused-bit-pattern=0
          signal Uds_EPT_bootResponse_Byte0_oUds_EPT_Boot_Response_oKAMA_FP_EPT_0303: start 0, 8 bit, little-endian, i-signal-type=PRIMITIVE, init-value=0, base-type=uint8, compu-method=CM_Uds_EPT_bootResponse_Byte0, data-constr=DC_Uds_EPT_bootResponse_Byte0, transfer-property=TRIGGERED-WITHOUT-REPETITION
          signal Uds_EPT_bootResponse_Byte1_oUds_EPT_Boot_Response_oKAMA_FP_EPT_0303: start 8, 8 bit, little-endian, i-signal-type=PRIMITIVE, init-value=0, base-type=uint8, compu-method=CM_Uds_EPT_bootResponse_Byte1, data-constr=DC_Uds_EPT_bootResponse_Byte1, transfer-property=TRIGGERED-WITHOUT-REPETITION
          signal Uds_EPT_bootResponse_Byte2_oUds_EPT_Boot_Response_oKAMA_FP_EPT_0303: start 16, 8 bit, little-endian, i-signal-type=PRIMITIVE, init-value=0, base-type=uint8, compu-method=CM_Uds_EPT_bootResponse_Byte2, data-constr=DC_Uds_EPT_bootResponse_Byte2, transfer-property=TRIGGERED-WITHOUT-REPETITION
          signal Uds_EPT_bootResponse_Byte3_oUds_EPT_Boot_Response_oKAMA_FP_EPT_0303: start 24, 8 bit, little-endian, i-signal-type=PRIMITIVE, init-value=0, base-type=uint8, compu-method=CM_Uds_EPT_bootResponse_Byte3, data-constr=DC_Uds_EPT_bootResponse_Byte3, transfer-property=TRIGGERED-WITHOUT-REPETITION
          signal Uds_EPT_bootResponse_Byte4_oUds_EPT_Boot_Response_oKAMA_FP_EPT_0303: start 32, 8 bit, little-endian, i-signal-type=PRIMITIVE, init-value=0, base-type=uint8, compu-method=CM_Uds_EPT_bootResponse_Byte4, data-constr=DC_Uds_EPT_bootResponse_Byte4, transfer-property=TRIGGERED-WITHOUT-REPETITION
          signal Uds_EPT_bootResponse_Byte5_oUds_EPT_Boot_Response_oKAMA_FP_EPT_0303: start 40, 8 bit, little-endian, i-signal-type=PRIMITIVE, init-value=0, base-type=uint8, compu-method=CM_Uds_EPT_bootResponse_Byte5, data-constr=DC_Uds_EPT_bootResponse_Byte5, transfer-property=TRIGGERED-WITHOUT-REPETITION
          signal Uds_EPT_bootResponse_Byte6_oUds_EPT_Boot_Response_oKAMA_FP_EPT_0303: start 48, 8 bit, little-endian, i-signal-type=PRIMITIVE, init-value=0, base-type=uint8, compu-method=CM_Uds_EPT_bootResponse_Byte6, data-constr=DC_Uds_EPT_bootResponse_Byte6, transfer-property=TRIGGERED-WITHOUT-REPETITION
          signal Uds_EPT_bootResponse_Byte7_oUds_EPT_Boot_Response_oKAMA_FP_EPT_0303: start 56, 8 bit, little-endian, i-signal-type=PRIMITIVE, init-value=0, base-type=uint8, compu-method=CM_Uds_EPT_bootResponse_Byte7, data-constr=DC_Uds_EPT_bootResponse_Byte7, transfer-property=TRIGGERED-WITHOUT-REPETITION
      frame UDSFunRequest_oKAMA_FP_EPT_0303: id 0x7DF, to VCU, frame-length=8, can-addressing-mode=STANDARD
        n pdu UDSFunRequest_Tp_oKAMA_FP_EPT_0303: length=8
      frame UDSRequest_oKAMA_FP_EPT_0303: id 0x7AC, to VCU, frame-length=8, can-addressing-mode=STANDARD
        n pdu UDSRequest_Tp_oKAMA_FP_EPT_0303: length=8
      frame UDSResponse_oKAMA_FP_EPT_0303: id 0x72C, from VCU, frame-length=8, can-addressing-mode=STANDARD
        n pdu UDSResponse_Tp_oKAMA_FP_EPT_0303: length=8
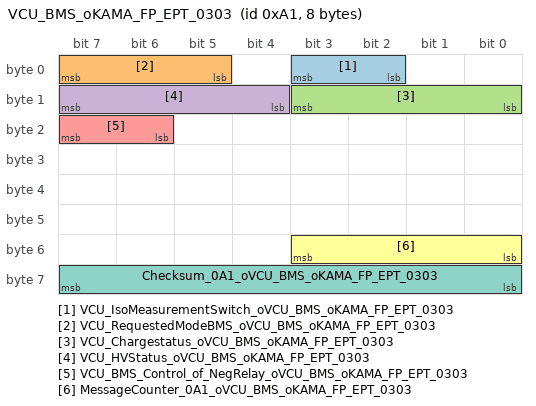
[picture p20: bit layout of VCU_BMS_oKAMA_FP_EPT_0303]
      frame VCU_BMS_oKAMA_FP_EPT_0303: id 0xA1, from VCU, frame-length=8, can-addressing-mode=STANDARD
        pdu VCU_BMS_oKAMA_FP_EPT_0303: length=8, minimum-delay=0, transmission-mode-false-timing=cyclic-timing={time-offset=0, time-period=0.02}, transmission-mode-true-timing=cyclic-timing={time-offset=0, time-period=0.02}, unused-bit-pattern=0
          signal VCU_IsoMeasurementSwitch_oVCU_BMS_oKAMA_FP_EPT_0303: start 3, 2 bit, big-endian, i-signal-type=PRIMITIVE, init-value=0, base-type=uint8, compu-method=CM_VCU_IsoMeasurementSwitch, data-constr=DC_VCU_IsoMeasurementSwitch, transfer-property=PENDING  # Isolation measurement switch
          signal VCU_RequestedModeBMS_oVCU_BMS_oKAMA_FP_EPT_0303: start 7, 3 bit, big-endian, i-signal-type=PRIMITIVE, init-value=0, base-type=uint8, compu-method=CM_VCU_RequestedModeBMS, data-constr=DC_VCU_RequestedModeBMS, transfer-property=PENDING  # Interface to request eletric energy storage target mode
          signal VCU_Chargestatus_oVCU_BMS_oKAMA_FP_EPT_0303: start 11, 4 bit, big-endian, i-signal-type=PRIMITIVE, init-value=0, base-type=uint8, compu-method=CM_VCU_Chargestatus, data-constr=DC_VCU_Chargestatus, transfer-property=PENDING  # Charge state
          signal VCU_HVStatus_oVCU_BMS_oKAMA_FP_EPT_0303: start 15, 4 bit, big-endian, i-signal-type=PRIMITIVE, init-value=0, base-type=uint8, compu-method=CM_VCU_HVStatus, data-constr=DC_VCU_HVStatus, transfer-property=PENDING  # HV System state
          signal VCU_BMS_Control_of_NegRelay_oVCU_BMS_oKAMA_FP_EPT_0303: start 23, 2 bit, big-endian, i-signal-type=PRIMITIVE, init-value=0, base-type=uint8, compu-method=CM_VCU_BMS_Control_of_NegRelay, data-constr=DC_VCU_BMS_Control_of_NegRelay, transfer-property=PENDING  # Negtive Relay state
          signal MessageCounter_0A1_oVCU_BMS_oKAMA_FP_EPT_0303: start 51, 4 bit, big-endian, i-signal-type=PRIMITIVE, init-value=0, base-type=uint8, compu-method=CM_MessageCounter_0A1, data-constr=DC_MessageCounter_0A1, transfer-property=PENDING  # Message counter signal for frame
          signal Checksum_0A1_oVCU_BMS_oKAMA_FP_EPT_0303: start 63, 8 bit, big-endian, i-signal-type=PRIMITIVE, init-value=0, base-type=uint8, compu-method=CM_Checksum_0A1, data-constr=DC_Checksum_0A1, transfer-property=PENDING  # Checksum signal for frame
      frame VCU_DCDC_oKAMA_FP_EPT_0303: id 0x273, from VCU, frame-length=8, can-addressing-mode=STANDARD
        pdu VCU_DCDC_oKAMA_FP_EPT_0303: length=8, minimum-delay=0, transmission-mode-false-timing=cyclic-timing={time-offset=0, time-period=0.1}, transmission-mode-true-timing=cyclic-timing={time-offset=0, time-period=0.1}, unused-bit-pattern=0
          signal VCU_VoltageDemandLV_oVCU_DCDC_oKAMA_FP_EPT_0303: start 7, 9 bit, big-endian, i-signal-type=PRIMITIVE, init-value=0, base-type=uint16, compu-method=CM_VCU_VoltageDemandLV, data-constr=DC_VCU_VoltageDemandLV, unit=U_V, transfer-property=PENDING  # Desired voltage of the DCDC converter LV side (buck mode 13.8v)
          signal VCU_ModeRequestDCDC_oVCU_DCDC_oKAMA_FP_EPT_0303: start 14, 3 bit, big-endian, i-signal-type=PRIMITIVE, init-value=0, base-type=uint8, compu-method=CM_VCU_ModeRequestDCDC, data-constr=DC_VCU_ModeRequestDCDC, transfer-property=PENDING  # Requested state of the DCDC converter
          signal MessageCounter_273_oVCU_DCDC_oKAMA_FP_EPT_0303: start 51, 4 bit, big-endian, i-signal-type=PRIMITIVE, init-value=0, base-type=uint8, compu-method=CM_MessageCounter_273, data-constr=DC_MessageCounter_273, transfer-property=PENDING  # Alive Counter_xxx
          signal Checksum_273_oVCU_DCDC_oKAMA_FP_EPT_0303: start 63, 8 bit, big-endian, i-signal-type=PRIMITIVE, init-value=0, base-type=uint8, compu-method=CM_Checksum_273, data-constr=DC_Checksum_273, transfer-property=PENDING  # CRC-XXX
      frame VCU_Fault_01_oKAMA_FP_EPT_0303: id 0x3B5, from VCU, frame-length=8, can-addressing-mode=STANDARD
        pdu VCU_Fault_01_oKAMA_FP_EPT_0303: length=8, minimum-delay=0, transmission-mode-false-timing=cyclic-timing={time-offset=0, time-period=0.01}, transmission-mode-true-timing=cyclic-timing={time-offset=0, time-period=0.01}, unused-bit-pattern=0
          signal PWT_ErrorLevel_oVCU_Fault_01_oKAMA_FP_EPT_0303: start 15, 4 bit, big-endian, i-signal-type=PRIMITIVE, init-value=0, base-type=uint8, compu-method=CM_PWT_ErrorLevel, data-constr=DC_PWT_ErrorLevel, transfer-property=PENDING
          signal VCU_CriSysFailure_oVCU_Fault_01_oKAMA_FP_EPT_0303: start 25, 2 bit, big-endian, i-signal-type=PRIMITIVE, init-value=0, base-type=uint8, compu-method=CM_VCU_CriSysFailure, data-constr=DC_VCU_CriSysFailure, transfer-property=PENDING  # System failure tell-tale: GB/T 4094.2, Table 2, No. 3
          signal VCU_LimpHome_oVCU_Fault_01_oKAMA_FP_EPT_0303: start 30, 1 bit, big-endian, i-signal-type=PRIMITIVE, init-value=0, base-type=boolean, compu-method=CM_VCU_LimpHome, data-constr=DC_VCU_LimpHome, transfer-property=PENDING  # Limp home: GB/T 4094.2, Table 1, No. 3
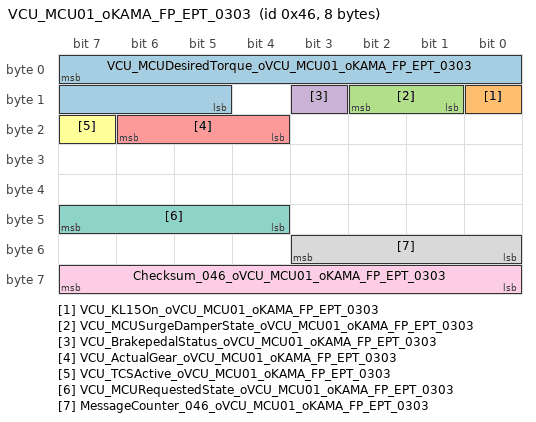
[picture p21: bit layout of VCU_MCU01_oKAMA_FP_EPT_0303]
      frame VCU_MCU01_oKAMA_FP_EPT_0303: id 0x46, from VCU, frame-length=8, can-addressing-mode=STANDARD
        pdu VCU_MCU01_oKAMA_FP_EPT_0303: length=8, minimum-delay=0, transmission-mode-false-timing=cyclic-timing={time-offset=0, time-period=0.01}, transmission-mode-true-timing=cyclic-timing={time-offset=0, time-period=0.01}, unused-bit-pattern=0
          signal VCU_MCUDesiredTorque_oVCU_MCU01_oKAMA_FP_EPT_0303: start 7, 11 bit, big-endian, i-signal-type=PRIMITIVE, init-value=1023, base-type=uint16, compu-method=CM_VCU_MCUDesiredTorque, data-constr=DC_VCU_MCUDesiredTorque, unit=U_Nm, transfer-property=PENDING  # Desired torque electric machine
          signal VCU_KL15On_oVCU_MCU01_oKAMA_FP_EPT_0303: start 8, 1 bit, big-endian, i-signal-type=PRIMITIVE, init-value=0, base-type=boolean, compu-method=CM_VCU_KL15On, data-constr=DC_VCU_KL15On, transfer-property=PENDING  # the bit status of KL15 signal
          signal VCU_MCUSurgeDamperState_oVCU_MCU01_oKAMA_FP_EPT_0303: start 10, 2 bit, big-endian, i-signal-type=PRIMITIVE, init-value=0, base-type=uint8, compu-method=CM_VCU_MCUSurgeDamperState, data-constr=DC_VCU_MCUSurgeDamperState, unit=U_SED, transfer-property=PENDING  # Requested surge damper state
          signal VCU_BrakepedalStatus_oVCU_MCU01_oKAMA_FP_EPT_0303: start 11, 1 bit, big-endian, i-signal-type=PRIMITIVE, init-value=0, base-type=boolean, compu-method=CM_VCU_BrakepedalStatus, data-constr=DC_VCU_BrakepedalStatus, transfer-property=PENDING  # the break pedal statusÉ²³µÌ¤°å×´Ì¬
          signal VCU_ActualGear_oVCU_MCU01_oKAMA_FP_EPT_0303: start 22, 3 bit, big-endian, i-signal-type=PRIMITIVE, init-value=0, base-type=uint8, compu-method=CM_VCU_ActualGear, data-constr=DC_VCU_ActualGear, transfer-property=PENDING
          signal VCU_TCSActive_oVCU_MCU01_oKAMA_FP_EPT_0303: start 23, 1 bit, big-endian, i-signal-type=PRIMITIVE, init-value=0, base-type=boolean, compu-method=CM_VCU_TCSActive, data-constr=DC_VCU_TCSActive, transfer-property=PENDING  # EN:Tindicates TCS intervention active£¬TCS will detect spinning wheels and request torque reduction/limitation CH:CS¼¤»î±êÖ¾Î»
          signal VCU_MCURequestedState_oVCU_MCU01_oKAMA_FP_EPT_0303: start 47, 4 bit, big-endian, i-signal-type=PRIMITIVE, init-value=0, base-type=uint8, compu-method=CM_VCU_MCURequestedState, data-constr=DC_VCU_MCURequestedState, transfer-property=PENDING  # Request to the electric machine
          signal MessageCounter_046_oVCU_MCU01_oKAMA_FP_EPT_0303: start 51, 4 bit, big-endian, i-signal-type=PRIMITIVE, init-value=0, base-type=uint8, compu-method=CM_MessageCounter_046, data-constr=DC_MessageCounter_046, transfer-property=PENDING  # the rolling counter of VCU02
          signal Checksum_046_oVCU_MCU01_oKAMA_FP_EPT_0303: start 63, 8 bit, big-endian, i-signal-type=PRIMITIVE, init-value=0, base-type=uint8, compu-method=CM_Checksum_046, data-constr=DC_Checksum_046, transfer-property=PENDING  # the checksum of VCU02
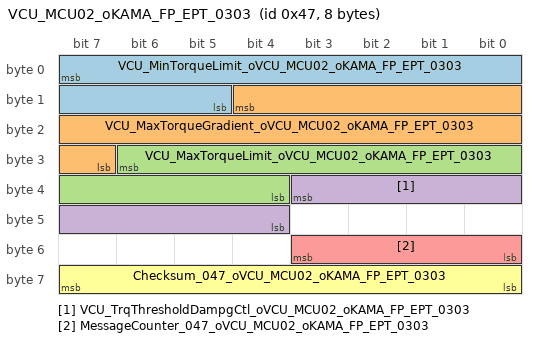
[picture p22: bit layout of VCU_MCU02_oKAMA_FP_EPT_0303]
      frame VCU_MCU02_oKAMA_FP_EPT_0303: id 0x47, from VCU, frame-length=8, can-addressing-mode=STANDARD
        pdu VCU_MCU02_oKAMA_FP_EPT_0303: length=8, minimum-delay=0, transmission-mode-false-timing=cyclic-timing={time-offset=0, time-period=0.02}, transmission-mode-true-timing=cyclic-timing={time-offset=0, time-period=0.02}, unused-bit-pattern=0
          signal VCU_MinTorqueLimit_oVCU_MCU02_oKAMA_FP_EPT_0303: start 7, 11 bit, big-endian, i-signal-type=PRIMITIVE, init-value=1023, base-type=uint16, compu-method=CM_VCU_MinTorqueLimit, data-constr=DC_VCU_MinTorqueLimit, unit=U_Nm, transfer-property=PENDING  # Lower limit output torque of electric machine
          signal VCU_MaxTorqueGradient_oVCU_MCU02_oKAMA_FP_EPT_0303: start 12, 14 bit, big-endian, i-signal-type=PRIMITIVE, init-value=0, base-type=uint16, compu-method=CM_VCU_MaxTorqueGradient, data-constr=DC_VCU_MaxTorqueGradient, unit=U_NmYs, transfer-property=PENDING  # Maximum allowed change rate of actual torque
          signal VCU_MaxTorqueLimit_oVCU_MCU02_oKAMA_FP_EPT_0303: start 30, 11 bit, big-endian, i-signal-type=PRIMITIVE, init-value=1023, base-type=uint16, compu-method=CM_VCU_MaxTorqueLimit, data-constr=DC_VCU_MaxTorqueLimit, unit=U_Nm, transfer-property=PENDING  # Upper limit output torque of electric machine
          signal VCU_TrqThresholdDampgCtl_oVCU_MCU02_oKAMA_FP_EPT_0303: start 35, 8 bit, big-endian, i-signal-type=PRIMITIVE, init-value=0, base-type=uint8, compu-method=CM_VCU_TrqThresholdDampgCtl, data-constr=DC_VCU_TrqThresholdDampgCtl, unit=U_Nm, transfer-property=PENDING  # Threshold torque for damping control
          signal MessageCounter_047_oVCU_MCU02_oKAMA_FP_EPT_0303: start 51, 4 bit, big-endian, i-signal-type=PRIMITIVE, init-value=0, base-type=uint8, compu-method=CM_MessageCounter_047, data-constr=DC_MessageCounter_047, transfer-property=PENDING  # the rolling counter of VCU01
          signal Checksum_047_oVCU_MCU02_oKAMA_FP_EPT_0303: start 63, 8 bit, big-endian, i-signal-type=PRIMITIVE, init-value=0, base-type=uint8, compu-method=CM_Checksum_047, data-constr=DC_Checksum_047, transfer-property=PENDING  # the checksum of VCU01
      frame VCU_Mileage_oKAMA_FP_EPT_0303: id 0x3B6, from VCU, frame-length=8, can-addressing-mode=STANDARD
        pdu VCU_Mileage_oKAMA_FP_EPT_0303: length=8, minimum-delay=0, transmission-mode-false-timing=cyclic-timing={time-offset=0, time-period=0.1}, transmission-mode-true-timing=cyclic-timing={time-offset=0, time-period=0.1}, unused-bit-pattern=0
          signal VCU_MCUPower_oVCU_Mileage_oKAMA_FP_EPT_0303: start 7, 9 bit, big-endian, i-signal-type=PRIMITIVE, init-value=200, base-type=uint16, compu-method=CM_VCU_MCUPower, data-constr=DC_VCU_MCUPower, unit=U_kW, transfer-property=PENDING  # Real-time power consumption of motor
          signal VCU_AvaDrvRange_oVCU_Mileage_oKAMA_FP_EPT_0303: start 23, 9 bit, big-endian, i-signal-type=PRIMITIVE, init-value=0, base-type=uint16, compu-method=CM_VCU_AvaDrvRange, data-constr=DC_VCU_AvaDrvRange, unit=U_km, transfer-property=PENDING  # Available driving range to the user.
          signal VCU_DynamicMileage_oVCU_Mileage_oKAMA_FP_EPT_0303: start 39, 9 bit, big-endian, i-signal-type=PRIMITIVE, init-value=0, base-type=uint16, compu-method=CM_VCU_DynamicMileage, data-constr=DC_VCU_DynamicMileage, unit=U_Km, transfer-property=PENDING  # Dynamic driving range
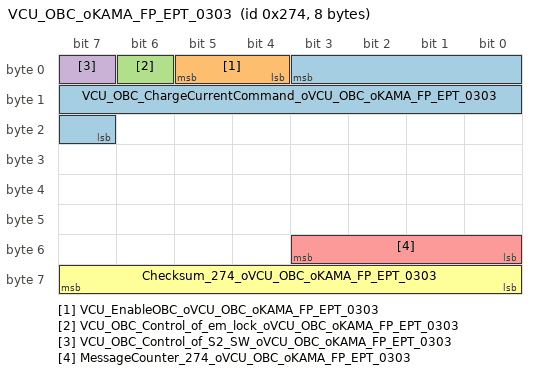
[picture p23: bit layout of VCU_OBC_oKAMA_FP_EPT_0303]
      frame VCU_OBC_oKAMA_FP_EPT_0303: id 0x274, from VCU, frame-length=8, can-addressing-mode=STANDARD
        pdu VCU_OBC_oKAMA_FP_EPT_0303: length=8, minimum-delay=0, transmission-mode-false-timing=cyclic-timing={time-offset=0, time-period=0.1}, transmission-mode-true-timing=cyclic-timing={time-offset=0, time-period=0.1}, unused-bit-pattern=0
          signal VCU_OBC_ChargeCurrentCommand_oVCU_OBC_oKAMA_FP_EPT_0303: start 3, 13 bit, big-endian, i-signal-type=PRIMITIVE, init-value=0, base-type=uint16, compu-method=CM_VCU_OBC_ChargeCurrentCommand, data-constr=DC_VCU_OBC_ChargeCurrentCommand, unit=U_A, transfer-property=PENDING  # OBC output charging current according to this signal.
          signal VCU_EnableOBC_oVCU_OBC_oKAMA_FP_EPT_0303: start 5, 2 bit, big-endian, i-signal-type=PRIMITIVE, init-value=0, base-type=uint8, compu-method=CM_VCU_EnableOBC, data-constr=DC_VCU_EnableOBC, transfer-property=PENDING  # When VCU receiving OBC Charge Status=?Ready? and detecting the status of S2 is closed,VCU send enable; When VCU detect that the stop charging condition is met, VUC send disable.
          signal VCU_OBC_Control_of_em_lock_oVCU_OBC_oKAMA_FP_EPT_0303: start 6, 1 bit, big-endian, i-signal-type=PRIMITIVE, init-value=0, base-type=boolean, compu-method=CM_VCU_OBC_Control_of_em_lock, data-constr=DC_VCU_OBC_Control_of_em_lock, transfer-property=PENDING  # OBC should accept the control signal from VCU to lock or unlock the actuator in the Inlet for locking or unlocking the charging plug
          signal VCU_OBC_Control_of_S2_SW_oVCU_OBC_oKAMA_FP_EPT_0303: start 7, 1 bit, big-endian, i-signal-type=PRIMITIVE, init-value=0, base-type=boolean, compu-method=CM_VCU_OBC_Control_of_S2_SW, data-constr=DC_VCU_OBC_Control_of_S2_SW, transfer-property=PENDING  # OBC should accept the control signal from VCU to switch the S2 inside the OBC
          signal MessageCounter_274_oVCU_OBC_oKAMA_FP_EPT_0303: start 51, 4 bit, big-endian, i-signal-type=PRIMITIVE, init-value=0, base-type=uint8, compu-method=CM_MessageCounter_274, data-constr=DC_MessageCounter_274, transfer-property=PENDING  # Message counter signal for frame
          signal Checksum_274_oVCU_OBC_oKAMA_FP_EPT_0303: start 63, 8 bit, big-endian, i-signal-type=PRIMITIVE, init-value=0, base-type=uint8, compu-method=CM_Checksum_274, data-constr=DC_Checksum_274, transfer-property=PENDING  # Checksum signal for frame
      frame VCU_POD_oKAMA_FP_EPT_0303: id 0x275, from VCU, frame-length=8, can-addressing-mode=STANDARD
        pdu VCU_POD_oKAMA_FP_EPT_0303: length=8, minimum-delay=0, transmission-mode-false-timing=cyclic-timing={time-offset=0, time-period=0.05}, transmission-mode-true-timing=cyclic-timing={time-offset=0, time-period=0.05}, unused-bit-pattern=0
          signal VCU_Enable_DC_Relay_oVCU_POD_oKAMA_FP_EPT_0303: start 21, 1 bit, big-endian, i-signal-type=PRIMITIVE, init-value=0, base-type=boolean, compu-method=CM_VCU_Enable_DC_Relay, data-constr=DC_VCU_Enable_DC_Relay, transfer-property=PENDING  # enable: Request for closing DC charging relay
      frame VCU_TCU_oKAMA_FP_EPT_0303: id 0x276, from VCU, frame-length=8, can-addressing-mode=STANDARD
        pdu VCU_TCU_oKAMA_FP_EPT_0303: length=8, minimum-delay=0, transmission-mode-false-timing=cyclic-timing={time-offset=0, time-period=0.1}, transmission-mode-true-timing=cyclic-timing={time-offset=0, time-period=0.1}, unused-bit-pattern=0
          signal VCU_TCUPowerAllowed_oVCU_TCU_oKAMA_FP_EPT_0303: start 7, 8 bit, big-endian, i-signal-type=PRIMITIVE, init-value=0, base-type=uint8, compu-method=CM_VCU_TCUPowerAllowed, data-constr=DC_VCU_TCUPowerAllowed, unit=U_W, transfer-property=PENDING  # TCU Maximum Allowed Power Comsuption
          signal VCU_RequestedModeTCU_oVCU_TCU_oKAMA_FP_EPT_0303: start 15, 2 bit, big-endian, i-signal-type=PRIMITIVE, init-value=0, base-type=uint8, compu-method=CM_VCU_RequestedModeTCU, data-constr=DC_VCU_RequestedModeTCU, transfer-property=PENDING  # Requested mode of TCU
      pdu triggering PT_AllFunctionRequest: pdu=AllFunctionRequest_oKAMA_FP_EPT_0303, to VCU
      pdu triggering PT_OBDFunRequest: pdu=OBDFunRequest_oKAMA_FP_EPT_0303, to VCU
      pdu triggering PT_OBDRequest: pdu=OBDRequest_oKAMA_FP_EPT_0303, to VCU
      pdu triggering PT_OBDResponse: pdu=OBDResponse_oKAMA_FP_EPT_0303, from VCU
      pdu triggering PT_UDSFunRequest: pdu=UDSFunRequest_oKAMA_FP_EPT_0303, to VCU
      pdu triggering PT_UDSRequest: pdu=UDSRequest_oKAMA_FP_EPT_0303, to VCU
      pdu triggering PT_UDSResponse: pdu=UDSResponse_oKAMA_FP_EPT_0303, from VCU
package /ECU
  ecu instance VCU: associated-com-i-pdu-group=[VCU_oKAMA_FP_EPSChassis1_0303_Rx, VCU_oKAMA_FP_EPSChassis1_0303_Tx, VCU_oKAMA_FP_EPT_0303_Rx, VCU_oKAMA_FP_EPT_0303_Tx]
    can communication controller CT_KAMA_FP_EPSChassis1_0303
    can communication controller CT_KAMA_FP_EPT_0303
    can communication connector CN_KAMA_FP_EPSChassis1_0303: comm-controller=CT_KAMA_FP_EPSChassis1_0303
    can communication connector CN_KAMA_FP_EPT_0303: comm-controller=CT_KAMA_FP_EPT_0303
package /Gateway
  gateway VCU: ecu=VCU
package /IPDUGroup
  4 x i signal i pdu group:
    VCU_oKAMA_FP_EPSChassis1_0303_Rx: communication-direction=IN
      i-signal-i-pdus:
        ADAS_ACC_oKAMA_FP_EPSChassis1_0303
        ADAS_AEB_oKAMA_FP_EPSChassis1_0303
        ADAS_APA_oKAMA_FP_EPSChassis1_0303
        ADAS_CCU1_Ctrl_oKAMA_FP_EPSChassis1_0303
        DonorCar_ACM_Status_oKAMA_FP_EPSChassis1_0303
        DonorCar_BCM_LDoorWindowState_oKAMA_FP_EPSChassis1_0303
        DonorCar_GSM_oKAMA_FP_EPSChassis1_0303
        DonorCar_MMI_Status_Infor_oKAMA_FP_EPSChassis1_0303
        DonorCar_PEPS_Message_Sts_oKAMA_FP_EPSChassis1_0303
        EPS_FEEDBACK_oKAMA_FP_EPSChassis1_0303
        GW_TCU_AmbientTemp_oKAMA_FP_EPSChassis1_0303
        IBS_Status{1..3}_oKAMA_FP_EPSChassis1_0303
        IBS_Torque_oKAMA_FP_EPSChassis1_0303
        IBS_VCUVLC_oKAMA_FP_EPSChassis1_0303
        IBS_WheelPulse_oKAMA_FP_EPSChassis1_0303
        IBS_WheelSpeed_oKAMA_FP_EPSChassis1_0303
        IBS1_acceleration_oKAMA_FP_EPSChassis1_0303
        REPS_DM{1..3}_oKAMA_FP_EPSChassis1_0303
        YRS_1_oKAMA_FP_EPSChassis1_0303
        YRS_2_oKAMA_FP_EPSChassis1_0303
        YRS_7_oKAMA_FP_EPSChassis1_0303
    VCU_oKAMA_FP_EPSChassis1_0303_Tx: communication-direction=OUT
      i-signal-i-pdus:
        VCU_AccPedal_oKAMA_FP_EPSChassis1_0303
        VCU_chassis_oKAMA_FP_EPSChassis1_0303
        VCU_HMIsignals_oKAMA_FP_EPSChassis1_0303
        VCU_HVbattStatus1_oKAMA_FP_EPSChassis1_0303
        VCU_MCU_7A_oKAMA_FP_EPSChassis1_0303
        VCU_OdometerInfo_oKAMA_FP_EPSChassis1_0303
        VCU_PlugInChrgInfo1_oKAMA_FP_EPSChassis1_0303
        VCU_PlugInChrgInfo2_oKAMA_FP_EPSChassis1_0303
        VCU_PwrtrainHVbattStatus2_oKAMA_FP_EPSChassis1_0303
        VCU_PwrtrainRequests_oKAMA_FP_EPSChassis1_0303
    VCU_oKAMA_FP_EPT_0303_Rx: communication-direction=IN
      i-signal-i-pdus:
        APTC_TCU_oKAMA_FP_EPT_0303
        BMS_Batcode_oKAMA_FP_EPT_0303
        BMS_BatInfor1_oKAMA_FP_EPT_0303
        BMS_BatInfor2_oKAMA_FP_EPT_0303
        BMS_CellVoltage1_oKAMA_FP_EPT_0303
        BMS_Charge1_oKAMA_FP_EPT_0303
        BMS_ChargeEnergy_oKAMA_FP_EPT_0303
        BMS_ChargeStop_oKAMA_FP_EPT_0303
        BMS_CurrentLimit_oKAMA_FP_EPT_0303
        BMS_DIRelayState_oKAMA_FP_EPT_0303
        BMS_DisChargeEnergy_oKAMA_FP_EPT_0303
        BMS_ErrorInfo1_oKAMA_FP_EPT_0303
        BMS_Insulation_oKAMA_FP_EPT_0303
        BMS_PackVoltage_oKAMA_FP_EPT_0303
        BMS_PRO_oKAMA_FP_EPT_0303
        BMS_status_oKAMA_FP_EPT_0303
        BMS_TCU_oKAMA_FP_EPT_0303
        BMS_Temp_oKAMA_FP_EPT_0303
        BMS_VersionInfor_oKAMA_FP_EPT_0303
        DCDC_VCU_01_oKAMA_FP_EPT_0303
        DCDC_VCU_02_oKAMA_FP_EPT_0303
        DonorCar_MMI_AC_Command_oKAMA_FP_EPT_0303
        EVCOM_State_oKAMA_FP_EPT_0303
        GW_BCM_oKAMA_FP_EPT_0303
        MCU_DeratingStatus_oKAMA_FP_EPT_0303
        MCU_FailureCode_oKAMA_FP_EPT_0303
        MCU_HardwareNumber_oKAMA_FP_EPT_0303
        MCU_SoftwareNumber_oKAMA_FP_EPT_0303
        MCU_Status_oKAMA_FP_EPT_0303
        MCU_Temperature1_oKAMA_FP_EPT_0303
        MCU_Temperature2_oKAMA_FP_EPT_0303
        MCU_VCU_1_oKAMA_FP_EPT_0303
        OBC_Error_STATUS_oKAMA_FP_EPT_0303
        OBC_VCU_CHRGSTATION_ST_oKAMA_FP_EPT_0303
        OBC_VCU_STATUS1_oKAMA_FP_EPT_0303
        OBC_VCU_STATUS2_oKAMA_FP_EPT_0303
        POD_VCU_Status_01_oKAMA_FP_EPT_0303
        POD_VCU_Status_02_oKAMA_FP_EPT_0303
        TCU_ACStatusInfo_oKAMA_FP_EPT_0303
        TCU_AmbientTemp_oKAMA_FP_EPT_0303
        TCU_Cmd_oKAMA_FP_EPT_0303
        TCU_Status_oKAMA_FP_EPT_0303
        Uds_EPT_Boot_Request_oKAMA_FP_EPT_0303
    VCU_oKAMA_FP_EPT_0303_Tx: communication-direction=OUT
      i-signal-i-pdus:
        Uds_EPT_Boot_Response_oKAMA_FP_EPT_0303
        VCU_BMS_oKAMA_FP_EPT_0303
        VCU_DCDC_oKAMA_FP_EPT_0303
        VCU_Fault_01_oKAMA_FP_EPT_0303
        VCU_MCU01_oKAMA_FP_EPT_0303
        VCU_MCU02_oKAMA_FP_EPT_0303
        VCU_Mileage_oKAMA_FP_EPT_0303
        VCU_OBC_oKAMA_FP_EPT_0303
        VCU_POD_oKAMA_FP_EPT_0303
        VCU_TCU_oKAMA_FP_EPT_0303
package /PDU
  dcm i pdu AllFunctionRequest_oKAMA_FP_EPT_0303: length=7, diag-pdu-type=DIAG-REQUEST
  dcm i pdu OBDFunRequest_oKAMA_FP_EPT_0303: length=7, diag-pdu-type=DIAG-REQUEST
  dcm i pdu OBDRequest_oKAMA_FP_EPT_0303: length=8, diag-pdu-type=DIAG-REQUEST
  dcm i pdu OBDResponse_oKAMA_FP_EPT_0303: length=8, diag-pdu-type=DIAG-RESPONSE
  dcm i pdu UDSFunRequest_oKAMA_FP_EPT_0303: length=7, diag-pdu-type=DIAG-REQUEST
  dcm i pdu UDSRequest_oKAMA_FP_EPT_0303: length=8, diag-pdu-type=DIAG-REQUEST
  dcm i pdu UDSResponse_oKAMA_FP_EPT_0303: length=8, diag-pdu-type=DIAG-RESPONSE
